VERSION ""

NS_ :

BS_:

BU_: ESP dSpaceBox CALTOOL HED

BO_ 539 SAC_ERRORS: 8 HED
 SG_ SAC_E_MSW_AGE_WARN : 63|1@1+ (1,0) [0|1] ""  CALTOOL
 SG_ SAC_E_CELL_Over_Temperature : 62|1@1+ (1,0) [0|1] ""  CALTOOL
 SG_ SAC_E_CSC_Timeout : 61|1@1+ (1,0) [0|1] ""  CALTOOL
 SG_ SAC_E_CSC_Internal : 60|1@1+ (1,0) [0|1] ""  CALTOOL
 SG_ SAC_E_BAT_Over_Voltage : 59|1@1+ (1,0) [0|1] ""  CALTOOL
 SG_ SAC_E_PMB_Over_Current_discharg : 58|1@1+ (1,0) [0|1] ""  CALTOOL
 SG_ SAC_E_PMB_Over_Current_charge : 57|1@1+ (1,0) [0|1] ""  CALTOOL
 SG_ SAC_E_PMB_Over_Temperature_Shun : 56|1@1+ (1,0) [0|1] ""  CALTOOL
 SG_ SAC_E_MSW_AGE : 55|1@1+ (1,0) [0|1] ""  CALTOOL
 SG_ SAC_E_PMB_Internal : 54|1@1+ (1,0) [0|1] ""  CALTOOL
 SG_ SAC_E_SSV_WD : 53|1@1+ (1,0) [0|1] ""  CALTOOL
 SG_ SAC_E_SSV_Supply_Voltage : 52|1@1+ (1,0) [0|1] ""  CALTOOL
 SG_ SAC_E_FLASH_Monitor : 51|1@1+ (1,0) [0|1] ""  CALTOOL
 SG_ SAC_E_PMB_Emergency_short_sup : 50|1@1+ (1,0) [0|1] ""  CALTOOL
 SG_ SAC_E_SSV_Warning : 49|1@1+ (1,0) [0|1] ""  CALTOOL
 SG_ SAC_E_SSV_Emergency : 48|1@1+ (1,0) [0|1] ""  CALTOOL
 SG_ SAC_E_Ref_Voltage : 47|1@1+ (1,0) [0|1] ""  CALTOOL
 SG_ SAC_E_Supply_Voltage : 46|1@1+ (1,0) [0|1] ""  CALTOOL
 SG_ SAC_E_BCC_communication : 45|1@1+ (1,0) [0|1] ""  CALTOOL
 SG_ SAC_E_CSC_Emergency_short_sup : 44|1@1+ (1,0) [0|1] ""  CALTOOL
 SG_ SAC_E_SSV_CONFIG_HARD : 43|1@1+ (1,0) [0|1] ""  CALTOOL
 SG_ SAC_E_PMB_Warning : 41|1@1+ (1,0) [0|1] ""  CALTOOL
 SG_ SAC_E_STACK_Monitor : 40|1@1+ (1,0) [0|1] ""  CALTOOL
 SG_ SAC_E_RAM_Monitor : 39|1@1+ (1,0) [0|1] ""  CALTOOL
 SG_ SAC_E_ROM_Monitor : 38|1@1+ (1,0) [0|1] ""  CALTOOL
 SG_ SAC_E_Reset_Monitor : 37|1@1+ (1,0) [0|1] ""  CALTOOL
 SG_ SAC_E_CPU_Test : 36|1@1+ (1,0) [0|1] ""  CALTOOL
 SG_ SAC_E_WD : 35|1@1+ (1,0) [0|1] ""  CALTOOL
 SG_ SAC_E_Trac_Voltage : 34|1@1+ (1,0) [0|1] ""  CALTOOL
 SG_ SAC_E_HV_meas : 33|1@1+ (1,0) [0|1] ""  CALTOOL
 SG_ SAC_E_Lifedata : 32|1@1+ (1,0) [0|1] ""  CALTOOL
 SG_ SAC_E_NVRAM : 31|1@1+ (1,0) [0|1] ""  CALTOOL
 SG_ SAC_E_PMB_Limits : 30|1@1+ (1,0) [0|1] ""  CALTOOL
 SG_ SAC_E_PCB_Temperature : 29|1@1+ (1,0) [0|1] ""  CALTOOL
 SG_ SAC_E_Iso_measurement : 28|1@1+ (1,0) [0|1] ""  CALTOOL
 SG_ SAC_E_SSV_Interop : 27|1@1+ (1,0) [0|1] ""  CALTOOL
 SG_ SAC_E_PMB_Timeout : 26|1@1+ (1,0) [0|1] ""  CALTOOL
 SG_ SAC_E_Interlock_missing : 25|1@1+ (1,0) [0|1] ""  CALTOOL
 SG_ SAC_E_PMB_Emergency : 24|1@1+ (1,0) [0|1] ""  CALTOOL
 SG_ SAC_E_CSC_Emergency : 23|1@1+ (1,0) [0|1] ""  CALTOOL
 SG_ SAC_E_FLOW_CTR : 22|1@1+ (1,0) [0|1] ""  CALTOOL
 SG_ SAC_E_ACC_Emergency : 21|1@1+ (1,0) [0|1] ""  CALTOOL
 SG_ SAC_E_Iso_resistance : 20|1@1+ (1,0) [0|1] ""  CALTOOL
 SG_ SAC_E_SSV_Timeout : 19|1@1+ (1,0) [0|1] ""  CALTOOL
 SG_ SAC_E_CSC_Warning : 18|1@1+ (1,0) [0|1] ""  CALTOOL
 SG_ SAC_E_CELL_Under_Voltage : 17|1@1+ (1,0) [0|1] ""  CALTOOL
 SG_ SAC_E_CELL_Over_Voltage : 16|1@1+ (1,0) [0|1] ""  CALTOOL

BO_ 309 BCC_IN_T_BATT_05_06: 8 HED
 SG_ BCC_T_Batt_06 : 32|16@1- (0.01,0) [-327.68|327.67] "°C"  CALTOOL
 SG_ BCC_T_Batt_05 : 0|16@1- (0.01,0) [-327.68|327.67] "°C"  CALTOOL

BO_ 308 BCC_IN_T_BATT_03_04: 8 HED
 SG_ BCC_T_Batt_04 : 32|16@1- (0.01,0) [-327.68|327.67] "°C"  CALTOOL
 SG_ BCC_T_Batt_03 : 0|16@1- (0.01,0) [-327.68|327.67] "°C"  CALTOOL

BO_ 307 BCC_IN_T_BATT_01_02: 8 HED
 SG_ BCC_T_Batt_02 : 32|16@1- (0.01,0) [-327.68|327.67] "°C"  CALTOOL
 SG_ BCC_T_Batt_01 : 0|16@1- (0.01,0) [-327.68|327.67] "°C"  CALTOOL

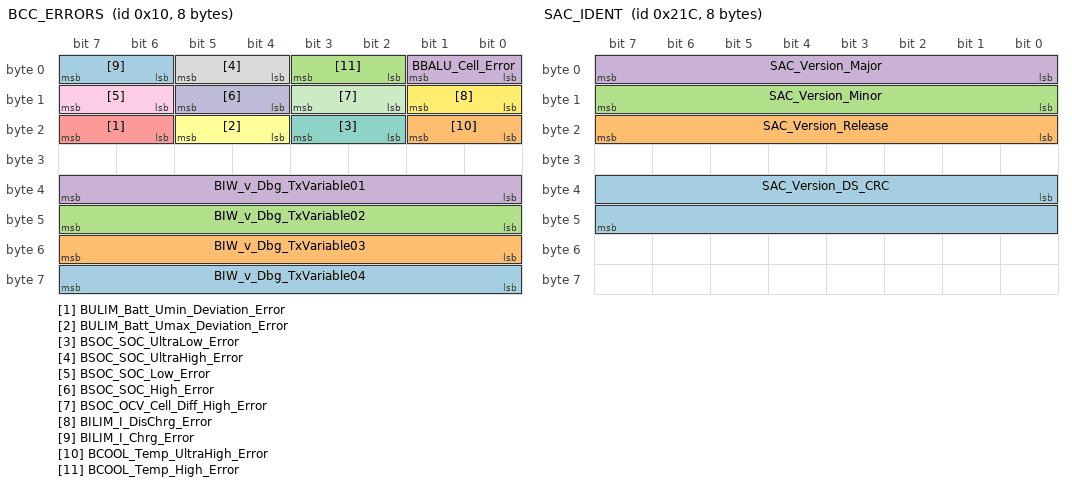
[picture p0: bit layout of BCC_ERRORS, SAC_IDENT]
BO_ 16 BCC_ERRORS: 8 HED
 SG_ BIW_v_Dbg_TxVariable04 : 56|8@1+ (1,0) [0|255] ""  CALTOOL
 SG_ BIW_v_Dbg_TxVariable03 : 48|8@1+ (1,0) [0|255] ""  CALTOOL
 SG_ BIW_v_Dbg_TxVariable02 : 40|8@1+ (1,0) [0|255] ""  CALTOOL
 SG_ BIW_v_Dbg_TxVariable01 : 32|8@1+ (1,0) [0|255] ""  CALTOOL
 SG_ BULIM_Batt_Umin_Deviation_Error : 22|2@1+ (1,0) [0|3] ""  CALTOOL
 SG_ BULIM_Batt_Umax_Deviation_Error : 20|2@1+ (1,0) [0|3] ""  CALTOOL
 SG_ BSOC_SOC_UltraLow_Error : 18|2@1+ (1,0) [0|3] ""  CALTOOL
 SG_ BSOC_SOC_UltraHigh_Error : 4|2@1+ (1,0) [0|3] ""  CALTOOL
 SG_ BSOC_SOC_Low_Error : 14|2@1+ (1,0) [0|3] ""  CALTOOL
 SG_ BSOC_SOC_High_Error : 12|2@1+ (1,0) [0|3] ""  CALTOOL
 SG_ BSOC_OCV_Cell_Diff_High_Error : 10|2@1+ (1,0) [0|3] ""  CALTOOL
 SG_ BILIM_I_DisChrg_Error : 8|2@1+ (1,0) [0|3] ""  CALTOOL
 SG_ BILIM_I_Chrg_Error : 6|2@1+ (1,0) [0|3] ""  CALTOOL
 SG_ BCOOL_Temp_UltraHigh_Error : 16|2@1+ (1,0) [0|3] ""  CALTOOL
 SG_ BCOOL_Temp_High_Error : 2|2@1+ (1,0) [0|0] ""  CALTOOL
 SG_ BBALU_Cell_Error : 0|2@1+ (1,0) [0|0] ""  CALTOOL

BO_ 547 SAC_STATES: 8 HED
 SG_ SAC_S_RTC_LOW_VOLT : 55|1@1+ (1,0) [0|0] ""  CALTOOL
 SG_ SAC_S_SOFTWARE_RESET_PERFORMED : 54|1@1+ (1,0) [0|0] ""  CALTOOL
 SG_ SAC_S_ISO_GND_WARNING : 53|1@1+ (1,0) [0|0] ""  CALTOOL
 SG_ SAC_S_DISCHARGE_COMPLETED : 52|1@1+ (1,0) [0|0] ""  CALTOOL
 SG_ SAC_S_DISCHARGE : 51|1@1+ (1,0) [0|0] ""  CALTOOL
 SG_ SAC_S_PMB_CAN_ACTIVE : 50|1@1+ (1,0) [0|0] ""  CALTOOL
 SG_ SAC_S_CSC_CAN_ACTIVE : 49|1@1+ (1,0) [0|0] ""  CALTOOL
 SG_ SAC_S_CAN_WAKEUP : 48|1@1+ (1,0) [0|0] ""  CALTOOL
 SG_ SAC_S_CLOSE_NOT_POSSIBLE_WEAK : 47|1@1+ (1,0) [0|0] ""  CALTOOL
 SG_ SAC_S_SC_MSW_3_CLOSE : 46|1@1+ (1,0) [0|0] ""  CALTOOL
 SG_ SAC_S_ISO_TEST_ACTIVE : 45|1@1+ (1,0) [0|0] ""  CALTOOL
 SG_ SAC_S_SC_PMB_EN : 44|1@1+ (1,0) [0|0] ""  CALTOOL
 SG_ SAC_S_SC_CSC_EN : 43|1@1+ (1,0) [0|0] ""  CALTOOL
 SG_ SAC_S_HV_EN : 42|1@1+ (1,0) [0|0] ""  CALTOOL
 SG_ SAC_S_MEAS_CAN_WARN : 40|1@1+ (1,0) [0|0] ""  CALTOOL
 SG_ SAC_S_CSC_RESET : 39|1@1+ (1,0) [0|0] ""  CALTOOL
 SG_ SAC_S_CSC_SYNC : 38|1@1+ (1,0) [0|0] ""  CALTOOL
 SG_ SAC_S_PMB_RESET : 37|1@1+ (1,0) [0|0] ""  CALTOOL
 SG_ SAC_S_PMB_SYNC : 36|1@1+ (1,0) [0|0] ""  CALTOOL
 SG_ SAC_S_SC_KL30c_EN : 35|1@1+ (1,0) [0|0] ""  CALTOOL
 SG_ SAC_S_RTC_WAKEUP_DETECTED : 34|1@1+ (1,0) [0|0] ""  CALTOOL
 SG_ SAC_S_RTC_WAKEUP_DELAY_SET : 33|1@1+ (1,0) [0|0] ""  CALTOOL
 SG_ SAC_S_RTC_READY : 32|1@1+ (1,0) [0|0] ""  CALTOOL
 SG_ SAC_S_ISO_VALUE_VALID : 31|1@1+ (1,0) [0|0] ""  CALTOOL
 SG_ SAC_S_ISO_EN : 30|1@1+ (1,0) [0|0] ""  CALTOOL
 SG_ SAC_S_PRECH_COMPLETED : 29|1@1+ (1,0) [0|0] ""  CALTOOL
 SG_ SAC_S_PREC_ACTIVE : 28|1@1+ (1,0) [0|0] ""  CALTOOL
 SG_ SAC_S_COOLING : 27|1@1+ (1,0) [0|0] ""  CALTOOL
 SG_ SAC_S_STUCKTEST_READY : 26|1@1+ (1,0) [0|0] ""  CALTOOL
 SG_ SAC_S_SKT_CONDITIONS : 25|1@1+ (1,0) [0|0] ""  CALTOOL
 SG_ SAC_S_MSW_SUPPLY : 24|1@1+ (1,0) [0|0] ""  CALTOOL
 SG_ SAC_S_ISO_RES_WARNING : 23|1@1+ (1,0) [0|0] ""  CALTOOL
 SG_ SAC_S_SC_MSW_PLUS_CLOSE : 22|1@1+ (1,0) [0|0] ""  CALTOOL
 SG_ SAC_S_SC_MSW_MINUS_CLOSE : 21|1@1+ (1,0) [0|0] ""  CALTOOL
 SG_ SAC_S_MONITORING : 20|1@1+ (1,0) [0|0] ""  CALTOOL
 SG_ SAC_S_SYS_ENABLE : 19|1@1+ (1,0) [0|0] ""  CALTOOL
 SG_ SAC_S_START_UP_TEST : 18|1@1+ (1,0) [0|0] ""  CALTOOL
 SG_ SAC_S_EMERGENCY_OPEN : 17|1@1+ (1,0) [0|0] ""  CALTOOL
 SG_ SAC_S_GENERAL_ERROR : 16|1@1+ (1,0) [0|0] ""  CALTOOL

BO_ 540 SAC_IDENT: 8 HED
 SG_ SAC_Version_DS_CRC : 32|16@1+ (1,0) [0|65535] ""  CALTOOL
 SG_ SAC_Version_Release : 16|8@1+ (1,0) [0|255] ""  CALTOOL
 SG_ SAC_Version_Minor : 8|8@1+ (1,0) [0|0] ""  CALTOOL
 SG_ SAC_Version_Major : 0|8@1+ (1,0) [0|255] ""  CALTOOL

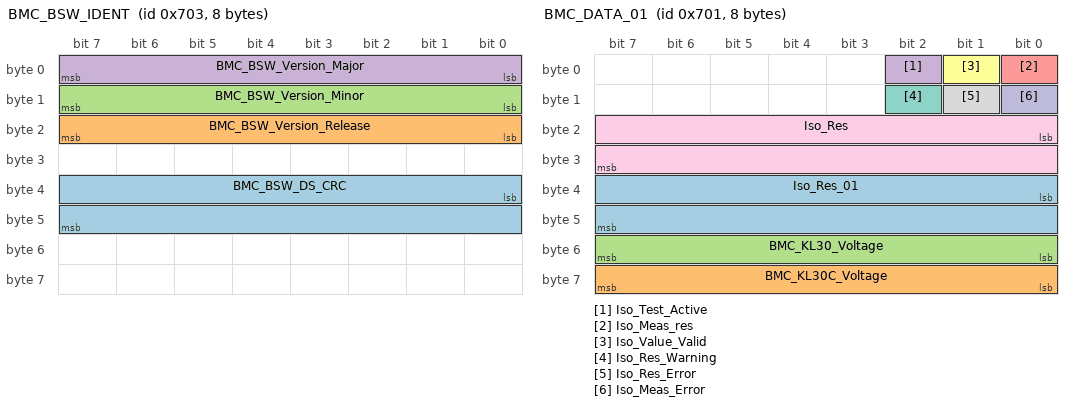
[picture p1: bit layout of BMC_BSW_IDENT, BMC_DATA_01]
BO_ 1795 BMC_BSW_IDENT: 8 HED
 SG_ BMC_BSW_DS_CRC : 32|16@1+ (1,0) [0|65535] ""  CALTOOL
 SG_ BMC_BSW_Version_Release : 16|8@1+ (1,0) [0|255] ""  CALTOOL
 SG_ BMC_BSW_Version_Minor : 8|8@1+ (1,0) [0|0] ""  CALTOOL
 SG_ BMC_BSW_Version_Major : 0|8@1+ (1,0) [0|255] ""  CALTOOL

BO_ 1793 BMC_DATA_01: 8 HED
 SG_ Iso_Res_01 : 32|16@1+ (1,0) [0|0] "Ohm/V" Vector__XXX
 SG_ BMC_KL30C_Voltage : 56|8@1+ (0.1,0) [0|25.5] "V"  CALTOOL
 SG_ BMC_KL30_Voltage : 48|8@1+ (0.1,0) [0|25.5] "V"  CALTOOL
 SG_ Iso_Test_Active : 2|1@1+ (1,0) [0|0] ""  CALTOOL
 SG_ Iso_Meas_res : 0|1@1+ (1,0) [0|0] ""  CALTOOL
 SG_ Iso_Value_Valid : 1|1@1+ (1,0) [0|0] ""  CALTOOL
 SG_ Iso_Res_Warning : 10|1@1+ (1,0) [0|0] ""  CALTOOL
 SG_ Iso_Res_Error : 9|1@1+ (1,0) [0|0] ""  CALTOOL
 SG_ Iso_Res : 16|16@1+ (1,0) [0|0] "kOhm"  CALTOOL
 SG_ Iso_Meas_Error : 8|1@1+ (1,0) [0|0] ""  CALTOOL

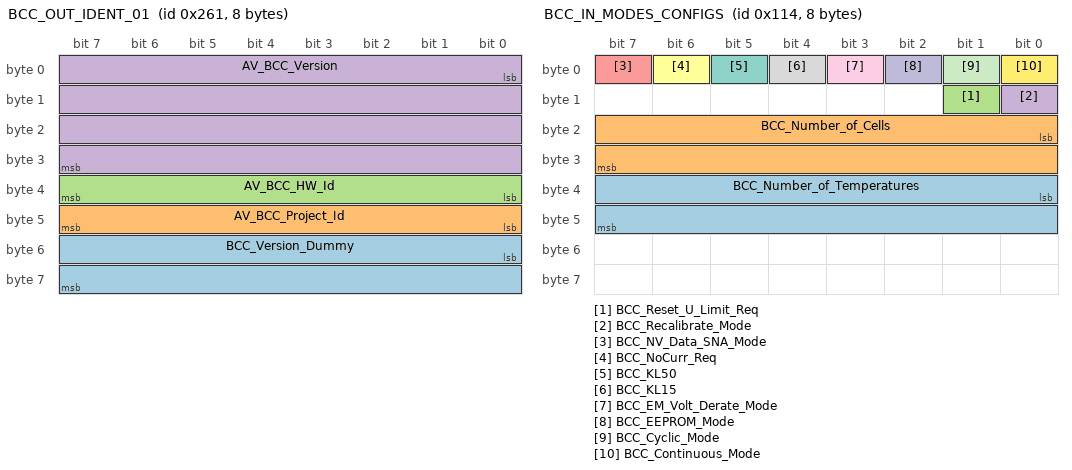
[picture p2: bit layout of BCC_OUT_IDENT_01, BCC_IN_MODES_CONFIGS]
BO_ 609 BCC_OUT_IDENT_01: 8 HED
 SG_ BCC_Version_Dummy : 48|16@1+ (1,0) [0|0] ""  CALTOOL
 SG_ AV_BCC_Project_Id : 40|8@1+ (1,0) [0|255] ""  CALTOOL
 SG_ AV_BCC_HW_Id : 32|8@1+ (1,0) [0|255] ""  CALTOOL
 SG_ AV_BCC_Version : 0|32@1+ (1,0) [0|4294967295] ""  CALTOOL

BO_ 661 BCC_SW_MODE_INF: 8 HED
 SG_ SW_Wakeup_by_RTC : 8|8@1- (1,0) [0|0] ""  CALTOOL
 SG_ SW_OP_Mode : 0|8@1+ (1,0) [0|0] ""  CALTOOL

BO_ 279 BCC_IN_TIME_SWITCH_OPENED: 8 HED
 SG_ BCC_Time_Sw_Open : 0|32@1+ (1,0) [0|4294967295] "s"  CALTOOL

BO_ 276 BCC_IN_MODES_CONFIGS: 8 HED
 SG_ BCC_Number_of_Temperatures : 32|16@1+ (1,0) [0|65535] ""  CALTOOL
 SG_ BCC_Number_of_Cells : 16|16@1+ (1,0) [0|65535] ""  CALTOOL
 SG_ BCC_Reset_U_Limit_Req : 9|1@1+ (1,0) [0|0] ""  CALTOOL
 SG_ BCC_Recalibrate_Mode : 8|1@1+ (1,0) [0|0] ""  CALTOOL
 SG_ BCC_NV_Data_SNA_Mode : 7|1@1+ (1,0) [0|0] ""  CALTOOL
 SG_ BCC_NoCurr_Req : 6|1@1+ (1,0) [0|0] ""  CALTOOL
 SG_ BCC_KL50 : 5|1@1+ (1,0) [0|0] ""  CALTOOL
 SG_ BCC_KL15 : 4|1@1+ (1,0) [0|0] ""  CALTOOL
 SG_ BCC_EM_Volt_Derate_Mode : 3|1@1+ (1,0) [0|0] ""  CALTOOL
 SG_ BCC_EEPROM_Mode : 2|1@1+ (1,0) [0|0] ""  CALTOOL
 SG_ BCC_Cyclic_Mode : 1|1@1+ (1,0) [0|0] ""  CALTOOL
 SG_ BCC_Continuous_Mode : 0|1@1+ (1,0) [0|0] ""  CALTOOL

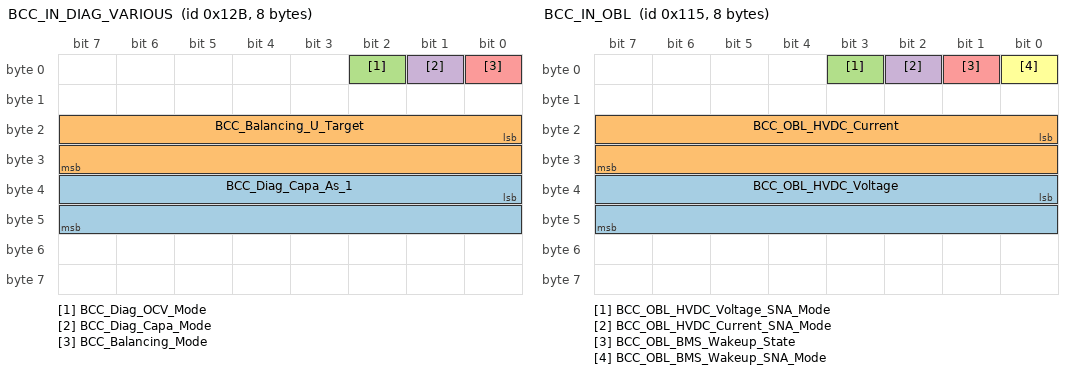
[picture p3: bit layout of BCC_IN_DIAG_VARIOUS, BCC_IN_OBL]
BO_ 299 BCC_IN_DIAG_VARIOUS: 8 HED
 SG_ BCC_Diag_Capa_As_1 : 32|16@1+ (1,0) [0|65535] "As"  CALTOOL
 SG_ BCC_Balancing_U_Target : 16|16@1+ (1,0) [0|65535] ""  CALTOOL
 SG_ BCC_Diag_OCV_Mode : 2|1@1+ (1,0) [0|0] ""  CALTOOL
 SG_ BCC_Diag_Capa_Mode : 1|1@1+ (1,0) [0|0] ""  CALTOOL
 SG_ BCC_Balancing_Mode : 0|1@1+ (1,0) [0|0] ""  CALTOOL

BO_ 277 BCC_IN_OBL: 8 HED
 SG_ BCC_OBL_HVDC_Voltage : 32|16@1+ (1,0) [0|65535] "A"  CALTOOL
 SG_ BCC_OBL_HVDC_Current : 16|16@1+ (0.1,0) [0|6553.5] "A"  CALTOOL
 SG_ BCC_OBL_HVDC_Voltage_SNA_Mode : 3|1@1+ (1,0) [0|0] ""  CALTOOL
 SG_ BCC_OBL_HVDC_Current_SNA_Mode : 2|1@1+ (1,0) [0|0] ""  CALTOOL
 SG_ BCC_OBL_BMS_Wakeup_State : 1|1@1+ (1,0) [0|0] ""  CALTOOL
 SG_ BCC_OBL_BMS_Wakeup_SNA_Mode : 0|1@1+ (1,0) [0|0] ""  CALTOOL

BO_ 278 BCC_IN_RTC: 8 HED
 SG_ BCC_RTC : 16|32@1+ (1,0) [0|4294967295] "s"  CALTOOL
 SG_ BCC_RTC_SNA_Mode : 0|1@1+ (1,0) [0|0] ""  CALTOOL

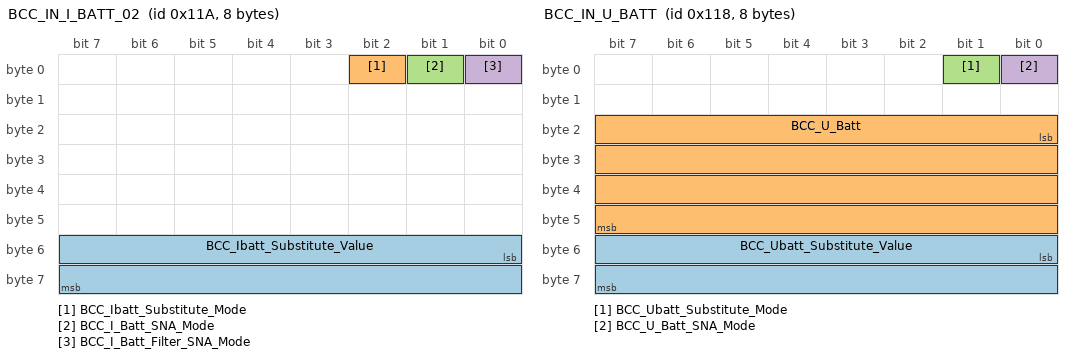
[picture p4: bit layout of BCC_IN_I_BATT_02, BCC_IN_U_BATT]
BO_ 282 BCC_IN_I_BATT_02: 8 HED
 SG_ BCC_Ibatt_Substitute_Value : 48|16@1+ (0.1,-819.2) [-819.2|819] "A"  CALTOOL
 SG_ BCC_Ibatt_Substitute_Mode : 2|1@1+ (1,0) [0|0] ""  CALTOOL
 SG_ BCC_I_Batt_SNA_Mode : 1|1@1+ (1,0) [0|0] ""  CALTOOL
 SG_ BCC_I_Batt_Filter_SNA_Mode : 0|1@1+ (1,0) [0|0] ""  CALTOOL

BO_ 306 BCC_IN_T_COOL_INLET: 8 HED
 SG_ BCC_CoolantInletTemp : 0|32@1- (0.0009765625,0) [-2097152|2097151.999] "°C"  CALTOOL

BO_ 281 BCC_IN_I_BATT_01: 8 HED
 SG_ BCC_I_Batt_Filtered : 32|32@1- (0.0009765625,0) [-2097152|2097151.999] "A"  CALTOOL
 SG_ BCC_I_Batt : 0|32@1- (0.0009765625,0) [-2097152|2097151.999] "A"  CALTOOL

BO_ 280 BCC_IN_U_BATT: 8 HED
 SG_ BCC_Ubatt_Substitute_Value : 48|16@1+ (0.1,0) [0|819] "V"  CALTOOL
 SG_ BCC_U_Batt : 16|32@1- (0.0009765625,0) [-2097152|2097151.99902344] "V"  CALTOOL
 SG_ BCC_Ubatt_Substitute_Mode : 1|1@1+ (1,0) [0|0] ""  CALTOOL
 SG_ BCC_U_Batt_SNA_Mode : 0|1@1+ (1,0) [0|0] ""  CALTOOL

BO_ 305 BCC_IN_T_COOL_AMB: 8 HED
 SG_ BCC_T_Cool : 16|32@1- (0.0009765625,0) [-2097152|2097151.99902344] "°C"  CALTOOL
 SG_ BCC_T_Amb : 8|8@1+ (0.5,-40) [-40|85] "°C"  CALTOOL
 SG_ BCC_T_Cool_SNA_Mode : 0|1@1+ (1,0) [0|0] ""  CALTOOL

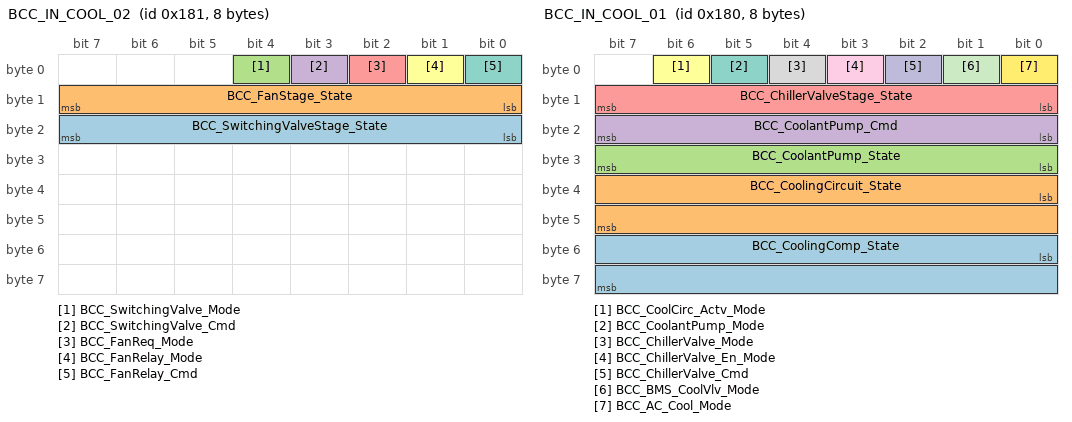
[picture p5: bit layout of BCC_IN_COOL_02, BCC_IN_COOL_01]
BO_ 385 BCC_IN_COOL_02: 8 HED
 SG_ BCC_SwitchingValveStage_State : 16|8@1+ (1,0) [0|255] ""  CALTOOL
 SG_ BCC_FanStage_State : 8|8@1+ (1,0) [0|255] ""  CALTOOL
 SG_ BCC_SwitchingValve_Mode : 4|1@1+ (1,0) [0|0] ""  CALTOOL
 SG_ BCC_SwitchingValve_Cmd : 3|1@1+ (1,0) [0|0] ""  CALTOOL
 SG_ BCC_FanReq_Mode : 2|1@1+ (1,0) [0|0] ""  CALTOOL
 SG_ BCC_FanRelay_Mode : 1|1@1+ (1,0) [0|0] ""  CALTOOL
 SG_ BCC_FanRelay_Cmd : 0|1@1+ (1,0) [0|0] ""  CALTOOL

BO_ 384 BCC_IN_COOL_01: 8 HED
 SG_ BCC_CoolingComp_State : 48|16@1+ (1,0) [0|65535] ""  CALTOOL
 SG_ BCC_CoolingCircuit_State : 32|16@1+ (1,0) [0|65535] ""  CALTOOL
 SG_ BCC_CoolantPump_State : 24|8@1+ (1,0) [0|255] "%"  CALTOOL
 SG_ BCC_CoolantPump_Cmd : 16|8@1+ (1,0) [0|255] "%"  CALTOOL
 SG_ BCC_ChillerValveStage_State : 8|8@1+ (1,0) [0|255] ""  CALTOOL
 SG_ BCC_CoolCirc_Actv_Mode : 6|1@1+ (1,0) [0|0] ""  CALTOOL
 SG_ BCC_CoolantPump_Mode : 5|1@1+ (1,0) [0|0] ""  CALTOOL
 SG_ BCC_ChillerValve_Mode : 4|1@1+ (1,0) [0|0] ""  CALTOOL
 SG_ BCC_ChillerValve_En_Mode : 3|1@1+ (1,0) [0|0] ""  CALTOOL
 SG_ BCC_ChillerValve_Cmd : 2|1@1+ (1,0) [0|0] ""  CALTOOL
 SG_ BCC_BMS_CoolVlv_Mode : 1|1@1+ (1,0) [0|0] ""  CALTOOL
 SG_ BCC_AC_Cool_Mode : 0|1@1+ (1,0) [0|0] ""  CALTOOL

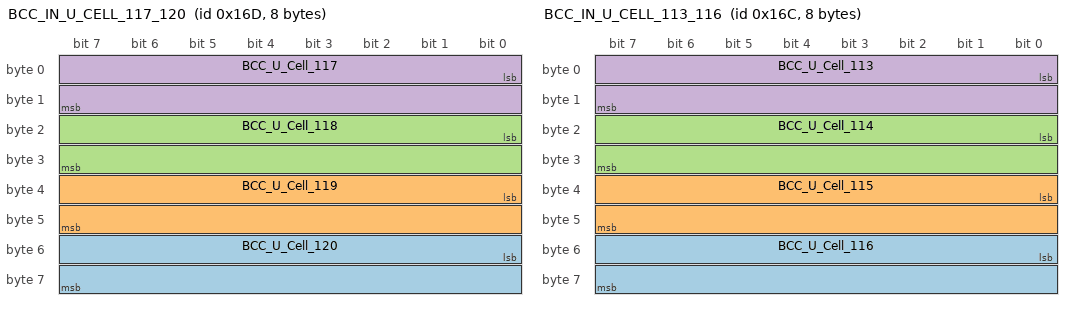
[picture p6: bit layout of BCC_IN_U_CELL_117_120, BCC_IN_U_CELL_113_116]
BO_ 365 BCC_IN_U_CELL_117_120: 8 HED
 SG_ BCC_U_Cell_120 : 48|16@1+ (1,0) [0|6000] "mV"  CALTOOL
 SG_ BCC_U_Cell_119 : 32|16@1+ (1,0) [0|6000] "mV"  CALTOOL
 SG_ BCC_U_Cell_118 : 16|16@1+ (1,0) [0|6000] "mV"  CALTOOL
 SG_ BCC_U_Cell_117 : 0|16@1+ (1,0) [0|6000] "mV"  CALTOOL

BO_ 364 BCC_IN_U_CELL_113_116: 8 HED
 SG_ BCC_U_Cell_116 : 48|16@1+ (1,0) [0|6000] "mV"  CALTOOL
 SG_ BCC_U_Cell_115 : 32|16@1+ (1,0) [0|6000] "mV"  CALTOOL
 SG_ BCC_U_Cell_114 : 16|16@1+ (1,0) [0|6000] "mV"  CALTOOL
 SG_ BCC_U_Cell_113 : 0|16@1+ (1,0) [0|6000] "mV"  CALTOOL

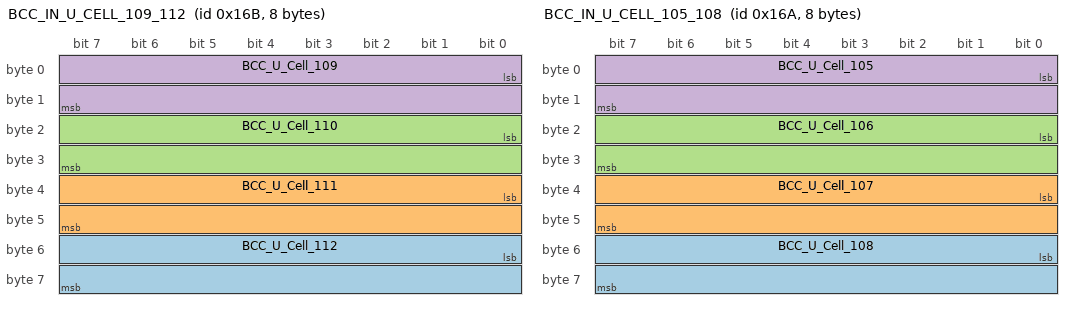
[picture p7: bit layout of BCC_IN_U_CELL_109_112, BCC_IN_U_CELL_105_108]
BO_ 363 BCC_IN_U_CELL_109_112: 8 HED
 SG_ BCC_U_Cell_112 : 48|16@1+ (1,0) [0|6000] "mV"  CALTOOL
 SG_ BCC_U_Cell_111 : 32|16@1+ (1,0) [0|6000] "mV"  CALTOOL
 SG_ BCC_U_Cell_110 : 16|16@1+ (1,0) [0|6000] "mV"  CALTOOL
 SG_ BCC_U_Cell_109 : 0|16@1+ (1,0) [0|6000] "mV"  CALTOOL

BO_ 362 BCC_IN_U_CELL_105_108: 8 HED
 SG_ BCC_U_Cell_108 : 48|16@1+ (1,0) [0|6000] "mV"  CALTOOL
 SG_ BCC_U_Cell_107 : 32|16@1+ (1,0) [0|6000] "mV"  CALTOOL
 SG_ BCC_U_Cell_106 : 16|16@1+ (1,0) [0|6000] "mV"  CALTOOL
 SG_ BCC_U_Cell_105 : 0|16@1+ (1,0) [0|6000] "mV"  CALTOOL

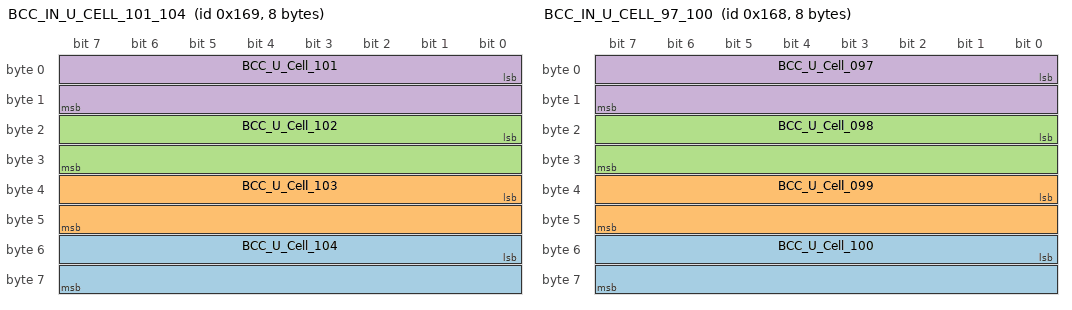
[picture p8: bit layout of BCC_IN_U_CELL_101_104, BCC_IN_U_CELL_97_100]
BO_ 361 BCC_IN_U_CELL_101_104: 8 HED
 SG_ BCC_U_Cell_104 : 48|16@1+ (1,0) [0|6000] "mV"  CALTOOL
 SG_ BCC_U_Cell_103 : 32|16@1+ (1,0) [0|6000] "mV"  CALTOOL
 SG_ BCC_U_Cell_102 : 16|16@1+ (1,0) [0|6000] "mV"  CALTOOL
 SG_ BCC_U_Cell_101 : 0|16@1+ (1,0) [0|6000] "mV"  CALTOOL

BO_ 360 BCC_IN_U_CELL_97_100: 8 HED
 SG_ BCC_U_Cell_100 : 48|16@1+ (1,0) [0|6000] "mV"  CALTOOL
 SG_ BCC_U_Cell_099 : 32|16@1+ (1,0) [0|6000] "mV"  CALTOOL
 SG_ BCC_U_Cell_098 : 16|16@1+ (1,0) [0|6000] "mV"  CALTOOL
 SG_ BCC_U_Cell_097 : 0|16@1+ (1,0) [0|6000] "mV"  CALTOOL

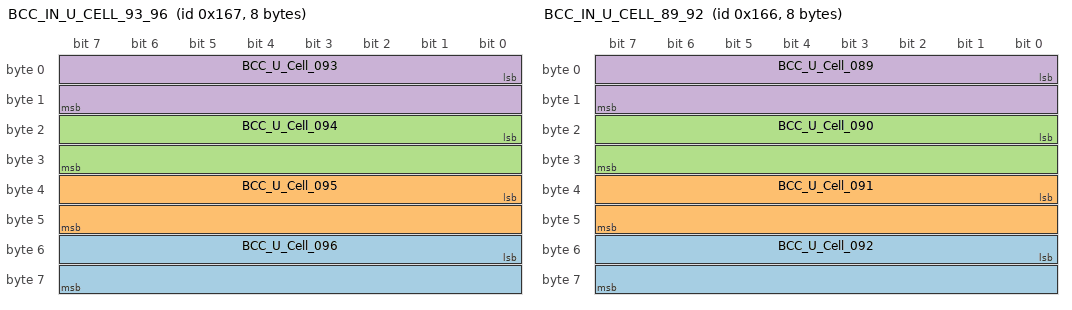
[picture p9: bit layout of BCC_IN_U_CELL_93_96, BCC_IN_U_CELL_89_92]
BO_ 359 BCC_IN_U_CELL_93_96: 8 HED
 SG_ BCC_U_Cell_096 : 48|16@1+ (1,0) [0|6000] "mV"  CALTOOL
 SG_ BCC_U_Cell_095 : 32|16@1+ (1,0) [0|6000] "mV"  CALTOOL
 SG_ BCC_U_Cell_094 : 16|16@1+ (1,0) [0|6000] "mV"  CALTOOL
 SG_ BCC_U_Cell_093 : 0|16@1+ (1,0) [0|6000] "mV"  CALTOOL

BO_ 358 BCC_IN_U_CELL_89_92: 8 HED
 SG_ BCC_U_Cell_092 : 48|16@1+ (1,0) [0|6000] "mV"  CALTOOL
 SG_ BCC_U_Cell_091 : 32|16@1+ (1,0) [0|6000] "mV"  CALTOOL
 SG_ BCC_U_Cell_090 : 16|16@1+ (1,0) [0|6000] "mV"  CALTOOL
 SG_ BCC_U_Cell_089 : 0|16@1+ (1,0) [0|6000] "mV"  CALTOOL

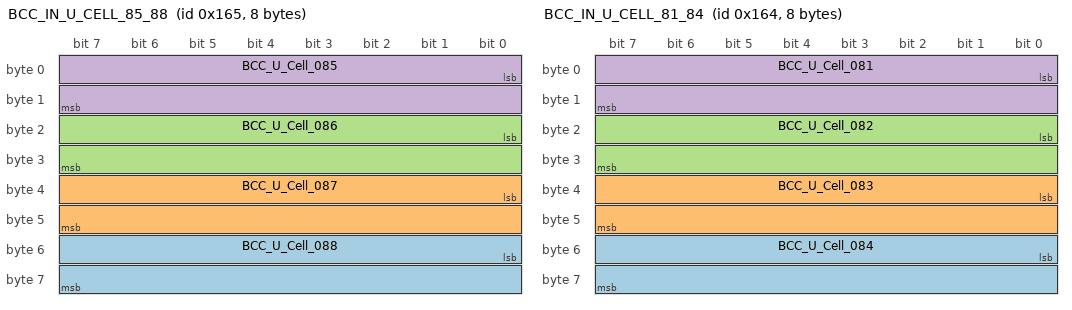
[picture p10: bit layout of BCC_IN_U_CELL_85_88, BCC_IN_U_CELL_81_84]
BO_ 357 BCC_IN_U_CELL_85_88: 8 HED
 SG_ BCC_U_Cell_088 : 48|16@1+ (1,0) [0|6000] "mV"  CALTOOL
 SG_ BCC_U_Cell_087 : 32|16@1+ (1,0) [0|6000] "mV"  CALTOOL
 SG_ BCC_U_Cell_086 : 16|16@1+ (1,0) [0|6000] "mV"  CALTOOL
 SG_ BCC_U_Cell_085 : 0|16@1+ (1,0) [0|6000] "mV"  CALTOOL

BO_ 356 BCC_IN_U_CELL_81_84: 8 HED
 SG_ BCC_U_Cell_084 : 48|16@1+ (1,0) [0|6000] "mV"  CALTOOL
 SG_ BCC_U_Cell_083 : 32|16@1+ (1,0) [0|6000] "mV"  CALTOOL
 SG_ BCC_U_Cell_082 : 16|16@1+ (1,0) [0|6000] "mV"  CALTOOL
 SG_ BCC_U_Cell_081 : 0|16@1+ (1,0) [0|6000] "mV"  CALTOOL

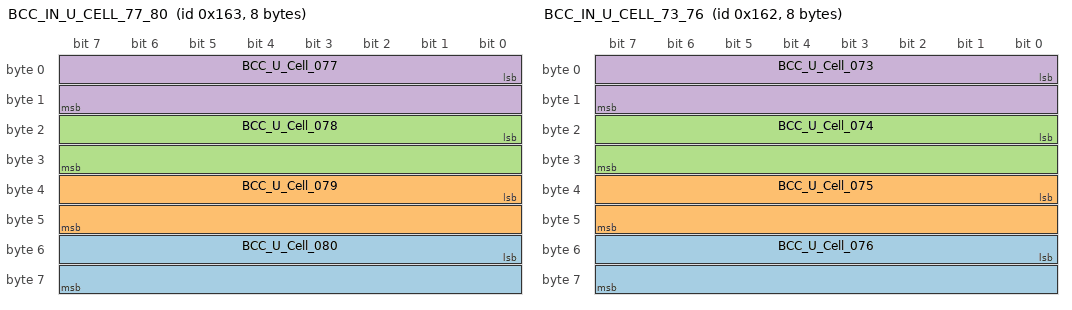
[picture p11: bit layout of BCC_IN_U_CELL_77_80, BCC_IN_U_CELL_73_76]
BO_ 355 BCC_IN_U_CELL_77_80: 8 HED
 SG_ BCC_U_Cell_080 : 48|16@1+ (1,0) [0|6000] "mV"  CALTOOL
 SG_ BCC_U_Cell_079 : 32|16@1+ (1,0) [0|6000] "mV"  CALTOOL
 SG_ BCC_U_Cell_078 : 16|16@1+ (1,0) [0|6000] "mV"  CALTOOL
 SG_ BCC_U_Cell_077 : 0|16@1+ (1,0) [0|6000] "mV"  CALTOOL

BO_ 354 BCC_IN_U_CELL_73_76: 8 HED
 SG_ BCC_U_Cell_076 : 48|16@1+ (1,0) [0|6000] "mV"  CALTOOL
 SG_ BCC_U_Cell_075 : 32|16@1+ (1,0) [0|6000] "mV"  CALTOOL
 SG_ BCC_U_Cell_074 : 16|16@1+ (1,0) [0|6000] "mV"  CALTOOL
 SG_ BCC_U_Cell_073 : 0|16@1+ (1,0) [0|6000] "mV"  CALTOOL

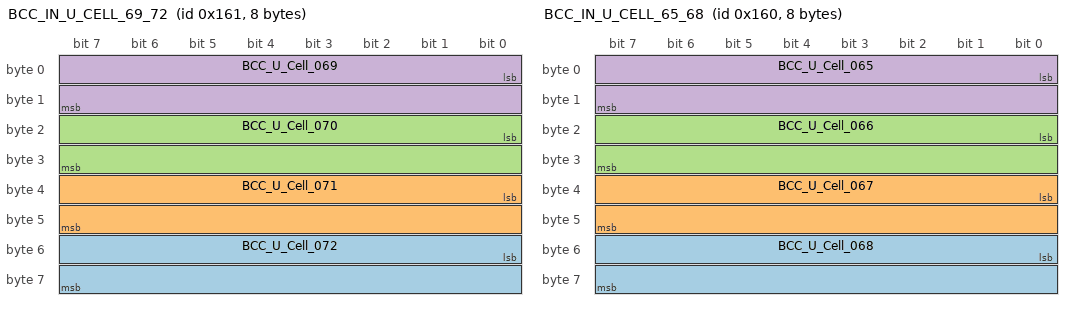
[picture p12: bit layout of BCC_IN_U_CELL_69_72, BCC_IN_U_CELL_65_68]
BO_ 353 BCC_IN_U_CELL_69_72: 8 HED
 SG_ BCC_U_Cell_072 : 48|16@1+ (1,0) [0|6000] "mV"  CALTOOL
 SG_ BCC_U_Cell_071 : 32|16@1+ (1,0) [0|6000] "mV"  CALTOOL
 SG_ BCC_U_Cell_070 : 16|16@1+ (1,0) [0|6000] "mV"  CALTOOL
 SG_ BCC_U_Cell_069 : 0|16@1+ (1,0) [0|6000] "mV"  CALTOOL

BO_ 352 BCC_IN_U_CELL_65_68: 8 HED
 SG_ BCC_U_Cell_068 : 48|16@1+ (1,0) [0|6000] "mV"  CALTOOL
 SG_ BCC_U_Cell_067 : 32|16@1+ (1,0) [0|6000] "mV"  CALTOOL
 SG_ BCC_U_Cell_066 : 16|16@1+ (1,0) [0|6000] "mV"  CALTOOL
 SG_ BCC_U_Cell_065 : 0|16@1+ (1,0) [0|6000] "mV"  CALTOOL

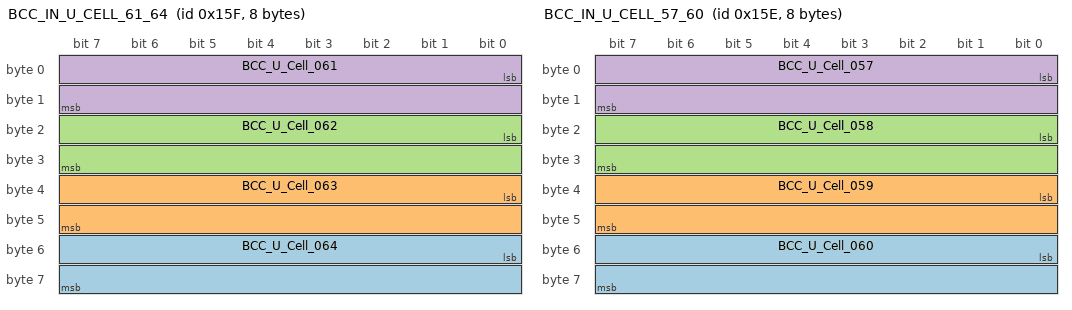
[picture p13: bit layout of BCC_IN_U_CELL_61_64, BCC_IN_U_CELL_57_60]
BO_ 351 BCC_IN_U_CELL_61_64: 8 HED
 SG_ BCC_U_Cell_064 : 48|16@1+ (1,0) [0|6000] "mV"  CALTOOL
 SG_ BCC_U_Cell_063 : 32|16@1+ (1,0) [0|6000] "mV"  CALTOOL
 SG_ BCC_U_Cell_062 : 16|16@1+ (1,0) [0|6000] "mV"  CALTOOL
 SG_ BCC_U_Cell_061 : 0|16@1+ (1,0) [0|6000] "mV"  CALTOOL

BO_ 350 BCC_IN_U_CELL_57_60: 8 HED
 SG_ BCC_U_Cell_060 : 48|16@1+ (1,0) [0|6000] "mV"  CALTOOL
 SG_ BCC_U_Cell_059 : 32|16@1+ (1,0) [0|6000] "mV"  CALTOOL
 SG_ BCC_U_Cell_058 : 16|16@1+ (1,0) [0|6000] "mV"  CALTOOL
 SG_ BCC_U_Cell_057 : 0|16@1+ (1,0) [0|6000] "mV"  CALTOOL

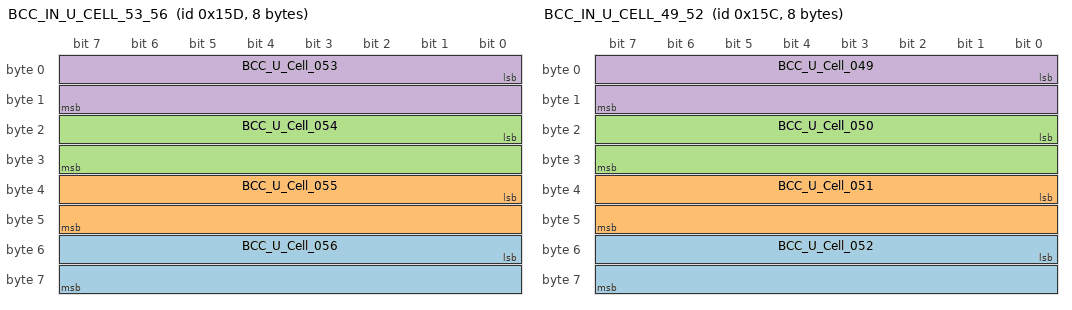
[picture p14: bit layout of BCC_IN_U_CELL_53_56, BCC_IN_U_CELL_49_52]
BO_ 349 BCC_IN_U_CELL_53_56: 8 HED
 SG_ BCC_U_Cell_056 : 48|16@1+ (1,0) [0|6000] "mV"  CALTOOL
 SG_ BCC_U_Cell_055 : 32|16@1+ (1,0) [0|6000] "mV"  CALTOOL
 SG_ BCC_U_Cell_054 : 16|16@1+ (1,0) [0|6000] "mV"  CALTOOL
 SG_ BCC_U_Cell_053 : 0|16@1+ (1,0) [0|6000] "mV"  CALTOOL

BO_ 348 BCC_IN_U_CELL_49_52: 8 HED
 SG_ BCC_U_Cell_052 : 48|16@1+ (1,0) [0|6000] "mV"  CALTOOL
 SG_ BCC_U_Cell_051 : 32|16@1+ (1,0) [0|6000] "mV"  CALTOOL
 SG_ BCC_U_Cell_050 : 16|16@1+ (1,0) [0|6000] "mV"  CALTOOL
 SG_ BCC_U_Cell_049 : 0|16@1+ (1,0) [0|6000] "mV"  CALTOOL

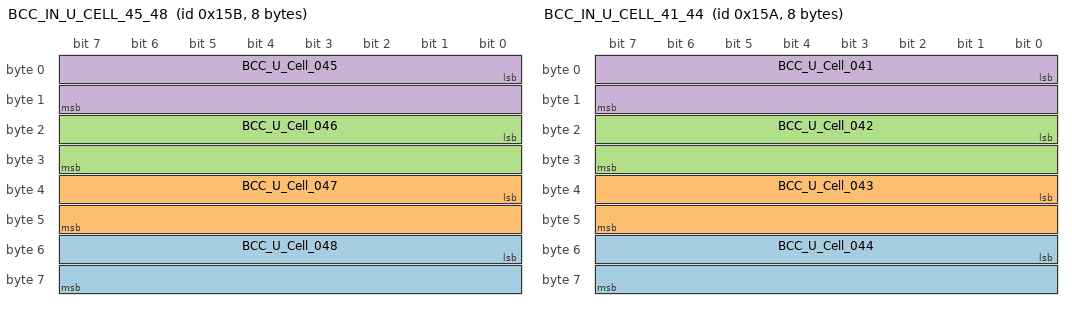
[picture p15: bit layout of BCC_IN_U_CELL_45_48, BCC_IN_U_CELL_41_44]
BO_ 347 BCC_IN_U_CELL_45_48: 8 HED
 SG_ BCC_U_Cell_048 : 48|16@1+ (1,0) [0|6000] "mV"  CALTOOL
 SG_ BCC_U_Cell_047 : 32|16@1+ (1,0) [0|6000] "mV"  CALTOOL
 SG_ BCC_U_Cell_046 : 16|16@1+ (1,0) [0|6000] "mV"  CALTOOL
 SG_ BCC_U_Cell_045 : 0|16@1+ (1,0) [0|6000] "mV"  CALTOOL

BO_ 346 BCC_IN_U_CELL_41_44: 8 HED
 SG_ BCC_U_Cell_044 : 48|16@1+ (1,0) [0|6000] "mV"  CALTOOL
 SG_ BCC_U_Cell_043 : 32|16@1+ (1,0) [0|6000] "mV"  CALTOOL
 SG_ BCC_U_Cell_042 : 16|16@1+ (1,0) [0|6000] "mV"  CALTOOL
 SG_ BCC_U_Cell_041 : 0|16@1+ (1,0) [0|6000] "mV"  CALTOOL

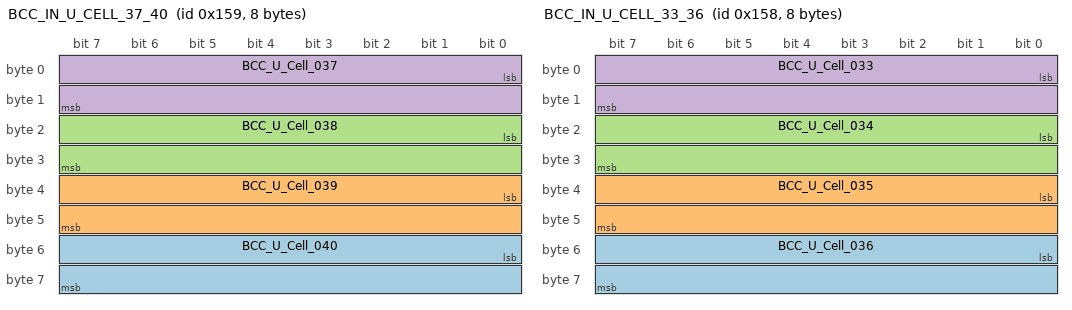
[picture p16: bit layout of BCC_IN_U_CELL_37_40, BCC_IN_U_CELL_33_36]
BO_ 345 BCC_IN_U_CELL_37_40: 8 HED
 SG_ BCC_U_Cell_040 : 48|16@1+ (1,0) [0|6000] "mV"  CALTOOL
 SG_ BCC_U_Cell_039 : 32|16@1+ (1,0) [0|6000] "mV"  CALTOOL
 SG_ BCC_U_Cell_038 : 16|16@1+ (1,0) [0|6000] "mV"  CALTOOL
 SG_ BCC_U_Cell_037 : 0|16@1+ (1,0) [0|6000] "mV"  CALTOOL

BO_ 344 BCC_IN_U_CELL_33_36: 8 HED
 SG_ BCC_U_Cell_036 : 48|16@1+ (1,0) [0|6000] "mV"  CALTOOL
 SG_ BCC_U_Cell_035 : 32|16@1+ (1,0) [0|6000] "mV"  CALTOOL
 SG_ BCC_U_Cell_034 : 16|16@1+ (1,0) [0|6000] "mV"  CALTOOL
 SG_ BCC_U_Cell_033 : 0|16@1+ (1,0) [0|6000] "mV"  CALTOOL

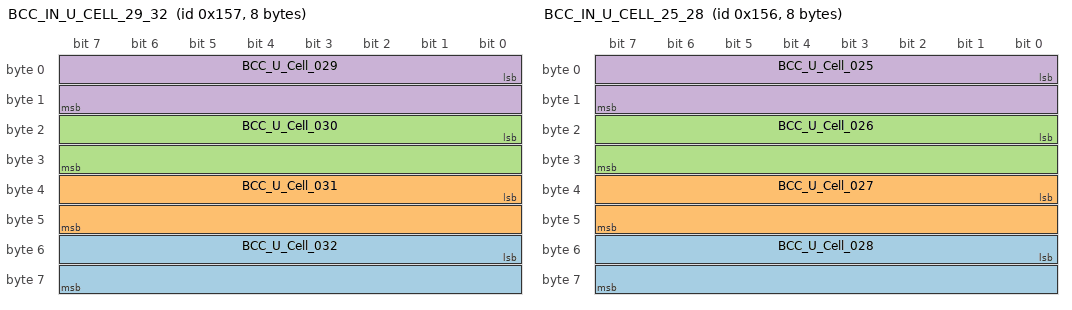
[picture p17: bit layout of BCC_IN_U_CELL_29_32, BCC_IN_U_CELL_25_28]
BO_ 343 BCC_IN_U_CELL_29_32: 8 HED
 SG_ BCC_U_Cell_032 : 48|16@1+ (1,0) [0|6000] "mV"  CALTOOL
 SG_ BCC_U_Cell_031 : 32|16@1+ (1,0) [0|6000] "mV"  CALTOOL
 SG_ BCC_U_Cell_030 : 16|16@1+ (1,0) [0|6000] "mV"  CALTOOL
 SG_ BCC_U_Cell_029 : 0|16@1+ (1,0) [0|6000] "mV"  CALTOOL

BO_ 342 BCC_IN_U_CELL_25_28: 8 HED
 SG_ BCC_U_Cell_028 : 48|16@1+ (1,0) [0|6000] "mV"  CALTOOL
 SG_ BCC_U_Cell_027 : 32|16@1+ (1,0) [0|6000] "mV"  CALTOOL
 SG_ BCC_U_Cell_026 : 16|16@1+ (1,0) [0|6000] "mV"  CALTOOL
 SG_ BCC_U_Cell_025 : 0|16@1+ (1,0) [0|6000] "mV"  CALTOOL

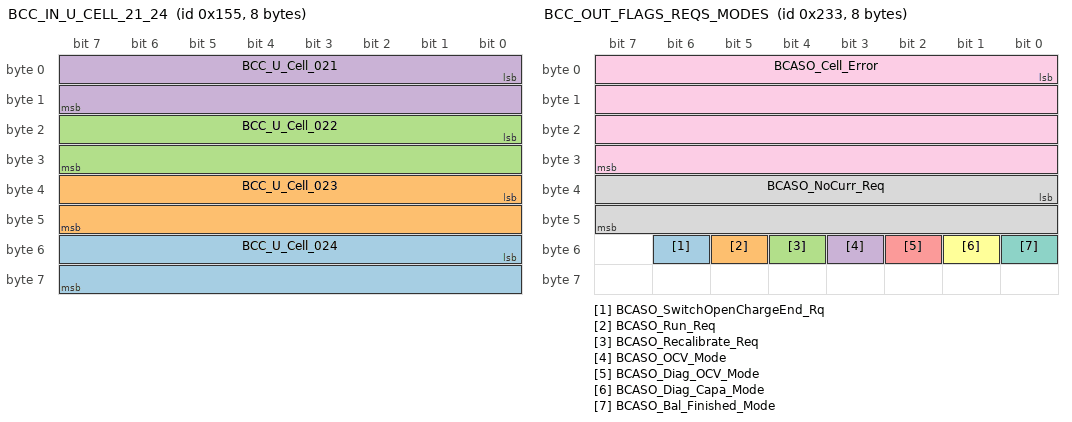
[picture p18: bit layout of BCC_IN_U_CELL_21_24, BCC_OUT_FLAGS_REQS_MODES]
BO_ 341 BCC_IN_U_CELL_21_24: 8 HED
 SG_ BCC_U_Cell_024 : 48|16@1+ (1,0) [0|6000] "mV"  CALTOOL
 SG_ BCC_U_Cell_023 : 32|16@1+ (1,0) [0|6000] "mV"  CALTOOL
 SG_ BCC_U_Cell_022 : 16|16@1+ (1,0) [0|6000] "mV"  CALTOOL
 SG_ BCC_U_Cell_021 : 0|16@1+ (1,0) [0|6000] "mV"  CALTOOL

BO_ 340 BCC_IN_U_CELL_17_20: 8 HED
 SG_ BCC_U_Cell_020 : 48|16@1+ (1,0) [0|6000] "mV"  CALTOOL
 SG_ BCC_U_Cell_019 : 32|16@1+ (1,0) [0|6000] "mV"  CALTOOL
 SG_ BCC_U_Cell_018 : 16|16@1+ (1,0) [0|6000] "mV"  CALTOOL
 SG_ BCC_U_Cell_017 : 0|16@1+ (1,0) [0|6000] "mV"  CALTOOL

BO_ 339 BCC_IN_U_CELL_13_16: 8 HED
 SG_ BCC_U_Cell_016 : 48|16@1+ (1,0) [0|6000] "mV"  CALTOOL
 SG_ BCC_U_Cell_015 : 32|16@1+ (1,0) [0|6000] "mV"  CALTOOL
 SG_ BCC_U_Cell_014 : 16|16@1+ (1,0) [0|6000] "mV"  CALTOOL
 SG_ BCC_U_Cell_013 : 0|16@1+ (1,0) [0|6000] "mV"  CALTOOL

BO_ 338 BCC_IN_U_CELL_09_12: 8 HED
 SG_ BCC_U_Cell_012 : 48|16@1+ (1,0) [0|6000] "mV"  CALTOOL
 SG_ BCC_U_Cell_011 : 32|16@1+ (1,0) [0|6000] "mV"  CALTOOL
 SG_ BCC_U_Cell_010 : 16|16@1+ (1,0) [0|6000] "mV"  CALTOOL
 SG_ BCC_U_Cell_009 : 0|16@1+ (1,0) [0|6000] "mV"  CALTOOL

BO_ 337 BCC_IN_U_CELL_05_08: 8 HED
 SG_ BCC_U_Cell_008 : 48|16@1+ (1,0) [0|6000] "mV"  CALTOOL
 SG_ BCC_U_Cell_007 : 32|16@1+ (1,0) [0|6000] "mV"  CALTOOL
 SG_ BCC_U_Cell_006 : 16|16@1+ (1,0) [0|6000] "mV"  CALTOOL
 SG_ BCC_U_Cell_005 : 0|16@1+ (1,0) [0|6000] "mV"  CALTOOL

BO_ 336 BCC_IN_U_CELL_01_04: 8 HED
 SG_ BCC_U_Cell_004 : 48|16@1+ (1,0) [0|6000] "mV"  CALTOOL
 SG_ BCC_U_Cell_003 : 32|16@1+ (1,0) [0|6000] "mV"  CALTOOL
 SG_ BCC_U_Cell_002 : 16|16@1+ (1,0) [0|6000] "mV"  CALTOOL
 SG_ BCC_U_Cell_001 : 0|16@1+ (1,0) [0|6000] "mV"  CALTOOL

BO_ 298 BCC_IN_DIAG_OCV_21: 8 HED
 SG_ BCC_Diag_OCV_Arr21_1mV_21 : 0|32@1- (0.0009765625,0) [-2097152|2097151.999] "V"  CALTOOL

BO_ 297 BCC_IN_DIAG_OCV_19_20: 8 HED
 SG_ BCC_Diag_OCV_Arr21_1mV_20 : 32|32@1- (0.0009765625,0) [-2097152|2097151.999] "V"  CALTOOL
 SG_ BCC_Diag_OCV_Arr21_1mV_19 : 0|32@1- (0.0009765625,0) [-2097152|2097151.999] "V"  CALTOOL

BO_ 296 BCC_IN_DIAG_OCV_17_18: 8 HED
 SG_ BCC_Diag_OCV_Arr21_1mV_18 : 32|32@1- (0.0009765625,0) [-2097152|2097151.999] "V"  CALTOOL
 SG_ BCC_Diag_OCV_Arr21_1mV_17 : 0|32@1- (0.0009765625,0) [-2097152|2097151.999] "V"  CALTOOL

BO_ 295 BCC_IN_DIAG_OCV_15_16: 8 HED
 SG_ BCC_Diag_OCV_Arr21_1mV_16 : 32|32@1- (0.0009765625,0) [-2097152|2097151.999] "V"  CALTOOL
 SG_ BCC_Diag_OCV_Arr21_1mV_15 : 0|32@1- (0.0009765625,0) [-2097152|2097151.999] "V"  CALTOOL

BO_ 294 BCC_IN_DIAG_OCV_13_14: 8 HED
 SG_ BCC_Diag_OCV_Arr21_1mV_14 : 32|32@1- (0.0009765625,0) [-2097152|2097151.999] "V"  CALTOOL
 SG_ BCC_Diag_OCV_Arr21_1mV_13 : 0|32@1- (0.0009765625,0) [-2097152|2097151.999] "V"  CALTOOL

BO_ 293 BCC_IN_DIAG_OCV_11_12: 8 HED
 SG_ BCC_Diag_OCV_Arr21_1mV_12 : 32|32@1- (0.0009765625,0) [-2097152|2097151.999] "V"  CALTOOL
 SG_ BCC_Diag_OCV_Arr21_1mV_11 : 0|32@1- (0.0009765625,0) [-2097152|2097151.999] "V"  CALTOOL

BO_ 292 BCC_IN_DIAG_OCV_09_10: 8 HED
 SG_ BCC_Diag_OCV_Arr21_1mV_10 : 32|32@1- (0.0009765625,0) [-2097152|2097151.999] "V"  CALTOOL
 SG_ BCC_Diag_OCV_Arr21_1mV_09 : 0|32@1- (0.0009765625,0) [-2097152|2097151.999] "V"  CALTOOL

BO_ 291 BCC_IN_DIAG_OCV_07_08: 8 HED
 SG_ BCC_Diag_OCV_Arr21_1mV_08 : 32|32@1- (0.0009765625,0) [-2097152|2097151.999] "V"  CALTOOL
 SG_ BCC_Diag_OCV_Arr21_1mV_07 : 0|32@1- (0.0009765625,0) [-2097152|2097151.999] "V"  CALTOOL

BO_ 290 BCC_IN_DIAG_OCV_05_06: 8 HED
 SG_ BCC_Diag_OCV_Arr21_1mV_06 : 32|32@1- (0.0009765625,0) [-2097152|2097151.999] "V"  CALTOOL
 SG_ BCC_Diag_OCV_Arr21_1mV_05 : 0|32@1- (0.0009765625,0) [-2097152|2097151.999] "V"  CALTOOL

BO_ 289 BCC_IN_DIAG_OCV_03_04: 8 HED
 SG_ BCC_Diag_OCV_Arr21_1mV_04 : 32|32@1- (0.0009765625,0) [-2097152|2097151.999] "V"  CALTOOL
 SG_ BCC_Diag_OCV_Arr21_1mV_03 : 0|32@1- (0.0009765625,0) [-2097152|2097151.999] "V"  CALTOOL

BO_ 288 BCC_IN_DIAG_OCV_01_02: 8 HED
 SG_ BCC_Diag_OCV_Arr21_1mV_02 : 32|32@1- (0.0009765625,0) [-2097152|2097151.999] "V"  CALTOOL
 SG_ BCC_Diag_OCV_Arr21_1mV_01 : 0|32@1- (0.0009765625,0) [-2097152|2097151.999] "V"  CALTOOL

BO_ 331 BCC_IN_U_CELL_SNA_065_128: 8 HED
 SG_ BCC_U_Cell_SNA_Mode_100 : 35|1@1+ (1,0) [0|0] ""  CALTOOL
 SG_ BCC_U_Cell_SNA_Mode_099 : 34|1@1+ (1,0) [0|0] ""  CALTOOL
 SG_ BCC_U_Cell_SNA_Mode_098 : 33|1@1+ (1,0) [0|0] ""  CALTOOL
 SG_ BCC_U_Cell_SNA_Mode_097 : 32|1@1+ (1,0) [0|0] ""  CALTOOL
 SG_ BCC_U_Cell_SNA_Mode_096 : 31|1@1+ (1,0) [0|0] ""  CALTOOL
 SG_ BCC_U_Cell_SNA_Mode_095 : 30|1@1+ (1,0) [0|0] ""  CALTOOL
 SG_ BCC_U_Cell_SNA_Mode_094 : 29|1@1+ (1,0) [0|0] ""  CALTOOL
 SG_ BCC_U_Cell_SNA_Mode_093 : 28|1@1+ (1,0) [0|0] ""  CALTOOL
 SG_ BCC_U_Cell_SNA_Mode_092 : 27|1@1+ (1,0) [0|0] ""  CALTOOL
 SG_ BCC_U_Cell_SNA_Mode_091 : 26|1@1+ (1,0) [0|0] ""  CALTOOL
 SG_ BCC_U_Cell_SNA_Mode_090 : 25|1@1+ (1,0) [0|0] ""  CALTOOL
 SG_ BCC_U_Cell_SNA_Mode_089 : 24|1@1+ (1,0) [0|0] ""  CALTOOL
 SG_ BCC_U_Cell_SNA_Mode_088 : 23|1@1+ (1,0) [0|0] ""  CALTOOL
 SG_ BCC_U_Cell_SNA_Mode_087 : 22|1@1+ (1,0) [0|0] ""  CALTOOL
 SG_ BCC_U_Cell_SNA_Mode_086 : 21|1@1+ (1,0) [0|0] ""  CALTOOL
 SG_ BCC_U_Cell_SNA_Mode_085 : 20|1@1+ (1,0) [0|0] ""  CALTOOL
 SG_ BCC_U_Cell_SNA_Mode_084 : 19|1@1+ (1,0) [0|0] ""  CALTOOL
 SG_ BCC_U_Cell_SNA_Mode_083 : 18|1@1+ (1,0) [0|0] ""  CALTOOL
 SG_ BCC_U_Cell_SNA_Mode_082 : 17|1@1+ (1,0) [0|0] ""  CALTOOL
 SG_ BCC_U_Cell_SNA_Mode_081 : 16|1@1+ (1,0) [0|0] ""  CALTOOL
 SG_ BCC_U_Cell_SNA_Mode_080 : 15|1@1+ (1,0) [0|0] ""  CALTOOL
 SG_ BCC_U_Cell_SNA_Mode_079 : 14|1@1+ (1,0) [0|0] ""  CALTOOL
 SG_ BCC_U_Cell_SNA_Mode_078 : 13|1@1+ (1,0) [0|0] ""  CALTOOL
 SG_ BCC_U_Cell_SNA_Mode_077 : 12|1@1+ (1,0) [0|0] ""  CALTOOL
 SG_ BCC_U_Cell_SNA_Mode_076 : 11|1@1+ (1,0) [0|0] ""  CALTOOL
 SG_ BCC_U_Cell_SNA_Mode_075 : 10|1@1+ (1,0) [0|0] ""  CALTOOL
 SG_ BCC_U_Cell_SNA_Mode_074 : 9|1@1+ (1,0) [0|0] ""  CALTOOL
 SG_ BCC_U_Cell_SNA_Mode_073 : 8|1@1+ (1,0) [0|0] ""  CALTOOL
 SG_ BCC_U_Cell_SNA_Mode_072 : 7|1@1+ (1,0) [0|0] ""  CALTOOL
 SG_ BCC_U_Cell_SNA_Mode_071 : 6|1@1+ (1,0) [0|0] ""  CALTOOL
 SG_ BCC_U_Cell_SNA_Mode_070 : 5|1@1+ (1,0) [0|0] ""  CALTOOL
 SG_ BCC_U_Cell_SNA_Mode_069 : 4|1@1+ (1,0) [0|0] ""  CALTOOL
 SG_ BCC_U_Cell_SNA_Mode_068 : 3|1@1+ (1,0) [0|0] ""  CALTOOL
 SG_ BCC_U_Cell_SNA_Mode_067 : 2|1@1+ (1,0) [0|0] ""  CALTOOL
 SG_ BCC_U_Cell_SNA_Mode_066 : 1|1@1+ (1,0) [0|0] ""  CALTOOL
 SG_ BCC_U_Cell_SNA_Mode_065 : 0|1@1+ (1,0) [0|0] ""  CALTOOL

BO_ 304 BCC_IN_T_BATT: 8 HED
 SG_ BCC_T_Batt_SNA_Mode_30 : 61|1@1+ (1,0) [0|0] ""  CALTOOL
 SG_ BCC_T_Batt_SNA_Mode_29 : 60|1@1+ (1,0) [0|0] ""  CALTOOL
 SG_ BCC_T_Batt_SNA_Mode_28 : 59|1@1+ (1,0) [0|0] ""  CALTOOL
 SG_ BCC_T_Batt_SNA_Mode_27 : 58|1@1+ (1,0) [0|0] ""  CALTOOL
 SG_ BCC_T_Batt_SNA_Mode_26 : 57|1@1+ (1,0) [0|0] ""  CALTOOL
 SG_ BCC_T_Batt_SNA_Mode_25 : 56|1@1+ (1,0) [0|0] ""  CALTOOL
 SG_ BCC_T_Batt_SNA_Mode_24 : 55|1@1+ (1,0) [0|0] ""  CALTOOL
 SG_ BCC_T_Batt_SNA_Mode_23 : 54|1@1+ (1,0) [0|0] ""  CALTOOL
 SG_ BCC_T_Batt_SNA_Mode_22 : 53|1@1+ (1,0) [0|0] ""  CALTOOL
 SG_ BCC_T_Batt_SNA_Mode_21 : 52|1@1+ (1,0) [0|0] ""  CALTOOL
 SG_ BCC_T_Batt_SNA_Mode_20 : 51|1@1+ (1,0) [0|0] ""  CALTOOL
 SG_ BCC_T_Batt_SNA_Mode_19 : 50|1@1+ (1,0) [0|0] ""  CALTOOL
 SG_ BCC_T_Batt_SNA_Mode_18 : 49|1@1+ (1,0) [0|0] ""  CALTOOL
 SG_ BCC_T_Batt_SNA_Mode_17 : 48|1@1+ (1,0) [0|0] ""  CALTOOL
 SG_ BCC_T_Batt_SNA_Mode_16 : 47|1@1+ (1,0) [0|0] ""  CALTOOL
 SG_ BCC_T_Batt_SNA_Mode_15 : 46|1@1+ (1,0) [0|0] ""  CALTOOL
 SG_ BCC_T_Batt_SNA_Mode_14 : 45|1@1+ (1,0) [0|0] ""  CALTOOL
 SG_ BCC_T_Batt_SNA_Mode_13 : 44|1@1+ (1,0) [0|0] ""  CALTOOL
 SG_ BCC_T_Batt_SNA_Mode_12 : 43|1@1+ (1,0) [0|0] ""  CALTOOL
 SG_ BCC_T_Batt_SNA_Mode_11 : 42|1@1+ (1,0) [0|0] ""  CALTOOL
 SG_ BCC_T_Batt_SNA_Mode_10 : 41|1@1+ (1,0) [0|0] ""  CALTOOL
 SG_ BCC_T_Batt_SNA_Mode_09 : 40|1@1+ (1,0) [0|0] ""  CALTOOL
 SG_ BCC_T_Batt_SNA_Mode_08 : 39|1@1+ (1,0) [0|0] ""  CALTOOL
 SG_ BCC_T_Batt_SNA_Mode_07 : 38|1@1+ (1,0) [0|0] ""  CALTOOL
 SG_ BCC_T_Batt_SNA_Mode_06 : 37|1@1+ (1,0) [0|0] ""  CALTOOL
 SG_ BCC_T_Batt_SNA_Mode_05 : 36|1@1+ (1,0) [0|0] ""  CALTOOL
 SG_ BCC_T_Batt_SNA_Mode_04 : 35|1@1+ (1,0) [0|0] ""  CALTOOL
 SG_ BCC_T_Batt_SNA_Mode_03 : 34|1@1+ (1,0) [0|0] ""  CALTOOL
 SG_ BCC_T_Batt_SNA_Mode_02 : 33|1@1+ (1,0) [0|0] ""  CALTOOL
 SG_ BCC_T_Batt_SNA_Mode_01 : 32|1@1+ (1,0) [0|0] ""  CALTOOL
 SG_ BCC_T_Batt : 0|32@1- (0.0009765625,0) [-2097152|2097151.99902344] "°C"  CALTOOL

BO_ 560 BCC_OUT_ACTUAL_U_I: 8 HED
 SG_ BCASO_U_Batt_Sum_of_U_Cell : 32|32@1- (0.0009765625,0) [-2097152|2097151.999] "V"  CALTOOL
 SG_ BCASO_I_Batt_Filtered : 0|32@1- (0.0009765625,0) [-2097152|2097151.999] "A"  CALTOOL

BO_ 571 BCC_OUT_TIME: 8 HED
 SG_ BCASO_Time_Sw_Open : 0|32@1- (1,0) [-2147483648|2147483647] "s"  CALTOOL

BO_ 563 BCC_OUT_FLAGS_REQS_MODES: 8 HED
 SG_ BCASO_SwitchOpenChargeEnd_Rq : 54|1@1+ (1,0) [0|0] ""  CALTOOL
 SG_ BCASO_Run_Req : 53|1@1+ (1,0) [0|0] ""  CALTOOL
 SG_ BCASO_Recalibrate_Req : 52|1@1+ (1,0) [0|0] ""  CALTOOL
 SG_ BCASO_OCV_Mode : 51|1@1+ (1,0) [0|0] ""  CALTOOL
 SG_ BCASO_Diag_OCV_Mode : 50|1@1+ (1,0) [0|0] ""  CALTOOL
 SG_ BCASO_Diag_Capa_Mode : 49|1@1+ (1,0) [0|0] ""  CALTOOL
 SG_ BCASO_Bal_Finished_Mode : 48|1@1+ (1,0) [0|0] ""  CALTOOL
 SG_ BCASO_NoCurr_Req : 32|16@1- (1,0) [-32768|32767] ""  CALTOOL
 SG_ BCASO_Cell_Error : 0|32@1+ (1,0) [0|4294967295] ""  CALTOOL

BO_ 572 BCC_OUT_U_CELL_MAX_MIN: 8 HED
 SG_ BCASO_U_Cell_Min : 32|32@1- (0.0009765625,0) [-2097152|2097151.999] "V"  CALTOOL
 SG_ BCASO_U_Cell_Max : 0|32@1- (0.0009765625,0) [-2097152|2097151.999] "V"  CALTOOL

BO_ 570 BCC_OUT_TEMP: 8 HED
 SG_ BCASO_T_Batt_Min : 32|32@1- (0.0009765625,0) [-2097152|2097151.999] "°C"  CALTOOL
 SG_ BCASO_T_Batt_Max : 0|32@1- (0.0009765625,0) [-2097152|2097151.999] "°C"  CALTOOL

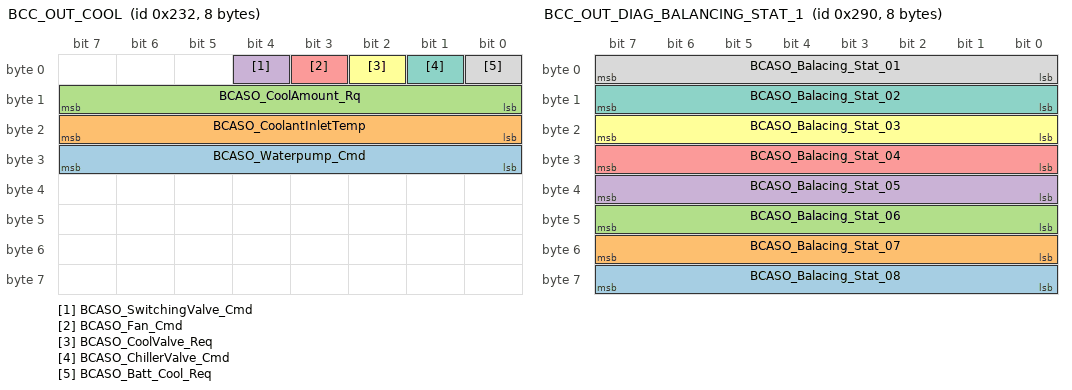
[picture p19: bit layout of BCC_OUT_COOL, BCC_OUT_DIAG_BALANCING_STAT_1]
BO_ 562 BCC_OUT_COOL: 8 HED
 SG_ BCASO_Waterpump_Cmd : 24|8@1+ (1,0) [0|100] "%"  CALTOOL
 SG_ BCASO_CoolantInletTemp : 16|8@1+ (0.5,-40) [-40|80] "°C"  CALTOOL
 SG_ BCASO_CoolAmount_Rq : 8|8@1+ (20,0) [0|5080] ""  CALTOOL
 SG_ BCASO_SwitchingValve_Cmd : 4|1@1+ (1,0) [0|0] ""  CALTOOL
 SG_ BCASO_Fan_Cmd : 3|1@1+ (1,0) [0|0] ""  CALTOOL
 SG_ BCASO_CoolValve_Req : 2|1@1+ (1,0) [0|0] ""  CALTOOL
 SG_ BCASO_ChillerValve_Cmd : 1|1@1+ (1,0) [0|0] ""  CALTOOL
 SG_ BCASO_Batt_Cool_Req : 0|1@1+ (1,0) [0|0] ""  CALTOOL

BO_ 561 BCC_OUT_CAPA: 8 HED
 SG_ BCASO_CapaHV_As_ref_1 : 16|16@1+ (1,0) [0|65535] "As"  CALTOOL
 SG_ BCASO_CapaHV_As_act_1 : 0|16@1+ (1,0) [0|65535] "As"  CALTOOL

BO_ 569 BCC_OUT_SOC_MAX_MIN: 8 HED
 SG_ BCASO_SOC_Min : 32|32@1- (0.0625,0) [-134217728|134217727.9375] "%"  CALTOOL
 SG_ BCASO_SOC_Max : 0|32@1- (0.0625,0) [-134217728|134217727.9375] "%"  CALTOOL

BO_ 568 BCC_OUT_SOC: 8 HED
 SG_ BCASO_SOC_Disp : 32|8@1+ (0.5,0) [0|100] "%"  CALTOOL
 SG_ BCASO_SOC : 0|32@1+ (0.0625,0) [0|268435455.9375] "%"  CALTOOL

BO_ 330 BCC_IN_U_CELL_SNA_001_064: 8 HED
 SG_ BCC_U_Cell_SNA_Mode_064 : 63|1@1+ (1,0) [0|0] ""  CALTOOL
 SG_ BCC_U_Cell_SNA_Mode_063 : 62|1@1+ (1,0) [0|0] ""  CALTOOL
 SG_ BCC_U_Cell_SNA_Mode_062 : 61|1@1+ (1,0) [0|0] ""  CALTOOL
 SG_ BCC_U_Cell_SNA_Mode_061 : 60|1@1+ (1,0) [0|0] ""  CALTOOL
 SG_ BCC_U_Cell_SNA_Mode_060 : 59|1@1+ (1,0) [0|0] ""  CALTOOL
 SG_ BCC_U_Cell_SNA_Mode_059 : 58|1@1+ (1,0) [0|0] ""  CALTOOL
 SG_ BCC_U_Cell_SNA_Mode_058 : 57|1@1+ (1,0) [0|0] ""  CALTOOL
 SG_ BCC_U_Cell_SNA_Mode_057 : 56|1@1+ (1,0) [0|0] ""  CALTOOL
 SG_ BCC_U_Cell_SNA_Mode_056 : 55|1@1+ (1,0) [0|0] ""  CALTOOL
 SG_ BCC_U_Cell_SNA_Mode_055 : 54|1@1+ (1,0) [0|0] ""  CALTOOL
 SG_ BCC_U_Cell_SNA_Mode_054 : 53|1@1+ (1,0) [0|0] ""  CALTOOL
 SG_ BCC_U_Cell_SNA_Mode_053 : 52|1@1+ (1,0) [0|0] ""  CALTOOL
 SG_ BCC_U_Cell_SNA_Mode_052 : 51|1@1+ (1,0) [0|0] ""  CALTOOL
 SG_ BCC_U_Cell_SNA_Mode_051 : 50|1@1+ (1,0) [0|0] ""  CALTOOL
 SG_ BCC_U_Cell_SNA_Mode_050 : 49|1@1+ (1,0) [0|0] ""  CALTOOL
 SG_ BCC_U_Cell_SNA_Mode_049 : 48|1@1+ (1,0) [0|0] ""  CALTOOL
 SG_ BCC_U_Cell_SNA_Mode_048 : 47|1@1+ (1,0) [0|0] ""  CALTOOL
 SG_ BCC_U_Cell_SNA_Mode_047 : 46|1@1+ (1,0) [0|0] ""  CALTOOL
 SG_ BCC_U_Cell_SNA_Mode_046 : 45|1@1+ (1,0) [0|0] ""  CALTOOL
 SG_ BCC_U_Cell_SNA_Mode_045 : 44|1@1+ (1,0) [0|0] ""  CALTOOL
 SG_ BCC_U_Cell_SNA_Mode_044 : 43|1@1+ (1,0) [0|0] ""  CALTOOL
 SG_ BCC_U_Cell_SNA_Mode_043 : 42|1@1+ (1,0) [0|0] ""  CALTOOL
 SG_ BCC_U_Cell_SNA_Mode_042 : 41|1@1+ (1,0) [0|0] ""  CALTOOL
 SG_ BCC_U_Cell_SNA_Mode_041 : 40|1@1+ (1,0) [0|0] ""  CALTOOL
 SG_ BCC_U_Cell_SNA_Mode_040 : 39|1@1+ (1,0) [0|0] ""  CALTOOL
 SG_ BCC_U_Cell_SNA_Mode_039 : 38|1@1+ (1,0) [0|0] ""  CALTOOL
 SG_ BCC_U_Cell_SNA_Mode_038 : 37|1@1+ (1,0) [0|0] ""  CALTOOL
 SG_ BCC_U_Cell_SNA_Mode_037 : 36|1@1+ (1,0) [0|0] ""  CALTOOL
 SG_ BCC_U_Cell_SNA_Mode_036 : 35|1@1+ (1,0) [0|0] ""  CALTOOL
 SG_ BCC_U_Cell_SNA_Mode_035 : 34|1@1+ (1,0) [0|0] ""  CALTOOL
 SG_ BCC_U_Cell_SNA_Mode_034 : 33|1@1+ (1,0) [0|0] ""  CALTOOL
 SG_ BCC_U_Cell_SNA_Mode_033 : 32|1@1+ (1,0) [0|0] ""  CALTOOL
 SG_ BCC_U_Cell_SNA_Mode_032 : 31|1@1+ (1,0) [0|0] ""  CALTOOL
 SG_ BCC_U_Cell_SNA_Mode_031 : 30|1@1+ (1,0) [0|0] ""  CALTOOL
 SG_ BCC_U_Cell_SNA_Mode_030 : 29|1@1+ (1,0) [0|0] ""  CALTOOL
 SG_ BCC_U_Cell_SNA_Mode_029 : 28|1@1+ (1,0) [0|0] ""  CALTOOL
 SG_ BCC_U_Cell_SNA_Mode_028 : 27|1@1+ (1,0) [0|0] ""  CALTOOL
 SG_ BCC_U_Cell_SNA_Mode_027 : 26|1@1+ (1,0) [0|0] ""  CALTOOL
 SG_ BCC_U_Cell_SNA_Mode_026 : 25|1@1+ (1,0) [0|0] ""  CALTOOL
 SG_ BCC_U_Cell_SNA_Mode_025 : 24|1@1+ (1,0) [0|0] ""  CALTOOL
 SG_ BCC_U_Cell_SNA_Mode_024 : 23|1@1+ (1,0) [0|0] ""  CALTOOL
 SG_ BCC_U_Cell_SNA_Mode_023 : 22|1@1+ (1,0) [0|0] ""  CALTOOL
 SG_ BCC_U_Cell_SNA_Mode_022 : 21|1@1+ (1,0) [0|0] ""  CALTOOL
 SG_ BCC_U_Cell_SNA_Mode_021 : 20|1@1+ (1,0) [0|0] ""  CALTOOL
 SG_ BCC_U_Cell_SNA_Mode_020 : 19|1@1+ (1,0) [0|0] ""  CALTOOL
 SG_ BCC_U_Cell_SNA_Mode_019 : 18|1@1+ (1,0) [0|0] ""  CALTOOL
 SG_ BCC_U_Cell_SNA_Mode_018 : 17|1@1+ (1,0) [0|0] ""  CALTOOL
 SG_ BCC_U_Cell_SNA_Mode_017 : 16|1@1+ (1,0) [0|0] ""  CALTOOL
 SG_ BCC_U_Cell_SNA_Mode_016 : 15|1@1+ (1,0) [0|0] ""  CALTOOL
 SG_ BCC_U_Cell_SNA_Mode_015 : 14|1@1+ (1,0) [0|0] ""  CALTOOL
 SG_ BCC_U_Cell_SNA_Mode_014 : 13|1@1+ (1,0) [0|0] ""  CALTOOL
 SG_ BCC_U_Cell_SNA_Mode_013 : 12|1@1+ (1,0) [0|0] ""  CALTOOL
 SG_ BCC_U_Cell_SNA_Mode_012 : 11|1@1+ (1,0) [0|0] ""  CALTOOL
 SG_ BCC_U_Cell_SNA_Mode_011 : 10|1@1+ (1,0) [0|0] ""  CALTOOL
 SG_ BCC_U_Cell_SNA_Mode_010 : 9|1@1+ (1,0) [0|0] ""  CALTOOL
 SG_ BCC_U_Cell_SNA_Mode_009 : 8|1@1+ (1,0) [0|0] ""  CALTOOL
 SG_ BCC_U_Cell_SNA_Mode_008 : 7|1@1+ (1,0) [0|0] ""  CALTOOL
 SG_ BCC_U_Cell_SNA_Mode_007 : 6|1@1+ (1,0) [0|0] ""  CALTOOL
 SG_ BCC_U_Cell_SNA_Mode_006 : 5|1@1+ (1,0) [0|0] ""  CALTOOL
 SG_ BCC_U_Cell_SNA_Mode_005 : 4|1@1+ (1,0) [0|0] ""  CALTOOL
 SG_ BCC_U_Cell_SNA_Mode_004 : 3|1@1+ (1,0) [0|0] ""  CALTOOL
 SG_ BCC_U_Cell_SNA_Mode_003 : 2|1@1+ (1,0) [0|0] ""  CALTOOL
 SG_ BCC_U_Cell_SNA_Mode_002 : 1|1@1+ (1,0) [0|0] ""  CALTOOL
 SG_ BCC_U_Cell_SNA_Mode_001 : 0|1@1+ (1,0) [0|0] ""  CALTOOL

BO_ 564 BCC_OUT_LIMITS_I: 8 HED
 SG_ BCASO_I_Max_DisChrg : 32|32@1- (0.0009765625,0) [-2097152|2097151.999] "A"  CALTOOL
 SG_ BCASO_I_Max_Chrg : 0|32@1- (0.0009765625,0) [-2097152|2097151.999] "A"  CALTOOL

BO_ 565 BCC_OUT_LIMITS_U: 8 HED
 SG_ BCASO_U_Min : 32|32@1- (0.0009765625,0) [-2097152|2097151.999] "V"  CALTOOL
 SG_ BCASO_U_Max : 0|32@1- (0.0009765625,0) [-2097152|2097151.999] "V"  CALTOOL

BO_ 586 BCC_OUT_OCV_21: 8 HED
 SG_ BCASO_OCV_Arr21_1mV_21 : 0|32@1- (0.0009765625,0) [-2097152|2097151.999] "V"  CALTOOL

BO_ 585 BCC_OUT_OCV_19_20: 8 HED
 SG_ BCASO_OCV_Arr21_1mV_20 : 32|32@1- (0.0009765625,0) [-2097152|2097151.999] "V"  CALTOOL
 SG_ BCASO_OCV_Arr21_1mV_19 : 0|32@1- (0.0009765625,0) [-2097152|2097151.999] "V"  CALTOOL

BO_ 584 BCC_OUT_OCV_17_18: 8 HED
 SG_ BCASO_OCV_Arr21_1mV_18 : 32|32@1- (0.0009765625,0) [-2097152|2097151.999] "V"  CALTOOL
 SG_ BCASO_OCV_Arr21_1mV_17 : 0|32@1- (0.0009765625,0) [-2097152|2097151.999] "V"  CALTOOL

BO_ 583 BCC_OUT_OCV_15_16: 8 HED
 SG_ BCASO_OCV_Arr21_1mV_16 : 32|32@1- (0.0009765625,0) [-2097152|2097151.999] "V"  CALTOOL
 SG_ BCASO_OCV_Arr21_1mV_15 : 0|32@1- (0.0009765625,0) [-2097152|2097151.999] "V"  CALTOOL

BO_ 582 BCC_OUT_OCV_13_14: 8 HED
 SG_ BCASO_OCV_Arr21_1mV_14 : 32|32@1- (0.0009765625,0) [-2097152|2097151.999] "V"  CALTOOL
 SG_ BCASO_OCV_Arr21_1mV_13 : 0|32@1- (0.0009765625,0) [-2097152|2097151.999] "V"  CALTOOL

BO_ 581 BCC_OUT_OCV_11_12: 8 HED
 SG_ BCASO_OCV_Arr21_1mV_12 : 32|32@1- (0.0009765625,0) [-2097152|2097151.999] "V"  CALTOOL
 SG_ BCASO_OCV_Arr21_1mV_11 : 0|32@1- (0.0009765625,0) [-2097152|2097151.999] "V"  CALTOOL

BO_ 580 BCC_OUT_OCV_09_10: 8 HED
 SG_ BCASO_OCV_Arr21_1mV_10 : 32|32@1- (0.0009765625,0) [-2097152|2097151.999] "V"  CALTOOL
 SG_ BCASO_OCV_Arr21_1mV_09 : 0|32@1- (0.0009765625,0) [-2097152|2097151.999] "V"  CALTOOL

BO_ 579 BCC_OUT_OCV_07_08: 8 HED
 SG_ BCASO_OCV_Arr21_1mV_08 : 32|32@1- (0.0009765625,0) [-2097152|2097151.999] "V"  CALTOOL
 SG_ BCASO_OCV_Arr21_1mV_07 : 0|32@1- (0.0009765625,0) [-2097152|2097151.999] "V"  CALTOOL

BO_ 578 BCC_OUT_OCV_05_06: 8 HED
 SG_ BCASO_OCV_Arr21_1mV_06 : 32|32@1- (0.0009765625,0) [-2097152|2097151.999] "V"  CALTOOL
 SG_ BCASO_OCV_Arr21_1mV_05 : 0|32@1- (0.0009765625,0) [-2097152|2097151.999] "V"  CALTOOL

BO_ 577 BCC_OUT_OCV_03_04: 8 HED
 SG_ BCASO_OCV_Arr21_1mV_04 : 32|32@1- (0.0009765625,0) [-2097152|2097151.999] "V"  CALTOOL
 SG_ BCASO_OCV_Arr21_1mV_03 : 0|32@1- (0.0009765625,0) [-2097152|2097151.999] "V"  CALTOOL

BO_ 576 BCC_OUT_OCV_01_02: 8 HED
 SG_ BCASO_OCV_Arr21_1mV_02 : 32|32@1- (0.0009765625,0) [-2097152|2097151.999] "V"  CALTOOL
 SG_ BCASO_OCV_Arr21_1mV_01 : 0|32@1- (0.0009765625,0) [-2097152|2097151.999] "V"  CALTOOL

BO_ 566 BCC_OUT_PP_LONG: 8 HED
 SG_ BCASO_U_Dchrg_long : 48|16@1+ (0.1,0) [0|819] "V"  CALTOOL
 SG_ BCASO_I_Dchrg_long : 32|16@1+ (0.1,-819.2) [-819.2|819] "A"  CALTOOL
 SG_ BCASO_U_Chrg_long : 16|16@1+ (0.1,0) [0|819] "V"  CALTOOL
 SG_ BCASO_I_Chrg_long : 0|16@1+ (0.1,-819.2) [-819.2|819] "A"  CALTOOL

BO_ 567 BCC_OUT_PP_SHORT: 8 HED
 SG_ BCASO_U_Dchrg_short : 48|16@1+ (0.1,0) [0|819] "V"  CALTOOL
 SG_ BCASO_I_Dchrg_short : 32|16@1+ (0.1,-819.2) [-819.2|819] "A"  CALTOOL
 SG_ BCASO_U_Chrg_short : 16|16@1+ (0.1,0) [0|819] "V"  CALTOOL
 SG_ BCASO_I_Chrg_short : 0|16@1+ (0.1,-819.2) [-819.2|819] "A"  CALTOOL

BO_ 657 BCC_OUT_DIAG_BALANCING_STAT_2: 8 HED
 SG_ BCASO_Balacing_Stat_11 : 16|8@1+ (1,0) [0|0] ""  CALTOOL
 SG_ BCASO_Balacing_Stat_10 : 8|8@1+ (1,0) [0|0] ""  CALTOOL
 SG_ BCASO_Balacing_Stat_09 : 0|8@1+ (1,0) [0|0] ""  CALTOOL

BO_ 656 BCC_OUT_DIAG_BALANCING_STAT_1: 8 HED
 SG_ BCASO_Balacing_Stat_08 : 56|8@1+ (1,0) [0|0] ""  CALTOOL
 SG_ BCASO_Balacing_Stat_07 : 48|8@1+ (1,0) [0|0] ""  CALTOOL
 SG_ BCASO_Balacing_Stat_06 : 40|8@1+ (1,0) [0|0] ""  CALTOOL
 SG_ BCASO_Balacing_Stat_05 : 32|8@1+ (1,0) [0|0] ""  CALTOOL
 SG_ BCASO_Balacing_Stat_04 : 24|8@1+ (1,0) [0|0] ""  CALTOOL
 SG_ BCASO_Balacing_Stat_03 : 16|8@1+ (1,0) [0|0] ""  CALTOOL
 SG_ BCASO_Balacing_Stat_02 : 8|8@1+ (1,0) [0|0] ""  CALTOOL
 SG_ BCASO_Balacing_Stat_01 : 0|8@1+ (1,0) [0|0] ""  CALTOOL

BO_ 593 BCC_OUT_BALANCING_065_128: 8 HED
 SG_ BCASO_Cell_Bal_Req_100 : 35|1@1+ (1,0) [0|0] ""  CALTOOL
 SG_ BCASO_Cell_Bal_Req_099 : 34|1@1+ (1,0) [0|0] ""  CALTOOL
 SG_ BCASO_Cell_Bal_Req_098 : 33|1@1+ (1,0) [0|0] ""  CALTOOL
 SG_ BCASO_Cell_Bal_Req_097 : 32|1@1+ (1,0) [0|0] ""  CALTOOL
 SG_ BCASO_Cell_Bal_Req_096 : 31|1@1+ (1,0) [0|0] ""  CALTOOL
 SG_ BCASO_Cell_Bal_Req_095 : 30|1@1+ (1,0) [0|0] ""  CALTOOL
 SG_ BCASO_Cell_Bal_Req_094 : 29|1@1+ (1,0) [0|0] ""  CALTOOL
 SG_ BCASO_Cell_Bal_Req_093 : 28|1@1+ (1,0) [0|0] ""  CALTOOL
 SG_ BCASO_Cell_Bal_Req_092 : 27|1@1+ (1,0) [0|0] ""  CALTOOL
 SG_ BCASO_Cell_Bal_Req_091 : 26|1@1+ (1,0) [0|0] ""  CALTOOL
 SG_ BCASO_Cell_Bal_Req_090 : 25|1@1+ (1,0) [0|0] ""  CALTOOL
 SG_ BCASO_Cell_Bal_Req_089 : 24|1@1+ (1,0) [0|0] ""  CALTOOL
 SG_ BCASO_Cell_Bal_Req_088 : 23|1@1+ (1,0) [0|0] ""  CALTOOL
 SG_ BCASO_Cell_Bal_Req_087 : 22|1@1+ (1,0) [0|0] ""  CALTOOL
 SG_ BCASO_Cell_Bal_Req_086 : 21|1@1+ (1,0) [0|0] ""  CALTOOL
 SG_ BCASO_Cell_Bal_Req_085 : 20|1@1+ (1,0) [0|0] ""  CALTOOL
 SG_ BCASO_Cell_Bal_Req_084 : 19|1@1+ (1,0) [0|0] ""  CALTOOL
 SG_ BCASO_Cell_Bal_Req_083 : 18|1@1+ (1,0) [0|0] ""  CALTOOL
 SG_ BCASO_Cell_Bal_Req_082 : 17|1@1+ (1,0) [0|0] ""  CALTOOL
 SG_ BCASO_Cell_Bal_Req_081 : 16|1@1+ (1,0) [0|0] ""  CALTOOL
 SG_ BCASO_Cell_Bal_Req_080 : 15|1@1+ (1,0) [0|0] ""  CALTOOL
 SG_ BCASO_Cell_Bal_Req_079 : 14|1@1+ (1,0) [0|0] ""  CALTOOL
 SG_ BCASO_Cell_Bal_Req_078 : 13|1@1+ (1,0) [0|0] ""  CALTOOL
 SG_ BCASO_Cell_Bal_Req_077 : 12|1@1+ (1,0) [0|0] ""  CALTOOL
 SG_ BCASO_Cell_Bal_Req_076 : 11|1@1+ (1,0) [0|0] ""  CALTOOL
 SG_ BCASO_Cell_Bal_Req_075 : 10|1@1+ (1,0) [0|0] ""  CALTOOL
 SG_ BCASO_Cell_Bal_Req_074 : 9|1@1+ (1,0) [0|0] ""  CALTOOL
 SG_ BCASO_Cell_Bal_Req_073 : 8|1@1+ (1,0) [0|0] ""  CALTOOL
 SG_ BCASO_Cell_Bal_Req_072 : 7|1@1+ (1,0) [0|0] ""  CALTOOL
 SG_ BCASO_Cell_Bal_Req_071 : 6|1@1+ (1,0) [0|0] ""  CALTOOL
 SG_ BCASO_Cell_Bal_Req_070 : 5|1@1+ (1,0) [0|0] ""  CALTOOL
 SG_ BCASO_Cell_Bal_Req_069 : 4|1@1+ (1,0) [0|0] ""  CALTOOL
 SG_ BCASO_Cell_Bal_Req_068 : 3|1@1+ (1,0) [0|0] ""  CALTOOL
 SG_ BCASO_Cell_Bal_Req_067 : 2|1@1+ (1,0) [0|0] ""  CALTOOL
 SG_ BCASO_Cell_Bal_Req_066 : 1|1@1+ (1,0) [0|0] ""  CALTOOL
 SG_ BCASO_Cell_Bal_Req_065 : 0|1@1+ (1,0) [0|0] ""  CALTOOL

BO_ 592 BCC_OUT_BALANCING_001_064: 8 HED
 SG_ BCASO_Cell_Bal_Req_064 : 63|1@1+ (1,0) [0|0] ""  CALTOOL
 SG_ BCASO_Cell_Bal_Req_063 : 62|1@1+ (1,0) [0|0] ""  CALTOOL
 SG_ BCASO_Cell_Bal_Req_062 : 61|1@1+ (1,0) [0|0] ""  CALTOOL
 SG_ BCASO_Cell_Bal_Req_061 : 60|1@1+ (1,0) [0|0] ""  CALTOOL
 SG_ BCASO_Cell_Bal_Req_060 : 59|1@1+ (1,0) [0|0] ""  CALTOOL
 SG_ BCASO_Cell_Bal_Req_059 : 58|1@1+ (1,0) [0|0] ""  CALTOOL
 SG_ BCASO_Cell_Bal_Req_058 : 57|1@1+ (1,0) [0|0] ""  CALTOOL
 SG_ BCASO_Cell_Bal_Req_057 : 56|1@1+ (1,0) [0|0] ""  CALTOOL
 SG_ BCASO_Cell_Bal_Req_056 : 55|1@1+ (1,0) [0|0] ""  CALTOOL
 SG_ BCASO_Cell_Bal_Req_055 : 54|1@1+ (1,0) [0|0] ""  CALTOOL
 SG_ BCASO_Cell_Bal_Req_054 : 53|1@1+ (1,0) [0|0] ""  CALTOOL
 SG_ BCASO_Cell_Bal_Req_053 : 52|1@1+ (1,0) [0|0] ""  CALTOOL
 SG_ BCASO_Cell_Bal_Req_052 : 51|1@1+ (1,0) [0|0] ""  CALTOOL
 SG_ BCASO_Cell_Bal_Req_051 : 50|1@1+ (1,0) [0|0] ""  CALTOOL
 SG_ BCASO_Cell_Bal_Req_050 : 49|1@1+ (1,0) [0|0] ""  CALTOOL
 SG_ BCASO_Cell_Bal_Req_049 : 48|1@1+ (1,0) [0|0] ""  CALTOOL
 SG_ BCASO_Cell_Bal_Req_048 : 47|1@1+ (1,0) [0|0] ""  CALTOOL
 SG_ BCASO_Cell_Bal_Req_047 : 46|1@1+ (1,0) [0|0] ""  CALTOOL
 SG_ BCASO_Cell_Bal_Req_046 : 45|1@1+ (1,0) [0|0] ""  CALTOOL
 SG_ BCASO_Cell_Bal_Req_045 : 44|1@1+ (1,0) [0|0] ""  CALTOOL
 SG_ BCASO_Cell_Bal_Req_044 : 43|1@1+ (1,0) [0|0] ""  CALTOOL
 SG_ BCASO_Cell_Bal_Req_043 : 42|1@1+ (1,0) [0|0] ""  CALTOOL
 SG_ BCASO_Cell_Bal_Req_042 : 41|1@1+ (1,0) [0|0] ""  CALTOOL
 SG_ BCASO_Cell_Bal_Req_041 : 40|1@1+ (1,0) [0|0] ""  CALTOOL
 SG_ BCASO_Cell_Bal_Req_040 : 39|1@1+ (1,0) [0|0] ""  CALTOOL
 SG_ BCASO_Cell_Bal_Req_039 : 38|1@1+ (1,0) [0|0] ""  CALTOOL
 SG_ BCASO_Cell_Bal_Req_038 : 37|1@1+ (1,0) [0|0] ""  CALTOOL
 SG_ BCASO_Cell_Bal_Req_037 : 36|1@1+ (1,0) [0|0] ""  CALTOOL
 SG_ BCASO_Cell_Bal_Req_036 : 35|1@1+ (1,0) [0|0] ""  CALTOOL
 SG_ BCASO_Cell_Bal_Req_035 : 34|1@1+ (1,0) [0|0] ""  CALTOOL
 SG_ BCASO_Cell_Bal_Req_034 : 33|1@1+ (1,0) [0|0] ""  CALTOOL
 SG_ BCASO_Cell_Bal_Req_033 : 32|1@1+ (1,0) [0|0] ""  CALTOOL
 SG_ BCASO_Cell_Bal_Req_032 : 31|1@1+ (1,0) [0|0] ""  CALTOOL
 SG_ BCASO_Cell_Bal_Req_031 : 30|1@1+ (1,0) [0|0] ""  CALTOOL
 SG_ BCASO_Cell_Bal_Req_030 : 29|1@1+ (1,0) [0|0] ""  CALTOOL
 SG_ BCASO_Cell_Bal_Req_029 : 28|1@1+ (1,0) [0|0] ""  CALTOOL
 SG_ BCASO_Cell_Bal_Req_028 : 27|1@1+ (1,0) [0|0] ""  CALTOOL
 SG_ BCASO_Cell_Bal_Req_027 : 26|1@1+ (1,0) [0|0] ""  CALTOOL
 SG_ BCASO_Cell_Bal_Req_026 : 25|1@1+ (1,0) [0|0] ""  CALTOOL
 SG_ BCASO_Cell_Bal_Req_025 : 24|1@1+ (1,0) [0|0] ""  CALTOOL
 SG_ BCASO_Cell_Bal_Req_024 : 23|1@1+ (1,0) [0|0] ""  CALTOOL
 SG_ BCASO_Cell_Bal_Req_023 : 22|1@1+ (1,0) [0|0] ""  CALTOOL
 SG_ BCASO_Cell_Bal_Req_022 : 21|1@1+ (1,0) [0|0] ""  CALTOOL
 SG_ BCASO_Cell_Bal_Req_021 : 20|1@1+ (1,0) [0|0] ""  CALTOOL
 SG_ BCASO_Cell_Bal_Req_020 : 19|1@1+ (1,0) [0|0] ""  CALTOOL
 SG_ BCASO_Cell_Bal_Req_019 : 18|1@1+ (1,0) [0|0] ""  CALTOOL
 SG_ BCASO_Cell_Bal_Req_018 : 17|1@1+ (1,0) [0|0] ""  CALTOOL
 SG_ BCASO_Cell_Bal_Req_017 : 16|1@1+ (1,0) [0|0] ""  CALTOOL
 SG_ BCASO_Cell_Bal_Req_016 : 15|1@1+ (1,0) [0|0] ""  CALTOOL
 SG_ BCASO_Cell_Bal_Req_015 : 14|1@1+ (1,0) [0|0] ""  CALTOOL
 SG_ BCASO_Cell_Bal_Req_014 : 13|1@1+ (1,0) [0|0] ""  CALTOOL
 SG_ BCASO_Cell_Bal_Req_013 : 12|1@1+ (1,0) [0|0] ""  CALTOOL
 SG_ BCASO_Cell_Bal_Req_012 : 11|1@1+ (1,0) [0|0] ""  CALTOOL
 SG_ BCASO_Cell_Bal_Req_011 : 10|1@1+ (1,0) [0|0] ""  CALTOOL
 SG_ BCASO_Cell_Bal_Req_010 : 9|1@1+ (1,0) [0|0] ""  CALTOOL
 SG_ BCASO_Cell_Bal_Req_009 : 8|1@1+ (1,0) [0|0] ""  CALTOOL
 SG_ BCASO_Cell_Bal_Req_008 : 7|1@1+ (1,0) [0|0] ""  CALTOOL
 SG_ BCASO_Cell_Bal_Req_007 : 6|1@1+ (1,0) [0|0] ""  CALTOOL
 SG_ BCASO_Cell_Bal_Req_006 : 5|1@1+ (1,0) [0|0] ""  CALTOOL
 SG_ BCASO_Cell_Bal_Req_005 : 4|1@1+ (1,0) [0|0] ""  CALTOOL
 SG_ BCASO_Cell_Bal_Req_004 : 3|1@1+ (1,0) [0|0] ""  CALTOOL
 SG_ BCASO_Cell_Bal_Req_003 : 2|1@1+ (1,0) [0|0] ""  CALTOOL
 SG_ BCASO_Cell_Bal_Req_002 : 1|1@1+ (1,0) [0|0] ""  CALTOOL
 SG_ BCASO_Cell_Bal_Req_001 : 0|1@1+ (1,0) [0|0] ""  CALTOOL

CM_ SG_ 309 BCC_T_Batt_06 "Batterietemperatur";
CM_ SG_ 309 BCC_T_Batt_05 "Batterietemperatur";
CM_ SG_ 308 BCC_T_Batt_04 "Batterietemperatur";
CM_ SG_ 308 BCC_T_Batt_03 "Batterietemperatur";
CM_ SG_ 307 BCC_T_Batt_02 "Batterietemperatur";
CM_ SG_ 307 BCC_T_Batt_01 "Batterietemperatur";
CM_ BO_ 1793 "Informations about the Isolation measerument";
CM_ SG_ 1793 Iso_Res_01 "Isowert in Ohm/V analog zum CAN Signal in der P08-2 VehicleCAN dbc";
CM_ SG_ 1793 Iso_Meas_res "Iso Measurement response";
CM_ SG_ 1793 Iso_Res "Iso Resistance";
CM_ SG_ 661 SW_OP_Mode "Information about Basis-SW-Mode";
CM_ SG_ 279 BCC_Time_Sw_Open "Zeit dem letzten Öffnen der Schütze";
CM_ SG_ 276 BCC_Number_of_Temperatures "Zahl der Temperatursensoren";
CM_ SG_ 276 BCC_Number_of_Cells "Zellenzahl";
CM_ SG_ 276 BCC_Reset_U_Limit_Req "Zurücksetzen der Spannungsgrenzen wird angefordert";
CM_ SG_ 276 BCC_Recalibrate_Mode "Antwort vom Energiemanagement auf die Recalibrate_Request";
CM_ SG_ 276 BCC_NV_Data_SNA_Mode "EEPROM Data ungueltig";
CM_ SG_ 276 BCC_NoCurr_Req "Strom null wird benötigt.";
CM_ SG_ 276 BCC_KL50 "Status der KL50";
CM_ SG_ 276 BCC_KL15 "Status der KL15";
CM_ SG_ 276 BCC_EM_Volt_Derate_Mode "Spannungsabregelung der elektrischen Maschine ist aktiv. Ab PC5";
CM_ SG_ 276 BCC_EEPROM_Mode "Neue SW wurde geflashed";
CM_ SG_ 276 BCC_Cyclic_Mode "BCC ist  im Cyclic_Mode. BMS wacht zyklisch auf.";
CM_ SG_ 276 BCC_Continuous_Mode "BCC ist im Continuierlichen Modus";
CM_ SG_ 299 BCC_Diag_Capa_As_1 "battery capacity value set by diagnosis";
CM_ SG_ 299 BCC_Balancing_U_Target "Wert aus Diagnose bei aktiver Diagnose. Skalierung ist an CDD Bedatung angepasst.";
CM_ SG_ 299 BCC_Diag_OCV_Mode "gueltige Diagnose OCV Werte werden übergeben";
CM_ SG_ 299 BCC_Diag_Capa_Mode "gueltiger Diagnose Capa Wert wird übergeben";
CM_ SG_ 299 BCC_Balancing_Mode "Ansteuerung des Balancing über Diagnose.";
CM_ SG_ 277 BCC_OBL_HVDC_Voltage "OnBoard Charger HVDC Output Voltage";
CM_ SG_ 277 BCC_OBL_HVDC_Current "OnBoard Charger HVDC Output Current";
CM_ SG_ 277 BCC_OBL_HVDC_Voltage_SNA_Mode "OBL HVDC Output Voltage SNA Identifier";
CM_ SG_ 277 BCC_OBL_HVDC_Current_SNA_Mode "OBL HVDC Output Current Signal SNA";
CM_ SG_ 277 BCC_OBL_BMS_Wakeup_State "Status, ob Aktivierung durch OBL erfolgte";
CM_ SG_ 277 BCC_OBL_BMS_Wakeup_SNA_Mode "Gültigkeitsflag für Signal BSIG_OBL_BMS_Wakeup_State";
CM_ SG_ 278 BCC_RTC "RealTimeClock 0 to 2.147.483.647sec Auflösung 1sek";
CM_ SG_ 278 BCC_RTC_SNA_Mode "Signal nicht verfügbar";
CM_ SG_ 282 BCC_Ibatt_Substitute_Value "Vom Energiemanagement berechneter Ersatzwert für den Batteriestrom";
CM_ SG_ 282 BCC_Ibatt_Substitute_Mode "BCC_Ibatt_Substitute_Mode zeigt die Plausibilität von BCC_Ibatt_Substitute_Value an";
CM_ SG_ 282 BCC_I_Batt_SNA_Mode "Valid Flag for the battery current";
CM_ SG_ 282 BCC_I_Batt_Filter_SNA_Mode "Signal nicht verfügbar";
CM_ SG_ 306 BCC_CoolantInletTemp "Vorlauf-Kühlwasser-Temperatur";
CM_ SG_ 281 BCC_I_Batt_Filtered "aktueller HV-Batteriestrom gefiltert";
CM_ SG_ 281 BCC_I_Batt "The acual (last measured) battery current";
CM_ SG_ 280 BCC_Ubatt_Substitute_Value "Vom Energiemanagement berechneter Ersatzwert für die Batteriespannung";
CM_ SG_ 280 BCC_U_Batt "The battery voltage";
CM_ SG_ 280 BCC_Ubatt_Substitute_Mode "BCC_Ubatt_Substitute_Mode zeigt die Plausibilität von BCC_Ubatt_Substitute_Value an";
CM_ SG_ 280 BCC_U_Batt_SNA_Mode "Signal nicht verfügbar";
CM_ SG_ 305 BCC_T_Cool "Kühlmitteltemperatur Einlaß";
CM_ SG_ 305 BCC_T_Amb "Außentemperatur";
CM_ SG_ 305 BCC_T_Cool_SNA_Mode "Signal nicht verfügbar";
CM_ SG_ 385 BCC_SwitchingValveStage_State "Status der H Brueckenendstufe zur Ansteuerung des Umschaltventils";
CM_ SG_ 385 BCC_FanStage_State "Status der Endstufe zur Ansteuerung des Kuehler Luefter Relais";
CM_ SG_ 385 BCC_SwitchingValve_Mode "Ansteuerung des Switch Valve (Kühlung) über Diagnose.";
CM_ SG_ 385 BCC_SwitchingValve_Cmd "Wert aus Diagnose zur SwitchValve Ansteuerung.";
CM_ SG_ 385 BCC_FanReq_Mode "Anforderung Kuehlerluefter (CAN)";
CM_ SG_ 385 BCC_FanRelay_Mode "Ansteuerung des Aktors über Diagnose";
CM_ SG_ 385 BCC_FanRelay_Cmd "Wert aus Diagnose zur Fanrelais Anteuerung";
CM_ SG_ 384 BCC_CoolingComp_State "Function indicating status of cooling compressor. Wird im smart Projekt nicht benoetigt.";
CM_ SG_ 384 BCC_CoolingCircuit_State "Return status of cooling circuit.";
CM_ SG_ 384 BCC_CoolantPump_State "Status Wasserpumpe";
CM_ SG_ 384 BCC_CoolantPump_Cmd "Wert aus Diagnose zur Kühlpumpenansteuerung.";
CM_ SG_ 384 BCC_ChillerValveStage_State "Status der Endstufe zur Ansteuerung des Chiller Ventil (im Kältekreislauf)";
CM_ SG_ 384 BCC_CoolCirc_Actv_Mode "EKMV aktiv (HVAC_CoolCirc_Actv)";
CM_ SG_ 384 BCC_CoolantPump_Mode "Ansteuerung der Kühlpumpe über Diagnose.";
CM_ SG_ 384 BCC_ChillerValve_Mode "Ansteuerung des ChillerValve erfolgt ueber Diagnose.";
CM_ SG_ 384 BCC_ChillerValve_En_Mode "Freigabe von HVAC fuer Chiller Ventil";
CM_ SG_ 384 BCC_ChillerValve_Cmd "Wert aus Diagnose bei aktiver Diagnoseansteuerung";
CM_ SG_ 384 BCC_BMS_CoolVlv_Mode "Status Kühlkreis-Ventil Versorgungsbatterie Hochspannungs-Bordnetz (0 - closed / 1 - open)";
CM_ SG_ 384 BCC_AC_Cool_Mode "Zeigt an ob der Klimakompressor läuft kommt vom SMART Klimasteuergerät via CAN und zeigt an ob der Kompressor aktiviert wurde";
CM_ SG_ 337 BCC_U_Cell_008 "Einzelzellspannung";
CM_ SG_ 337 BCC_U_Cell_007 "Einzelzellspannung";
CM_ SG_ 337 BCC_U_Cell_006 "Einzelzellspannung";
CM_ SG_ 337 BCC_U_Cell_005 "Einzelzellspannung";
CM_ SG_ 336 BCC_U_Cell_004 "Einzelzellspannung";
CM_ SG_ 336 BCC_U_Cell_003 "Einzelzellspannung";
CM_ SG_ 336 BCC_U_Cell_002 "Einzelzellspannung";
CM_ SG_ 336 BCC_U_Cell_001 "Einzelzellspannung";
CM_ SG_ 298 BCC_Diag_OCV_Arr21_1mV_21 "momentane OCV-Kennlinie (aufsteigend, SOC-abhängig in 5% Schritten) der HV-Batterie (Stützstelle 100%)";
CM_ SG_ 297 BCC_Diag_OCV_Arr21_1mV_20 "momentane OCV-Kennlinie (aufsteigend, SOC-abhängig in 5% Schritten) der HV-Batterie (Stützstelle 95%)";
CM_ SG_ 297 BCC_Diag_OCV_Arr21_1mV_19 "momentane OCV-Kennlinie (aufsteigend, SOC-abhängig in 5% Schritten) der HV-Batterie (Stützstelle 90%)";
CM_ SG_ 296 BCC_Diag_OCV_Arr21_1mV_18 "momentane OCV-Kennlinie (aufsteigend, SOC-abhängig in 5% Schritten) der HV-Batterie (Stützstelle 85%)";
CM_ SG_ 296 BCC_Diag_OCV_Arr21_1mV_17 "momentane OCV-Kennlinie (aufsteigend, SOC-abhängig in 5% Schritten) der HV-Batterie (Stützstelle 80%)";
CM_ SG_ 295 BCC_Diag_OCV_Arr21_1mV_16 "momentane OCV-Kennlinie (aufsteigend, SOC-abhängig in 5% Schritten) der HV-Batterie (Stützstelle 75%)";
CM_ SG_ 295 BCC_Diag_OCV_Arr21_1mV_15 "momentane OCV-Kennlinie (aufsteigend, SOC-abhängig in 5% Schritten) der HV-Batterie (Stützstelle 70%)";
CM_ SG_ 294 BCC_Diag_OCV_Arr21_1mV_14 "momentane OCV-Kennlinie (aufsteigend, SOC-abhängig in 5% Schritten) der HV-Batterie (Stützstelle 65%)";
CM_ SG_ 294 BCC_Diag_OCV_Arr21_1mV_13 "momentane OCV-Kennlinie (aufsteigend, SOC-abhängig in 5% Schritten) der HV-Batterie (Stützstelle 60%)";
CM_ SG_ 293 BCC_Diag_OCV_Arr21_1mV_12 "momentane OCV-Kennlinie (aufsteigend, SOC-abhängig in 5% Schritten) der HV-Batterie (Stützstelle 55%)";
CM_ SG_ 293 BCC_Diag_OCV_Arr21_1mV_11 "momentane OCV-Kennlinie (aufsteigend, SOC-abhängig in 5% Schritten) der HV-Batterie (Stützstelle 50%)";
CM_ SG_ 292 BCC_Diag_OCV_Arr21_1mV_10 "momentane OCV-Kennlinie (aufsteigend, SOC-abhängig in 5% Schritten) der HV-Batterie (Stützstelle 45%)";
CM_ SG_ 292 BCC_Diag_OCV_Arr21_1mV_09 "momentane OCV-Kennlinie (aufsteigend, SOC-abhängig in 5% Schritten) der HV-Batterie (Stützstelle 40%)";
CM_ SG_ 291 BCC_Diag_OCV_Arr21_1mV_08 "momentane OCV-Kennlinie (aufsteigend, SOC-abhängig in 5% Schritten) der HV-Batterie (Stützstelle 35%)";
CM_ SG_ 291 BCC_Diag_OCV_Arr21_1mV_07 "momentane OCV-Kennlinie (aufsteigend, SOC-abhängig in 5% Schritten) der HV-Batterie (Stützstelle 30%)";
CM_ SG_ 290 BCC_Diag_OCV_Arr21_1mV_06 "momentane OCV-Kennlinie (aufsteigend, SOC-abhängig in 5% Schritten) der HV-Batterie (Stützstelle 25%)";
CM_ SG_ 290 BCC_Diag_OCV_Arr21_1mV_05 "momentane OCV-Kennlinie (aufsteigend, SOC-abhängig in 5% Schritten) der HV-Batterie (Stützstelle 20%)";
CM_ SG_ 289 BCC_Diag_OCV_Arr21_1mV_04 "momentane OCV-Kennlinie (aufsteigend, SOC-abhängig in 5% Schritten) der HV-Batterie (Stützstelle 15%)";
CM_ SG_ 289 BCC_Diag_OCV_Arr21_1mV_03 "momentane OCV-Kennlinie (aufsteigend, SOC-abhängig in 5% Schritten) der HV-Batterie (Stützstelle 10%)";
CM_ SG_ 288 BCC_Diag_OCV_Arr21_1mV_02 "momentane OCV-Kennlinie (aufsteigend, SOC-abhängig in 5% Schritten) der HV-Batterie (Stützstelle 5%)";
CM_ SG_ 288 BCC_Diag_OCV_Arr21_1mV_01 "momentane OCV-Kennlinie (aufsteigend, SOC-abhängig in 5% Schritten) der HV-Batterie (Stützstelle 0%)";
CM_ SG_ 331 BCC_U_Cell_SNA_Mode_100 "Signal nicht verfügbar";
CM_ SG_ 331 BCC_U_Cell_SNA_Mode_099 "Signal nicht verfügbar";
CM_ SG_ 331 BCC_U_Cell_SNA_Mode_098 "Signal nicht verfügbar";
CM_ SG_ 331 BCC_U_Cell_SNA_Mode_097 "Signal nicht verfügbar";
CM_ SG_ 331 BCC_U_Cell_SNA_Mode_096 "Signal nicht verfügbar";
CM_ SG_ 331 BCC_U_Cell_SNA_Mode_095 "Signal nicht verfügbar";
CM_ SG_ 331 BCC_U_Cell_SNA_Mode_094 "Signal nicht verfügbar";
CM_ SG_ 331 BCC_U_Cell_SNA_Mode_093 "Signal nicht verfügbar";
CM_ SG_ 331 BCC_U_Cell_SNA_Mode_092 "Signal nicht verfügbar";
CM_ SG_ 331 BCC_U_Cell_SNA_Mode_091 "Signal nicht verfügbar";
CM_ SG_ 331 BCC_U_Cell_SNA_Mode_090 "Signal nicht verfügbar";
CM_ SG_ 331 BCC_U_Cell_SNA_Mode_089 "Signal nicht verfügbar";
CM_ SG_ 331 BCC_U_Cell_SNA_Mode_088 "Signal nicht verfügbar";
CM_ SG_ 331 BCC_U_Cell_SNA_Mode_087 "Signal nicht verfügbar";
CM_ SG_ 331 BCC_U_Cell_SNA_Mode_086 "Signal nicht verfügbar";
CM_ SG_ 331 BCC_U_Cell_SNA_Mode_085 "Signal nicht verfügbar";
CM_ SG_ 331 BCC_U_Cell_SNA_Mode_084 "Signal nicht verfügbar";
CM_ SG_ 331 BCC_U_Cell_SNA_Mode_083 "Signal nicht verfügbar";
CM_ SG_ 331 BCC_U_Cell_SNA_Mode_082 "Signal nicht verfügbar";
CM_ SG_ 331 BCC_U_Cell_SNA_Mode_081 "Signal nicht verfügbar";
CM_ SG_ 331 BCC_U_Cell_SNA_Mode_080 "Signal nicht verfügbar";
CM_ SG_ 331 BCC_U_Cell_SNA_Mode_079 "Signal nicht verfügbar";
CM_ SG_ 331 BCC_U_Cell_SNA_Mode_078 "Signal nicht verfügbar";
CM_ SG_ 331 BCC_U_Cell_SNA_Mode_077 "Signal nicht verfügbar";
CM_ SG_ 331 BCC_U_Cell_SNA_Mode_076 "Signal nicht verfügbar";
CM_ SG_ 331 BCC_U_Cell_SNA_Mode_075 "Signal nicht verfügbar";
CM_ SG_ 331 BCC_U_Cell_SNA_Mode_074 "Signal nicht verfügbar";
CM_ SG_ 331 BCC_U_Cell_SNA_Mode_073 "Signal nicht verfügbar";
CM_ SG_ 331 BCC_U_Cell_SNA_Mode_072 "Signal nicht verfügbar";
CM_ SG_ 331 BCC_U_Cell_SNA_Mode_071 "Signal nicht verfügbar";
CM_ SG_ 331 BCC_U_Cell_SNA_Mode_070 "Signal nicht verfügbar";
CM_ SG_ 331 BCC_U_Cell_SNA_Mode_069 "Signal nicht verfügbar";
CM_ SG_ 331 BCC_U_Cell_SNA_Mode_068 "Signal nicht verfügbar";
CM_ SG_ 331 BCC_U_Cell_SNA_Mode_067 "Signal nicht verfügbar";
CM_ SG_ 331 BCC_U_Cell_SNA_Mode_066 "Signal nicht verfügbar";
CM_ SG_ 331 BCC_U_Cell_SNA_Mode_065 "Signal nicht verfügbar";
CM_ SG_ 304 BCC_T_Batt_SNA_Mode_30 "Signal nicht verfügbar";
CM_ SG_ 304 BCC_T_Batt_SNA_Mode_29 "Signal nicht verfügbar";
CM_ SG_ 304 BCC_T_Batt_SNA_Mode_28 "Signal nicht verfügbar";
CM_ SG_ 304 BCC_T_Batt_SNA_Mode_27 "Signal nicht verfügbar";
CM_ SG_ 304 BCC_T_Batt_SNA_Mode_26 "Signal nicht verfügbar";
CM_ SG_ 304 BCC_T_Batt_SNA_Mode_25 "Signal nicht verfügbar";
CM_ SG_ 304 BCC_T_Batt_SNA_Mode_24 "Signal nicht verfügbar";
CM_ SG_ 304 BCC_T_Batt_SNA_Mode_23 "Signal nicht verfügbar";
CM_ SG_ 304 BCC_T_Batt_SNA_Mode_22 "Signal nicht verfügbar";
CM_ SG_ 304 BCC_T_Batt_SNA_Mode_21 "Signal nicht verfügbar";
CM_ SG_ 304 BCC_T_Batt_SNA_Mode_20 "Signal nicht verfügbar";
CM_ SG_ 304 BCC_T_Batt_SNA_Mode_19 "Signal nicht verfügbar";
CM_ SG_ 304 BCC_T_Batt_SNA_Mode_18 "Signal nicht verfügbar";
CM_ SG_ 304 BCC_T_Batt_SNA_Mode_17 "Signal nicht verfügbar";
CM_ SG_ 304 BCC_T_Batt_SNA_Mode_16 "Signal nicht verfügbar";
CM_ SG_ 304 BCC_T_Batt_SNA_Mode_15 "Signal nicht verfügbar";
CM_ SG_ 304 BCC_T_Batt_SNA_Mode_14 "Signal nicht verfügbar";
CM_ SG_ 304 BCC_T_Batt_SNA_Mode_13 "Signal nicht verfügbar";
CM_ SG_ 304 BCC_T_Batt_SNA_Mode_12 "Signal nicht verfügbar";
CM_ SG_ 304 BCC_T_Batt_SNA_Mode_11 "Signal nicht verfügbar";
CM_ SG_ 304 BCC_T_Batt_SNA_Mode_10 "Signal nicht verfügbar";
CM_ SG_ 304 BCC_T_Batt_SNA_Mode_09 "Signal nicht verfügbar";
CM_ SG_ 304 BCC_T_Batt_SNA_Mode_08 "Signal nicht verfügbar";
CM_ SG_ 304 BCC_T_Batt_SNA_Mode_07 "Signal nicht verfügbar";
CM_ SG_ 304 BCC_T_Batt_SNA_Mode_06 "Signal nicht verfügbar";
CM_ SG_ 304 BCC_T_Batt_SNA_Mode_05 "Signal nicht verfügbar";
CM_ SG_ 304 BCC_T_Batt_SNA_Mode_04 "Signal nicht verfügbar";
CM_ SG_ 304 BCC_T_Batt_SNA_Mode_03 "Signal nicht verfügbar";
CM_ SG_ 304 BCC_T_Batt_SNA_Mode_02 "Signal nicht verfügbar";
CM_ SG_ 304 BCC_T_Batt_SNA_Mode_01 "Signal nicht verfügbar";
CM_ SG_ 304 BCC_T_Batt "Batterietemperatur";
CM_ SG_ 560 BCASO_U_Batt_Sum_of_U_Cell "Summe aller Einzelzellspannungen";
CM_ SG_ 560 BCASO_I_Batt_Filtered "Signal für MessCAN";
CM_ SG_ 571 BCASO_Time_Sw_Open "Zeit dem letzten Öffnen der Schütze";
CM_ SG_ 563 BCASO_SwitchOpenChargeEnd_Rq "Flag für Ladeende an Energiemanagment, um die Hauptschütze lastfrei öffnen zu können (0 = Laddung möglich / 1 = Ladungsende erreicht)";
CM_ SG_ 563 BCASO_Recalibrate_Req "Ladezustand-Rekalibrierungsanforderung an Energiemanagement, um für ein bestimmtes Zeitintervall Antrieb und Verbraucher lastfrei zu schalten (0 = keine Anforderung / 1 = Anforderung)
";
CM_ SG_ 563 BCASO_OCV_Mode "BCC CASO OpenCollectorVoltage of HV-Battery";
CM_ SG_ 563 BCASO_Diag_OCV_Mode "gueltige Diagnose OCV Werte sind übergeben";
CM_ SG_ 563 BCASO_Diag_Capa_Mode "gueltiger Diagnose Capa Wert ist übergeben";
CM_ SG_ 563 BCASO_Bal_Finished_Mode "Alle Zellen sind ausgeglichen, das Ladezustands-Balancing ist abgeschlossen.";
CM_ SG_ 563 BCASO_NoCurr_Req "Strom null wird benötigt.";
CM_ SG_ 562 BCASO_Waterpump_Cmd "Tastverhältnis des PWM-Signals zur Kühlungspumpenansteuerung";
CM_ SG_ 562 BCASO_CoolantInletTemp "Vorlauf-Kühlwasser-Temperatur";
CM_ SG_ 562 BCASO_CoolAmount_Rq "Kühlungsbedarf für die Klimaanlage (AC)";
CM_ SG_ 562 BCASO_SwitchingValve_Cmd "Kommando für das Umschaltventil (0 = Kühler / 1 = Chiller)";
CM_ SG_ 562 BCASO_Fan_Cmd "Kommando für die Lüfteransteuerung (0 = Lüfter aus / 1 = Lüfter an)";
CM_ SG_ 562 BCASO_CoolValve_Req "Anforderung des Kühlventils (0 = open, 1 = closed)";
CM_ SG_ 562 BCASO_ChillerValve_Cmd "Kommando für das Chillerventil (0 = Ventil zu / 1 = Ventil auf)";
CM_ SG_ 562 BCASO_Batt_Cool_Req "Kühlanforderung der HV-Batterie";
CM_ SG_ 561 BCASO_CapaHV_As_ref_1 "Im DRAM gespeicherter Wert für die Batteriekapazität [As] als Basis zur Berechnung für SOC. Hier werden alterungsbedingte Verluste in den nichtflüchtigen Speicher geschrieben.";
CM_ SG_ 561 BCASO_CapaHV_As_act_1 "Im DRAM gespeicherter Wert für die Batteriekapazität [As] als Basis zur Berechnung für SOC. Hier werden alterungsbedingte Verluste in den nichtflüchtigen Speicher geschrieben.";
CM_ SG_ 569 BCASO_SOC_Min "SOC von 0...100%";
CM_ SG_ 569 BCASO_SOC_Max "SOC von 0...100%";
CM_ SG_ 568 BCASO_SOC_Disp "Batterie-SOC für die Fahreranzeige";
CM_ SG_ 568 BCASO_SOC "SOC von 0...100%";
CM_ SG_ 330 BCC_U_Cell_SNA_Mode_064 "Signal nicht verfügbar";
CM_ SG_ 330 BCC_U_Cell_SNA_Mode_063 "Signal nicht verfügbar";
CM_ SG_ 330 BCC_U_Cell_SNA_Mode_062 "Signal nicht verfügbar";
CM_ SG_ 330 BCC_U_Cell_SNA_Mode_061 "Signal nicht verfügbar";
CM_ SG_ 330 BCC_U_Cell_SNA_Mode_059 "Signal nicht verfügbar";
CM_ SG_ 330 BCC_U_Cell_SNA_Mode_058 "Signal nicht verfügbar";
CM_ SG_ 330 BCC_U_Cell_SNA_Mode_057 "Signal nicht verfügbar";
CM_ SG_ 330 BCC_U_Cell_SNA_Mode_056 "Signal nicht verfügbar";
CM_ SG_ 330 BCC_U_Cell_SNA_Mode_055 "Signal nicht verfügbar";
CM_ SG_ 330 BCC_U_Cell_SNA_Mode_054 "Signal nicht verfügbar";
CM_ SG_ 330 BCC_U_Cell_SNA_Mode_053 "Signal nicht verfügbar";
CM_ SG_ 330 BCC_U_Cell_SNA_Mode_052 "Signal nicht verfügbar";
CM_ SG_ 330 BCC_U_Cell_SNA_Mode_051 "Signal nicht verfügbar";
CM_ SG_ 330 BCC_U_Cell_SNA_Mode_050 "Signal nicht verfügbar";
CM_ SG_ 330 BCC_U_Cell_SNA_Mode_049 "Signal nicht verfügbar";
CM_ SG_ 330 BCC_U_Cell_SNA_Mode_048 "Signal nicht verfügbar";
CM_ SG_ 330 BCC_U_Cell_SNA_Mode_047 "Signal nicht verfügbar";
CM_ SG_ 330 BCC_U_Cell_SNA_Mode_046 "Signal nicht verfügbar";
CM_ SG_ 330 BCC_U_Cell_SNA_Mode_045 "Signal nicht verfügbar";
CM_ SG_ 330 BCC_U_Cell_SNA_Mode_044 "Signal nicht verfügbar";
CM_ SG_ 330 BCC_U_Cell_SNA_Mode_043 "Signal nicht verfügbar";
CM_ SG_ 330 BCC_U_Cell_SNA_Mode_042 "Signal nicht verfügbar";
CM_ SG_ 330 BCC_U_Cell_SNA_Mode_041 "Signal nicht verfügbar";
CM_ SG_ 330 BCC_U_Cell_SNA_Mode_040 "Signal nicht verfügbar";
CM_ SG_ 330 BCC_U_Cell_SNA_Mode_039 "Signal nicht verfügbar";
CM_ SG_ 330 BCC_U_Cell_SNA_Mode_038 "Signal nicht verfügbar";
CM_ SG_ 330 BCC_U_Cell_SNA_Mode_037 "Signal nicht verfügbar";
CM_ SG_ 330 BCC_U_Cell_SNA_Mode_036 "Signal nicht verfügbar";
CM_ SG_ 330 BCC_U_Cell_SNA_Mode_035 "Signal nicht verfügbar";
CM_ SG_ 330 BCC_U_Cell_SNA_Mode_034 "Signal nicht verfügbar";
CM_ SG_ 330 BCC_U_Cell_SNA_Mode_033 "Signal nicht verfügbar";
CM_ SG_ 330 BCC_U_Cell_SNA_Mode_032 "Signal nicht verfügbar";
CM_ SG_ 330 BCC_U_Cell_SNA_Mode_031 "Signal nicht verfügbar";
CM_ SG_ 330 BCC_U_Cell_SNA_Mode_030 "Signal nicht verfügbar";
CM_ SG_ 330 BCC_U_Cell_SNA_Mode_029 "Signal nicht verfügbar";
CM_ SG_ 330 BCC_U_Cell_SNA_Mode_028 "Signal nicht verfügbar";
CM_ SG_ 330 BCC_U_Cell_SNA_Mode_027 "Signal nicht verfügbar";
CM_ SG_ 330 BCC_U_Cell_SNA_Mode_026 "Signal nicht verfügbar";
CM_ SG_ 330 BCC_U_Cell_SNA_Mode_025 "Signal nicht verfügbar";
CM_ SG_ 330 BCC_U_Cell_SNA_Mode_024 "Signal nicht verfügbar";
CM_ SG_ 330 BCC_U_Cell_SNA_Mode_023 "Signal nicht verfügbar";
CM_ SG_ 330 BCC_U_Cell_SNA_Mode_022 "Signal nicht verfügbar";
CM_ SG_ 330 BCC_U_Cell_SNA_Mode_021 "Signal nicht verfügbar";
CM_ SG_ 330 BCC_U_Cell_SNA_Mode_020 "Signal nicht verfügbar";
CM_ SG_ 330 BCC_U_Cell_SNA_Mode_019 "Signal nicht verfügbar";
CM_ SG_ 330 BCC_U_Cell_SNA_Mode_018 "Signal nicht verfügbar";
CM_ SG_ 330 BCC_U_Cell_SNA_Mode_017 "Signal nicht verfügbar";
CM_ SG_ 330 BCC_U_Cell_SNA_Mode_016 "Signal nicht verfügbar";
CM_ SG_ 330 BCC_U_Cell_SNA_Mode_015 "Signal nicht verfügbar";
CM_ SG_ 330 BCC_U_Cell_SNA_Mode_014 "Signal nicht verfügbar";
CM_ SG_ 330 BCC_U_Cell_SNA_Mode_013 "Signal nicht verfügbar";
CM_ SG_ 330 BCC_U_Cell_SNA_Mode_012 "Signal nicht verfügbar";
CM_ SG_ 330 BCC_U_Cell_SNA_Mode_011 "Signal nicht verfügbar";
CM_ SG_ 330 BCC_U_Cell_SNA_Mode_010 "Signal nicht verfügbar";
CM_ SG_ 330 BCC_U_Cell_SNA_Mode_009 "Signal nicht verfügbar";
CM_ SG_ 330 BCC_U_Cell_SNA_Mode_008 "Signal nicht verfügbar";
CM_ SG_ 330 BCC_U_Cell_SNA_Mode_007 "Signal nicht verfügbar";
CM_ SG_ 330 BCC_U_Cell_SNA_Mode_006 "Signal nicht verfügbar";
CM_ SG_ 330 BCC_U_Cell_SNA_Mode_005 "Signal nicht verfügbar";
CM_ SG_ 330 BCC_U_Cell_SNA_Mode_004 "Signal nicht verfügbar";
CM_ SG_ 330 BCC_U_Cell_SNA_Mode_003 "Signal nicht verfügbar";
CM_ SG_ 330 BCC_U_Cell_SNA_Mode_002 "Signal nicht verfügbar";
CM_ SG_ 330 BCC_U_Cell_SNA_Mode_001 "Signal nicht verfügbar";
CM_ SG_ 564 BCASO_I_Max_DisChrg "Maximaler Entladestrom";
CM_ SG_ 564 BCASO_I_Max_Chrg "Maximlaer Ladestrom";
CM_ SG_ 565 BCASO_U_Min "Minimum allowed battery voltage";
CM_ SG_ 565 BCASO_U_Max "Maximum allowed battery voltage";
CM_ SG_ 586 BCASO_OCV_Arr21_1mV_21 "momentane OCV-Kennlinie (aufsteigend, SOC-abhängig in 5% Schritten) der HV-Batterie (Stützstelle 100%)";
CM_ SG_ 585 BCASO_OCV_Arr21_1mV_20 "momentane OCV-Kennlinie (aufsteigend, SOC-abhängig in 5% Schritten) der HV-Batterie (Stützstelle 95%)";
CM_ SG_ 585 BCASO_OCV_Arr21_1mV_19 "momentane OCV-Kennlinie (aufsteigend, SOC-abhängig in 5% Schritten) der HV-Batterie (Stützstelle 90%)";
CM_ SG_ 584 BCASO_OCV_Arr21_1mV_18 "momentane OCV-Kennlinie (aufsteigend, SOC-abhängig in 5% Schritten) der HV-Batterie (Stützstelle 85%)";
CM_ SG_ 584 BCASO_OCV_Arr21_1mV_17 "momentane OCV-Kennlinie (aufsteigend, SOC-abhängig in 5% Schritten) der HV-Batterie (Stützstelle 80%)";
CM_ SG_ 583 BCASO_OCV_Arr21_1mV_16 "momentane OCV-Kennlinie (aufsteigend, SOC-abhängig in 5% Schritten) der HV-Batterie (Stützstelle 75%)";
CM_ SG_ 583 BCASO_OCV_Arr21_1mV_15 "momentane OCV-Kennlinie (aufsteigend, SOC-abhängig in 5% Schritten) der HV-Batterie (Stützstelle 70%)";
CM_ SG_ 582 BCASO_OCV_Arr21_1mV_14 "momentane OCV-Kennlinie (aufsteigend, SOC-abhängig in 5% Schritten) der HV-Batterie (Stützstelle 65%)";
CM_ SG_ 582 BCASO_OCV_Arr21_1mV_13 "momentane OCV-Kennlinie (aufsteigend, SOC-abhängig in 5% Schritten) der HV-Batterie (Stützstelle 60%)";
CM_ SG_ 581 BCASO_OCV_Arr21_1mV_12 "momentane OCV-Kennlinie (aufsteigend, SOC-abhängig in 5% Schritten) der HV-Batterie (Stützstelle 55%)";
CM_ SG_ 581 BCASO_OCV_Arr21_1mV_11 "momentane OCV-Kennlinie (aufsteigend, SOC-abhängig in 5% Schritten) der HV-Batterie (Stützstelle 50%)";
CM_ SG_ 580 BCASO_OCV_Arr21_1mV_10 "momentane OCV-Kennlinie (aufsteigend, SOC-abhängig in 5% Schritten) der HV-Batterie (Stützstelle 45%)";
CM_ SG_ 580 BCASO_OCV_Arr21_1mV_09 "momentane OCV-Kennlinie (aufsteigend, SOC-abhängig in 5% Schritten) der HV-Batterie (Stützstelle 40%)";
CM_ SG_ 579 BCASO_OCV_Arr21_1mV_08 "momentane OCV-Kennlinie (aufsteigend, SOC-abhängig in 5% Schritten) der HV-Batterie (Stützstelle 35%)";
CM_ SG_ 579 BCASO_OCV_Arr21_1mV_07 "momentane OCV-Kennlinie (aufsteigend, SOC-abhängig in 5% Schritten) der HV-Batterie (Stützstelle 30%)";
CM_ SG_ 578 BCASO_OCV_Arr21_1mV_06 "momentane OCV-Kennlinie (aufsteigend, SOC-abhängig in 5% Schritten) der HV-Batterie (Stützstelle 25%)";
CM_ SG_ 578 BCASO_OCV_Arr21_1mV_05 "momentane OCV-Kennlinie (aufsteigend, SOC-abhängig in 5% Schritten) der HV-Batterie (Stützstelle 20%)";
CM_ SG_ 577 BCASO_OCV_Arr21_1mV_04 "momentane OCV-Kennlinie (aufsteigend, SOC-abhängig in 5% Schritten) der HV-Batterie (Stützstelle 15%)";
CM_ SG_ 577 BCASO_OCV_Arr21_1mV_03 "momentane OCV-Kennlinie (aufsteigend, SOC-abhängig in 5% Schritten) der HV-Batterie (Stützstelle 10%)";
CM_ SG_ 576 BCASO_OCV_Arr21_1mV_02 "momentane OCV-Kennlinie (aufsteigend, SOC-abhängig in 5% Schritten) der HV-Batterie (Stützstelle 5%)";
CM_ SG_ 576 BCASO_OCV_Arr21_1mV_01 "momentane OCV-Kennlinie (aufsteigend, SOC-abhängig in 5% Schritten) der HV-Batterie (Stützstelle 0%)";
CM_ SG_ 566 BCASO_U_Dchrg_long "Spannungswert der langfristigen Prädiktion für die Entladung";
CM_ SG_ 566 BCASO_I_Dchrg_long "Stromwert der langfristigen Prädiktion für die Entladung";
CM_ SG_ 566 BCASO_U_Chrg_long "Spannungswert der langfristigen Prädiktion für die Ladung";
CM_ SG_ 566 BCASO_I_Chrg_long "Stromwert der langfristigen Prädiktion für die Ladung";
CM_ SG_ 567 BCASO_U_Dchrg_short "Spannungswert der kurzzeitigen Prädiktion für die Enladung";
CM_ SG_ 567 BCASO_I_Dchrg_short "Stromwert der kurzzeitigen Prädiktion für die Entladung";
CM_ SG_ 567 BCASO_U_Chrg_short "Spannungswert der kurzzeitigen Prädiktion für die Ladung";
CM_ SG_ 567 BCASO_I_Chrg_short "Stromwert der kurzzeitigen Prädiktion für die Ladung";
CM_ SG_ 657 BCASO_Balacing_Stat_11 "Datenantwort des Balancing bei Diagnoseanforderung (Byte 11)";
CM_ SG_ 657 BCASO_Balacing_Stat_10 "Datenantwort des Balancing bei Diagnoseanforderung (Byte 10)";
CM_ SG_ 657 BCASO_Balacing_Stat_09 "Datenantwort des Balancing bei Diagnoseanforderung (Byte 9)";
CM_ SG_ 656 BCASO_Balacing_Stat_08 "Datenantwort des Balancing bei Diagnoseanforderung (Byte 8)";
CM_ SG_ 656 BCASO_Balacing_Stat_07 "Datenantwort des Balancing bei Diagnoseanforderung (Byte 7)";
CM_ SG_ 656 BCASO_Balacing_Stat_06 "Datenantwort des Balancing bei Diagnoseanforderung (Byte 6)";
CM_ SG_ 656 BCASO_Balacing_Stat_05 "Datenantwort des Balancing bei Diagnoseanforderung (Byte 5)";
CM_ SG_ 656 BCASO_Balacing_Stat_04 "Datenantwort des Balancing bei Diagnoseanforderung (Byte 4)";
CM_ SG_ 656 BCASO_Balacing_Stat_03 "Datenantwort des Balancing bei Diagnoseanforderung (Byte 3)";
CM_ SG_ 656 BCASO_Balacing_Stat_02 "Datenantwort des Balancing bei Diagnoseanforderung (Byte 2)";
CM_ SG_ 656 BCASO_Balacing_Stat_01 "Datenantwort des Balancing bei Diagnoseanforderung (Byte 1)";
CM_ SG_ 593 BCASO_Cell_Bal_Req_100 "Flag zur Aktivierung des Entladewiderstands auf Zellebene";
CM_ SG_ 593 BCASO_Cell_Bal_Req_099 "Flag zur Aktivierung des Entladewiderstands auf Zellebene";
CM_ SG_ 593 BCASO_Cell_Bal_Req_098 "Flag zur Aktivierung des Entladewiderstands auf Zellebene";
CM_ SG_ 593 BCASO_Cell_Bal_Req_097 "Flag zur Aktivierung des Entladewiderstands auf Zellebene";
CM_ SG_ 593 BCASO_Cell_Bal_Req_096 "Flag zur Aktivierung des Entladewiderstands auf Zellebene";
CM_ SG_ 593 BCASO_Cell_Bal_Req_095 "Flag zur Aktivierung des Entladewiderstands auf Zellebene";
CM_ SG_ 593 BCASO_Cell_Bal_Req_094 "Flag zur Aktivierung des Entladewiderstands auf Zellebene";
CM_ SG_ 593 BCASO_Cell_Bal_Req_093 "Flag zur Aktivierung des Entladewiderstands auf Zellebene";
CM_ SG_ 593 BCASO_Cell_Bal_Req_092 "Flag zur Aktivierung des Entladewiderstands auf Zellebene";
CM_ SG_ 593 BCASO_Cell_Bal_Req_091 "Flag zur Aktivierung des Entladewiderstands auf Zellebene";
CM_ SG_ 593 BCASO_Cell_Bal_Req_090 "Flag zur Aktivierung des Entladewiderstands auf Zellebene";
CM_ SG_ 593 BCASO_Cell_Bal_Req_089 "Flag zur Aktivierung des Entladewiderstands auf Zellebene";
CM_ SG_ 593 BCASO_Cell_Bal_Req_088 "Flag zur Aktivierung des Entladewiderstands auf Zellebene";
CM_ SG_ 593 BCASO_Cell_Bal_Req_087 "Flag zur Aktivierung des Entladewiderstands auf Zellebene";
CM_ SG_ 593 BCASO_Cell_Bal_Req_086 "Flag zur Aktivierung des Entladewiderstands auf Zellebene";
CM_ SG_ 593 BCASO_Cell_Bal_Req_085 "Flag zur Aktivierung des Entladewiderstands auf Zellebene";
CM_ SG_ 593 BCASO_Cell_Bal_Req_084 "Flag zur Aktivierung des Entladewiderstands auf Zellebene";
CM_ SG_ 593 BCASO_Cell_Bal_Req_083 "Flag zur Aktivierung des Entladewiderstands auf Zellebene";
CM_ SG_ 593 BCASO_Cell_Bal_Req_082 "Flag zur Aktivierung des Entladewiderstands auf Zellebene";
CM_ SG_ 593 BCASO_Cell_Bal_Req_081 "Flag zur Aktivierung des Entladewiderstands auf Zellebene";
CM_ SG_ 593 BCASO_Cell_Bal_Req_080 "Flag zur Aktivierung des Entladewiderstands auf Zellebene";
CM_ SG_ 593 BCASO_Cell_Bal_Req_079 "Flag zur Aktivierung des Entladewiderstands auf Zellebene";
CM_ SG_ 593 BCASO_Cell_Bal_Req_078 "Flag zur Aktivierung des Entladewiderstands auf Zellebene";
CM_ SG_ 593 BCASO_Cell_Bal_Req_077 "Flag zur Aktivierung des Entladewiderstands auf Zellebene";
CM_ SG_ 593 BCASO_Cell_Bal_Req_076 "Flag zur Aktivierung des Entladewiderstands auf Zellebene";
CM_ SG_ 593 BCASO_Cell_Bal_Req_075 "Flag zur Aktivierung des Entladewiderstands auf Zellebene";
CM_ SG_ 593 BCASO_Cell_Bal_Req_074 "Flag zur Aktivierung des Entladewiderstands auf Zellebene";
CM_ SG_ 593 BCASO_Cell_Bal_Req_073 "Flag zur Aktivierung des Entladewiderstands auf Zellebene";
CM_ SG_ 593 BCASO_Cell_Bal_Req_072 "Flag zur Aktivierung des Entladewiderstands auf Zellebene";
CM_ SG_ 593 BCASO_Cell_Bal_Req_071 "Flag zur Aktivierung des Entladewiderstands auf Zellebene";
CM_ SG_ 593 BCASO_Cell_Bal_Req_070 "Flag zur Aktivierung des Entladewiderstands auf Zellebene";
CM_ SG_ 593 BCASO_Cell_Bal_Req_069 "Flag zur Aktivierung des Entladewiderstands auf Zellebene";
CM_ SG_ 593 BCASO_Cell_Bal_Req_068 "Flag zur Aktivierung des Entladewiderstands auf Zellebene";
CM_ SG_ 593 BCASO_Cell_Bal_Req_067 "Flag zur Aktivierung des Entladewiderstands auf Zellebene";
CM_ SG_ 593 BCASO_Cell_Bal_Req_066 "Flag zur Aktivierung des Entladewiderstands auf Zellebene";
CM_ SG_ 593 BCASO_Cell_Bal_Req_065 "Flag zur Aktivierung des Entladewiderstands auf Zellebene";
CM_ SG_ 592 BCASO_Cell_Bal_Req_064 "Flag zur Aktivierung des Entladewiderstands auf Zellebene";
CM_ SG_ 592 BCASO_Cell_Bal_Req_063 "Flag zur Aktivierung des Entladewiderstands auf Zellebene";
CM_ SG_ 592 BCASO_Cell_Bal_Req_062 "Flag zur Aktivierung des Entladewiderstands auf Zellebene";
CM_ SG_ 592 BCASO_Cell_Bal_Req_061 "Flag zur Aktivierung des Entladewiderstands auf Zellebene";
CM_ SG_ 592 BCASO_Cell_Bal_Req_060 "Flag zur Aktivierung des Entladewiderstands auf Zellebene";
CM_ SG_ 592 BCASO_Cell_Bal_Req_059 "Flag zur Aktivierung des Entladewiderstands auf Zellebene";
CM_ SG_ 592 BCASO_Cell_Bal_Req_058 "Flag zur Aktivierung des Entladewiderstands auf Zellebene";
CM_ SG_ 592 BCASO_Cell_Bal_Req_057 "Flag zur Aktivierung des Entladewiderstands auf Zellebene";
CM_ SG_ 592 BCASO_Cell_Bal_Req_056 "Flag zur Aktivierung des Entladewiderstands auf Zellebene";
CM_ SG_ 592 BCASO_Cell_Bal_Req_055 "Flag zur Aktivierung des Entladewiderstands auf Zellebene";
CM_ SG_ 592 BCASO_Cell_Bal_Req_054 "Flag zur Aktivierung des Entladewiderstands auf Zellebene";
CM_ SG_ 592 BCASO_Cell_Bal_Req_053 "Flag zur Aktivierung des Entladewiderstands auf Zellebene";
CM_ SG_ 592 BCASO_Cell_Bal_Req_052 "Flag zur Aktivierung des Entladewiderstands auf Zellebene";
CM_ SG_ 592 BCASO_Cell_Bal_Req_051 "Flag zur Aktivierung des Entladewiderstands auf Zellebene";
CM_ SG_ 592 BCASO_Cell_Bal_Req_050 "Flag zur Aktivierung des Entladewiderstands auf Zellebene";
CM_ SG_ 592 BCASO_Cell_Bal_Req_049 "Flag zur Aktivierung des Entladewiderstands auf Zellebene";
CM_ SG_ 592 BCASO_Cell_Bal_Req_048 "Flag zur Aktivierung des Entladewiderstands auf Zellebene";
CM_ SG_ 592 BCASO_Cell_Bal_Req_047 "Flag zur Aktivierung des Entladewiderstands auf Zellebene";
CM_ SG_ 592 BCASO_Cell_Bal_Req_046 "Flag zur Aktivierung des Entladewiderstands auf Zellebene";
CM_ SG_ 592 BCASO_Cell_Bal_Req_045 "Flag zur Aktivierung des Entladewiderstands auf Zellebene";
CM_ SG_ 592 BCASO_Cell_Bal_Req_044 "Flag zur Aktivierung des Entladewiderstands auf Zellebene";
CM_ SG_ 592 BCASO_Cell_Bal_Req_043 "Flag zur Aktivierung des Entladewiderstands auf Zellebene";
CM_ SG_ 592 BCASO_Cell_Bal_Req_042 "Flag zur Aktivierung des Entladewiderstands auf Zellebene";
CM_ SG_ 592 BCASO_Cell_Bal_Req_041 "Flag zur Aktivierung des Entladewiderstands auf Zellebene";
CM_ SG_ 592 BCASO_Cell_Bal_Req_040 "Flag zur Aktivierung des Entladewiderstands auf Zellebene";
CM_ SG_ 592 BCASO_Cell_Bal_Req_039 "Flag zur Aktivierung des Entladewiderstands auf Zellebene";
CM_ SG_ 592 BCASO_Cell_Bal_Req_038 "Flag zur Aktivierung des Entladewiderstands auf Zellebene";
CM_ SG_ 592 BCASO_Cell_Bal_Req_037 "Flag zur Aktivierung des Entladewiderstands auf Zellebene";
CM_ SG_ 592 BCASO_Cell_Bal_Req_036 "Flag zur Aktivierung des Entladewiderstands auf Zellebene";
CM_ SG_ 592 BCASO_Cell_Bal_Req_035 "Flag zur Aktivierung des Entladewiderstands auf Zellebene";
CM_ SG_ 592 BCASO_Cell_Bal_Req_034 "Flag zur Aktivierung des Entladewiderstands auf Zellebene";
CM_ SG_ 592 BCASO_Cell_Bal_Req_033 "Flag zur Aktivierung des Entladewiderstands auf Zellebene";
CM_ SG_ 592 BCASO_Cell_Bal_Req_032 "Flag zur Aktivierung des Entladewiderstands auf Zellebene";
CM_ SG_ 592 BCASO_Cell_Bal_Req_031 "Flag zur Aktivierung des Entladewiderstands auf Zellebene";
CM_ SG_ 592 BCASO_Cell_Bal_Req_030 "Flag zur Aktivierung des Entladewiderstands auf Zellebene";
CM_ SG_ 592 BCASO_Cell_Bal_Req_029 "Flag zur Aktivierung des Entladewiderstands auf Zellebene";
CM_ SG_ 592 BCASO_Cell_Bal_Req_028 "Flag zur Aktivierung des Entladewiderstands auf Zellebene";
CM_ SG_ 592 BCASO_Cell_Bal_Req_027 "Flag zur Aktivierung des Entladewiderstands auf Zellebene";
CM_ SG_ 592 BCASO_Cell_Bal_Req_026 "Flag zur Aktivierung des Entladewiderstands auf Zellebene";
CM_ SG_ 592 BCASO_Cell_Bal_Req_025 "Flag zur Aktivierung des Entladewiderstands auf Zellebene";
CM_ SG_ 592 BCASO_Cell_Bal_Req_024 "Flag zur Aktivierung des Entladewiderstands auf Zellebene";
CM_ SG_ 592 BCASO_Cell_Bal_Req_023 "Flag zur Aktivierung des Entladewiderstands auf Zellebene";
CM_ SG_ 592 BCASO_Cell_Bal_Req_022 "Flag zur Aktivierung des Entladewiderstands auf Zellebene";
CM_ SG_ 592 BCASO_Cell_Bal_Req_021 "Flag zur Aktivierung des Entladewiderstands auf Zellebene";
CM_ SG_ 592 BCASO_Cell_Bal_Req_020 "Flag zur Aktivierung des Entladewiderstands auf Zellebene";
CM_ SG_ 592 BCASO_Cell_Bal_Req_019 "Flag zur Aktivierung des Entladewiderstands auf Zellebene";
CM_ SG_ 592 BCASO_Cell_Bal_Req_018 "Flag zur Aktivierung des Entladewiderstands auf Zellebene";
CM_ SG_ 592 BCASO_Cell_Bal_Req_017 "Flag zur Aktivierung des Entladewiderstands auf Zellebene";
CM_ SG_ 592 BCASO_Cell_Bal_Req_016 "Flag zur Aktivierung des Entladewiderstands auf Zellebene";
CM_ SG_ 592 BCASO_Cell_Bal_Req_015 "Flag zur Aktivierung des Entladewiderstands auf Zellebene";
CM_ SG_ 592 BCASO_Cell_Bal_Req_014 "Flag zur Aktivierung des Entladewiderstands auf Zellebene";
CM_ SG_ 592 BCASO_Cell_Bal_Req_013 "Flag zur Aktivierung des Entladewiderstands auf Zellebene";
CM_ SG_ 592 BCASO_Cell_Bal_Req_012 "Flag zur Aktivierung des Entladewiderstands auf Zellebene";
CM_ SG_ 592 BCASO_Cell_Bal_Req_011 "Flag zur Aktivierung des Entladewiderstands auf Zellebene";
CM_ SG_ 592 BCASO_Cell_Bal_Req_010 "Flag zur Aktivierung des Entladewiderstands auf Zellebene";
CM_ SG_ 592 BCASO_Cell_Bal_Req_009 "Flag zur Aktivierung des Entladewiderstands auf Zellebene";
CM_ SG_ 592 BCASO_Cell_Bal_Req_008 "Flag zur Aktivierung des Entladewiderstands auf Zellebene";
CM_ SG_ 592 BCASO_Cell_Bal_Req_007 "Flag zur Aktivierung des Entladewiderstands auf Zellebene";
CM_ SG_ 592 BCASO_Cell_Bal_Req_006 "Flag zur Aktivierung des Entladewiderstands auf Zellebene";
CM_ SG_ 592 BCASO_Cell_Bal_Req_005 "Flag zur Aktivierung des Entladewiderstands auf Zellebene";
CM_ SG_ 592 BCASO_Cell_Bal_Req_004 "Flag zur Aktivierung des Entladewiderstands auf Zellebene";
CM_ SG_ 592 BCASO_Cell_Bal_Req_003 "Flag zur Aktivierung des Entladewiderstands auf Zellebene";
CM_ SG_ 592 BCASO_Cell_Bal_Req_002 "Flag zur Aktivierung des Entladewiderstands auf Zellebene";
CM_ SG_ 592 BCASO_Cell_Bal_Req_001 "Flag zur Aktivierung des Entladewiderstands auf Zellebene";
BA_DEF_ SG_  "FlexKomSigLaenge" INT 1 64;
BA_DEF_ SG_  "GenSigDataID" STRING ;
BA_DEF_ SG_  "GenSigFuncType" ENUM  "NoFunction","MsgCounter","CRC-8","XOR","XOR-2","DatedBit","SW-KL15","not-used","Constant","Protocol","CRC-8-SAE_J1850","PROFILE_DAI_BR222_ID","PROFILE_DAI_BR222_noID","PROFILE_DAI_SAEJ","PROFILE_02";
BA_DEF_ SG_  "GenSigCycleTime" INT 0 0;
BA_DEF_ BO_  "App-Botschaft" ENUM  "nein","ja";
BA_DEF_ BO_  "GenMsgMinAcceptLength" INT 0 8;
BA_DEF_ BO_  "GenMsgStartDelayTime" INT 0 65535;
BA_DEF_ BO_  "GenMsgILSupport" ENUM  "No","Yes";
BA_DEF_ BO_  "GenMsgCycleTime" INT 0 50000;
BA_DEF_ BO_  "GenMsgSendType" ENUM  "cyclicX","spontanX","cyclicIfActiveX","spontanWithDelay","cyclicAndSpontanX","cyclicAndSpontanWithDelay","spontanWithRepitition","cyclicIfActiveAndSpontanWD","cyclicIfActiveFast","cyclicWithRepeatOnDemand","none";
BA_DEF_ SG_  "GenSigSendType" ENUM  "cyclicX","spontanX","cyclicIfActiveX","spontanWithDelay","cyclicAndSpontanX","cyclicAndSpontanWithDelay","spontanWithRepitition","cyclicIfActiveAndSpontanWD","cyclicIfActiveFast","cyclicWithRepeatOnDemand","none";
BA_DEF_ SG_  "GenSigStartValue" FLOAT 0 100000000000;
BA_DEF_DEF_  "FlexKomSigLaenge" 1;
BA_DEF_DEF_  "GenSigDataID" "0xFF";
BA_DEF_DEF_  "GenSigFuncType" "NoFunction";
BA_DEF_DEF_  "GenSigCycleTime" 0;
BA_DEF_DEF_  "App-Botschaft" "nein";
BA_DEF_DEF_  "GenMsgMinAcceptLength" 8;
BA_DEF_DEF_  "GenMsgStartDelayTime" 0;
BA_DEF_DEF_  "GenMsgILSupport" "Yes";
BA_DEF_DEF_  "GenMsgCycleTime" 0;
BA_DEF_DEF_  "GenMsgSendType" "none";
BA_DEF_DEF_  "GenSigSendType" "none";
BA_DEF_DEF_  "GenSigStartValue" 0;
BA_ "GenMsgCycleTime" BO_ 539 10;
BA_ "GenMsgSendType" BO_ 539 1;
BA_ "GenMsgCycleTime" BO_ 309 100;
BA_ "GenMsgSendType" BO_ 309 1;
BA_ "GenMsgStartDelayTime" BO_ 309 25;
BA_ "GenMsgCycleTime" BO_ 308 100;
BA_ "GenMsgSendType" BO_ 308 1;
BA_ "GenMsgStartDelayTime" BO_ 308 25;
BA_ "GenMsgCycleTime" BO_ 307 100;
BA_ "GenMsgSendType" BO_ 307 1;
BA_ "GenMsgStartDelayTime" BO_ 307 25;
BA_ "GenMsgSendType" BO_ 16 1;
BA_ "GenMsgCycleTime" BO_ 16 50;
BA_ "GenMsgStartDelayTime" BO_ 16 5;
BA_ "GenMsgSendType" BO_ 547 1;
BA_ "GenMsgCycleTime" BO_ 547 10;
BA_ "GenMsgSendType" BO_ 540 1;
BA_ "GenMsgCycleTime" BO_ 540 100;
BA_ "GenMsgStartDelayTime" BO_ 540 75;
BA_ "GenMsgSendType" BO_ 1795 1;
BA_ "GenMsgCycleTime" BO_ 1795 1000;
BA_ "GenMsgStartDelayTime" BO_ 1795 95;
BA_ "GenMsgSendType" BO_ 1793 1;
BA_ "GenMsgCycleTime" BO_ 1793 100;
BA_ "GenMsgStartDelayTime" BO_ 1793 85;
BA_ "GenMsgSendType" BO_ 609 1;
BA_ "GenMsgCycleTime" BO_ 609 100;
BA_ "GenMsgStartDelayTime" BO_ 609 85;
BA_ "GenMsgSendType" BO_ 661 1;
BA_ "GenMsgCycleTime" BO_ 661 100;
BA_ "GenMsgStartDelayTime" BO_ 661 85;
BA_ "GenMsgSendType" BO_ 279 1;
BA_ "GenMsgCycleTime" BO_ 279 100;
BA_ "GenMsgStartDelayTime" BO_ 279 15;
BA_ "GenMsgSendType" BO_ 276 1;
BA_ "GenMsgCycleTime" BO_ 276 100;
BA_ "GenMsgStartDelayTime" BO_ 276 15;
BA_ "GenMsgSendType" BO_ 299 1;
BA_ "GenMsgCycleTime" BO_ 299 100;
BA_ "GenMsgStartDelayTime" BO_ 299 25;
BA_ "GenMsgSendType" BO_ 277 1;
BA_ "GenMsgCycleTime" BO_ 277 100;
BA_ "GenMsgStartDelayTime" BO_ 277 15;
BA_ "GenMsgSendType" BO_ 278 1;
BA_ "GenMsgCycleTime" BO_ 278 100;
BA_ "GenMsgStartDelayTime" BO_ 278 15;
BA_ "GenMsgSendType" BO_ 282 1;
BA_ "GenMsgCycleTime" BO_ 282 10;
BA_ "GenMsgStartDelayTime" BO_ 282 15;
BA_ "GenMsgSendType" BO_ 306 1;
BA_ "GenMsgCycleTime" BO_ 306 100;
BA_ "GenMsgStartDelayTime" BO_ 306 25;
BA_ "GenMsgSendType" BO_ 281 1;
BA_ "GenMsgCycleTime" BO_ 281 10;
BA_ "GenMsgStartDelayTime" BO_ 281 15;
BA_ "GenMsgSendType" BO_ 280 1;
BA_ "GenMsgCycleTime" BO_ 280 100;
BA_ "GenMsgStartDelayTime" BO_ 280 15;
BA_ "GenMsgSendType" BO_ 305 1;
BA_ "GenMsgCycleTime" BO_ 305 100;
BA_ "GenMsgStartDelayTime" BO_ 305 25;
BA_ "GenMsgSendType" BO_ 385 1;
BA_ "GenMsgCycleTime" BO_ 385 100;
BA_ "GenMsgStartDelayTime" BO_ 385 65;
BA_ "GenMsgSendType" BO_ 384 1;
BA_ "GenMsgCycleTime" BO_ 384 100;
BA_ "GenMsgStartDelayTime" BO_ 384 65;
BA_ "GenMsgSendType" BO_ 365 1;
BA_ "GenMsgCycleTime" BO_ 365 10;
BA_ "GenMsgStartDelayTime" BO_ 365 45;
BA_ "GenMsgSendType" BO_ 364 1;
BA_ "GenMsgCycleTime" BO_ 364 10;
BA_ "GenMsgStartDelayTime" BO_ 364 45;
BA_ "GenMsgSendType" BO_ 363 1;
BA_ "GenMsgCycleTime" BO_ 363 10;
BA_ "GenMsgStartDelayTime" BO_ 363 45;
BA_ "GenMsgSendType" BO_ 362 1;
BA_ "GenMsgCycleTime" BO_ 362 10;
BA_ "GenMsgStartDelayTime" BO_ 362 45;
BA_ "GenMsgSendType" BO_ 361 1;
BA_ "GenMsgCycleTime" BO_ 361 10;
BA_ "GenMsgStartDelayTime" BO_ 361 45;
BA_ "GenMsgSendType" BO_ 360 1;
BA_ "GenMsgCycleTime" BO_ 360 10;
BA_ "GenMsgStartDelayTime" BO_ 360 45;
BA_ "GenMsgSendType" BO_ 359 1;
BA_ "GenMsgCycleTime" BO_ 359 10;
BA_ "GenMsgStartDelayTime" BO_ 359 45;
BA_ "GenMsgSendType" BO_ 358 1;
BA_ "GenMsgCycleTime" BO_ 358 10;
BA_ "GenMsgStartDelayTime" BO_ 358 45;
BA_ "GenMsgSendType" BO_ 357 1;
BA_ "GenMsgCycleTime" BO_ 357 10;
BA_ "GenMsgStartDelayTime" BO_ 357 45;
BA_ "GenMsgSendType" BO_ 356 1;
BA_ "GenMsgCycleTime" BO_ 356 10;
BA_ "GenMsgStartDelayTime" BO_ 356 45;
BA_ "GenMsgSendType" BO_ 355 1;
BA_ "GenMsgCycleTime" BO_ 355 10;
BA_ "GenMsgStartDelayTime" BO_ 355 45;
BA_ "GenMsgSendType" BO_ 354 1;
BA_ "GenMsgCycleTime" BO_ 354 10;
BA_ "GenMsgStartDelayTime" BO_ 354 45;
BA_ "GenMsgSendType" BO_ 353 1;
BA_ "GenMsgCycleTime" BO_ 353 10;
BA_ "GenMsgStartDelayTime" BO_ 353 45;
BA_ "GenMsgSendType" BO_ 352 1;
BA_ "GenMsgCycleTime" BO_ 352 10;
BA_ "GenMsgStartDelayTime" BO_ 352 45;
BA_ "GenMsgSendType" BO_ 351 1;
BA_ "GenMsgCycleTime" BO_ 351 10;
BA_ "GenMsgStartDelayTime" BO_ 351 45;
BA_ "GenMsgSendType" BO_ 350 1;
BA_ "GenMsgCycleTime" BO_ 350 10;
BA_ "GenMsgStartDelayTime" BO_ 350 35;
BA_ "GenMsgSendType" BO_ 349 1;
BA_ "GenMsgCycleTime" BO_ 349 10;
BA_ "GenMsgStartDelayTime" BO_ 349 35;
BA_ "GenMsgSendType" BO_ 348 1;
BA_ "GenMsgCycleTime" BO_ 348 10;
BA_ "GenMsgStartDelayTime" BO_ 348 35;
BA_ "GenMsgSendType" BO_ 347 1;
BA_ "GenMsgCycleTime" BO_ 347 10;
BA_ "GenMsgStartDelayTime" BO_ 347 35;
BA_ "GenMsgSendType" BO_ 346 1;
BA_ "GenMsgCycleTime" BO_ 346 10;
BA_ "GenMsgStartDelayTime" BO_ 346 35;
BA_ "GenMsgSendType" BO_ 345 1;
BA_ "GenMsgCycleTime" BO_ 345 10;
BA_ "GenMsgStartDelayTime" BO_ 345 35;
BA_ "GenMsgSendType" BO_ 344 1;
BA_ "GenMsgCycleTime" BO_ 344 10;
BA_ "GenMsgStartDelayTime" BO_ 344 35;
BA_ "GenMsgSendType" BO_ 343 1;
BA_ "GenMsgCycleTime" BO_ 343 10;
BA_ "GenMsgStartDelayTime" BO_ 343 35;
BA_ "GenMsgSendType" BO_ 342 1;
BA_ "GenMsgCycleTime" BO_ 342 10;
BA_ "GenMsgStartDelayTime" BO_ 342 35;
BA_ "GenMsgSendType" BO_ 341 1;
BA_ "GenMsgCycleTime" BO_ 341 10;
BA_ "GenMsgStartDelayTime" BO_ 341 35;
BA_ "GenMsgSendType" BO_ 340 1;
BA_ "GenMsgCycleTime" BO_ 340 10;
BA_ "GenMsgStartDelayTime" BO_ 340 35;
BA_ "GenMsgSendType" BO_ 339 1;
BA_ "GenMsgCycleTime" BO_ 339 10;
BA_ "GenMsgStartDelayTime" BO_ 339 35;
BA_ "GenMsgSendType" BO_ 338 1;
BA_ "GenMsgCycleTime" BO_ 338 10;
BA_ "GenMsgStartDelayTime" BO_ 338 35;
BA_ "GenMsgSendType" BO_ 337 1;
BA_ "GenMsgCycleTime" BO_ 337 10;
BA_ "GenMsgStartDelayTime" BO_ 337 35;
BA_ "GenMsgSendType" BO_ 336 1;
BA_ "GenMsgCycleTime" BO_ 336 10;
BA_ "GenMsgStartDelayTime" BO_ 336 35;
BA_ "GenMsgSendType" BO_ 298 1;
BA_ "GenMsgCycleTime" BO_ 298 100;
BA_ "GenMsgStartDelayTime" BO_ 298 15;
BA_ "GenMsgSendType" BO_ 297 1;
BA_ "GenMsgCycleTime" BO_ 297 100;
BA_ "GenMsgStartDelayTime" BO_ 297 15;
BA_ "GenMsgSendType" BO_ 296 1;
BA_ "GenMsgCycleTime" BO_ 296 100;
BA_ "GenMsgStartDelayTime" BO_ 296 15;
BA_ "GenMsgSendType" BO_ 295 1;
BA_ "GenMsgCycleTime" BO_ 295 100;
BA_ "GenMsgStartDelayTime" BO_ 295 15;
BA_ "GenMsgSendType" BO_ 294 1;
BA_ "GenMsgCycleTime" BO_ 294 100;
BA_ "GenMsgStartDelayTime" BO_ 294 15;
BA_ "GenMsgSendType" BO_ 293 1;
BA_ "GenMsgCycleTime" BO_ 293 100;
BA_ "GenMsgStartDelayTime" BO_ 293 15;
BA_ "GenMsgSendType" BO_ 292 1;
BA_ "GenMsgCycleTime" BO_ 292 100;
BA_ "GenMsgStartDelayTime" BO_ 292 15;
BA_ "GenMsgSendType" BO_ 291 1;
BA_ "GenMsgCycleTime" BO_ 291 100;
BA_ "GenMsgStartDelayTime" BO_ 291 15;
BA_ "GenMsgSendType" BO_ 290 1;
BA_ "GenMsgCycleTime" BO_ 290 100;
BA_ "GenMsgStartDelayTime" BO_ 290 15;
BA_ "GenMsgSendType" BO_ 289 1;
BA_ "GenMsgCycleTime" BO_ 289 100;
BA_ "GenMsgStartDelayTime" BO_ 289 15;
BA_ "GenMsgSendType" BO_ 288 1;
BA_ "GenMsgCycleTime" BO_ 288 100;
BA_ "GenMsgStartDelayTime" BO_ 288 15;
BA_ "GenMsgSendType" BO_ 331 1;
BA_ "GenMsgCycleTime" BO_ 331 100;
BA_ "GenMsgStartDelayTime" BO_ 331 35;
BA_ "GenMsgSendType" BO_ 304 1;
BA_ "GenMsgCycleTime" BO_ 304 100;
BA_ "GenMsgStartDelayTime" BO_ 304 25;
BA_ "GenMsgSendType" BO_ 560 1;
BA_ "GenMsgCycleTime" BO_ 560 100;
BA_ "GenMsgStartDelayTime" BO_ 560 75;
BA_ "GenMsgSendType" BO_ 571 1;
BA_ "GenMsgCycleTime" BO_ 571 100;
BA_ "GenMsgStartDelayTime" BO_ 571 75;
BA_ "GenMsgSendType" BO_ 563 1;
BA_ "GenMsgCycleTime" BO_ 563 100;
BA_ "GenMsgStartDelayTime" BO_ 563 75;
BA_ "GenMsgSendType" BO_ 572 1;
BA_ "GenMsgCycleTime" BO_ 572 100;
BA_ "GenMsgStartDelayTime" BO_ 572 75;
BA_ "GenMsgSendType" BO_ 570 1;
BA_ "GenMsgCycleTime" BO_ 570 100;
BA_ "GenMsgStartDelayTime" BO_ 570 75;
BA_ "GenMsgSendType" BO_ 562 1;
BA_ "GenMsgCycleTime" BO_ 562 100;
BA_ "GenMsgStartDelayTime" BO_ 562 75;
BA_ "GenMsgSendType" BO_ 561 1;
BA_ "GenMsgCycleTime" BO_ 561 100;
BA_ "GenMsgStartDelayTime" BO_ 561 75;
BA_ "GenMsgSendType" BO_ 569 1;
BA_ "GenMsgCycleTime" BO_ 569 100;
BA_ "GenMsgStartDelayTime" BO_ 569 75;
BA_ "GenMsgSendType" BO_ 568 1;
BA_ "GenMsgCycleTime" BO_ 568 100;
BA_ "GenMsgStartDelayTime" BO_ 568 75;
BA_ "GenMsgSendType" BO_ 330 1;
BA_ "GenMsgCycleTime" BO_ 330 100;
BA_ "GenMsgStartDelayTime" BO_ 330 35;
BA_ "GenMsgSendType" BO_ 564 1;
BA_ "GenMsgCycleTime" BO_ 564 100;
BA_ "GenMsgStartDelayTime" BO_ 564 75;
BA_ "GenMsgSendType" BO_ 565 1;
BA_ "GenMsgCycleTime" BO_ 565 100;
BA_ "GenMsgStartDelayTime" BO_ 565 75;
BA_ "GenMsgSendType" BO_ 586 1;
BA_ "GenMsgCycleTime" BO_ 586 100;
BA_ "GenMsgStartDelayTime" BO_ 586 85;
BA_ "GenMsgSendType" BO_ 585 1;
BA_ "GenMsgCycleTime" BO_ 585 100;
BA_ "GenMsgStartDelayTime" BO_ 585 85;
BA_ "GenMsgSendType" BO_ 584 1;
BA_ "GenMsgCycleTime" BO_ 584 100;
BA_ "GenMsgStartDelayTime" BO_ 584 85;
BA_ "GenMsgSendType" BO_ 583 1;
BA_ "GenMsgCycleTime" BO_ 583 100;
BA_ "GenMsgStartDelayTime" BO_ 583 85;
BA_ "GenMsgSendType" BO_ 582 1;
BA_ "GenMsgCycleTime" BO_ 582 100;
BA_ "GenMsgStartDelayTime" BO_ 582 85;
BA_ "GenMsgSendType" BO_ 581 1;
BA_ "GenMsgCycleTime" BO_ 581 100;
BA_ "GenMsgStartDelayTime" BO_ 581 85;
BA_ "GenMsgSendType" BO_ 580 1;
BA_ "GenMsgCycleTime" BO_ 580 100;
BA_ "GenMsgStartDelayTime" BO_ 580 85;
BA_ "GenMsgSendType" BO_ 579 1;
BA_ "GenMsgCycleTime" BO_ 579 100;
BA_ "GenMsgStartDelayTime" BO_ 579 85;
BA_ "GenMsgSendType" BO_ 578 1;
BA_ "GenMsgCycleTime" BO_ 578 100;
BA_ "GenMsgStartDelayTime" BO_ 578 75;
BA_ "GenMsgSendType" BO_ 577 1;
BA_ "GenMsgCycleTime" BO_ 577 100;
BA_ "GenMsgStartDelayTime" BO_ 577 75;
BA_ "GenMsgSendType" BO_ 576 1;
BA_ "GenMsgCycleTime" BO_ 576 100;
BA_ "GenMsgStartDelayTime" BO_ 576 75;
BA_ "GenMsgSendType" BO_ 566 1;
BA_ "GenMsgCycleTime" BO_ 566 100;
BA_ "GenMsgStartDelayTime" BO_ 566 75;
BA_ "GenMsgSendType" BO_ 567 1;
BA_ "GenMsgCycleTime" BO_ 567 100;
BA_ "GenMsgStartDelayTime" BO_ 567 75;
BA_ "GenMsgSendType" BO_ 657 1;
BA_ "GenMsgCycleTime" BO_ 657 100;
BA_ "GenMsgStartDelayTime" BO_ 657 85;
BA_ "GenMsgSendType" BO_ 656 1;
BA_ "GenMsgCycleTime" BO_ 656 100;
BA_ "GenMsgStartDelayTime" BO_ 656 85;
BA_ "GenMsgSendType" BO_ 593 1;
BA_ "GenMsgCycleTime" BO_ 593 100;
BA_ "GenMsgStartDelayTime" BO_ 593 85;
BA_ "GenMsgSendType" BO_ 592 1;
BA_ "GenMsgCycleTime" BO_ 592 100;
BA_ "GenMsgStartDelayTime" BO_ 592 85;
BA_ "GenSigCycleTime" SG_ 539 SAC_E_MSW_AGE_WARN 10;
BA_ "GenSigSendType" SG_ 539 SAC_E_MSW_AGE_WARN 1;
BA_ "GenSigCycleTime" SG_ 539 SAC_E_CELL_Over_Temperature 10;
BA_ "GenSigSendType" SG_ 539 SAC_E_CELL_Over_Temperature 1;
BA_ "GenSigCycleTime" SG_ 539 SAC_E_CSC_Timeout 10;
BA_ "GenSigSendType" SG_ 539 SAC_E_CSC_Timeout 1;
BA_ "GenSigCycleTime" SG_ 539 SAC_E_CSC_Internal 10;
BA_ "GenSigSendType" SG_ 539 SAC_E_CSC_Internal 1;
BA_ "GenSigCycleTime" SG_ 539 SAC_E_BAT_Over_Voltage 10;
BA_ "GenSigSendType" SG_ 539 SAC_E_BAT_Over_Voltage 1;
BA_ "GenSigCycleTime" SG_ 539 SAC_E_PMB_Over_Current_discharg 10;
BA_ "GenSigSendType" SG_ 539 SAC_E_PMB_Over_Current_discharg 1;
BA_ "GenSigCycleTime" SG_ 539 SAC_E_PMB_Over_Current_charge 10;
BA_ "GenSigSendType" SG_ 539 SAC_E_PMB_Over_Current_charge 1;
BA_ "GenSigCycleTime" SG_ 539 SAC_E_PMB_Over_Temperature_Shun 10;
BA_ "GenSigSendType" SG_ 539 SAC_E_PMB_Over_Temperature_Shun 1;
BA_ "GenSigCycleTime" SG_ 539 SAC_E_MSW_AGE 10;
BA_ "GenSigSendType" SG_ 539 SAC_E_MSW_AGE 1;
BA_ "GenSigCycleTime" SG_ 539 SAC_E_PMB_Internal 10;
BA_ "GenSigSendType" SG_ 539 SAC_E_PMB_Internal 1;
BA_ "GenSigCycleTime" SG_ 539 SAC_E_SSV_WD 10;
BA_ "GenSigSendType" SG_ 539 SAC_E_SSV_WD 1;
BA_ "GenSigCycleTime" SG_ 539 SAC_E_SSV_Supply_Voltage 10;
BA_ "GenSigSendType" SG_ 539 SAC_E_SSV_Supply_Voltage 1;
BA_ "GenSigCycleTime" SG_ 539 SAC_E_FLASH_Monitor 10;
BA_ "GenSigSendType" SG_ 539 SAC_E_FLASH_Monitor 1;
BA_ "GenSigCycleTime" SG_ 539 SAC_E_PMB_Emergency_short_sup 10;
BA_ "GenSigSendType" SG_ 539 SAC_E_PMB_Emergency_short_sup 1;
BA_ "GenSigCycleTime" SG_ 539 SAC_E_SSV_Warning 10;
BA_ "GenSigSendType" SG_ 539 SAC_E_SSV_Warning 1;
BA_ "GenSigCycleTime" SG_ 539 SAC_E_SSV_Emergency 10;
BA_ "GenSigSendType" SG_ 539 SAC_E_SSV_Emergency 1;
BA_ "GenSigCycleTime" SG_ 539 SAC_E_Ref_Voltage 10;
BA_ "GenSigSendType" SG_ 539 SAC_E_Ref_Voltage 1;
BA_ "GenSigCycleTime" SG_ 539 SAC_E_Supply_Voltage 10;
BA_ "GenSigSendType" SG_ 539 SAC_E_Supply_Voltage 1;
BA_ "GenSigCycleTime" SG_ 539 SAC_E_BCC_communication 10;
BA_ "GenSigSendType" SG_ 539 SAC_E_BCC_communication 1;
BA_ "GenSigCycleTime" SG_ 539 SAC_E_CSC_Emergency_short_sup 10;
BA_ "GenSigSendType" SG_ 539 SAC_E_CSC_Emergency_short_sup 1;
BA_ "GenSigCycleTime" SG_ 539 SAC_E_SSV_CONFIG_HARD 10;
BA_ "GenSigSendType" SG_ 539 SAC_E_SSV_CONFIG_HARD 1;
BA_ "GenSigCycleTime" SG_ 539 SAC_E_PMB_Warning 10;
BA_ "GenSigSendType" SG_ 539 SAC_E_PMB_Warning 1;
BA_ "GenSigCycleTime" SG_ 539 SAC_E_STACK_Monitor 10;
BA_ "GenSigSendType" SG_ 539 SAC_E_STACK_Monitor 1;
BA_ "GenSigCycleTime" SG_ 539 SAC_E_RAM_Monitor 10;
BA_ "GenSigSendType" SG_ 539 SAC_E_RAM_Monitor 1;
BA_ "GenSigCycleTime" SG_ 539 SAC_E_ROM_Monitor 10;
BA_ "GenSigSendType" SG_ 539 SAC_E_ROM_Monitor 1;
BA_ "GenSigCycleTime" SG_ 539 SAC_E_Reset_Monitor 10;
BA_ "GenSigSendType" SG_ 539 SAC_E_Reset_Monitor 1;
BA_ "GenSigCycleTime" SG_ 539 SAC_E_CPU_Test 10;
BA_ "GenSigSendType" SG_ 539 SAC_E_CPU_Test 1;
BA_ "GenSigCycleTime" SG_ 539 SAC_E_WD 10;
BA_ "GenSigSendType" SG_ 539 SAC_E_WD 1;
BA_ "GenSigCycleTime" SG_ 539 SAC_E_Trac_Voltage 10;
BA_ "GenSigSendType" SG_ 539 SAC_E_Trac_Voltage 1;
BA_ "GenSigCycleTime" SG_ 539 SAC_E_HV_meas 10;
BA_ "GenSigSendType" SG_ 539 SAC_E_HV_meas 1;
BA_ "GenSigCycleTime" SG_ 539 SAC_E_Lifedata 10;
BA_ "GenSigSendType" SG_ 539 SAC_E_Lifedata 1;
BA_ "GenSigCycleTime" SG_ 539 SAC_E_NVRAM 10;
BA_ "GenSigSendType" SG_ 539 SAC_E_NVRAM 1;
BA_ "GenSigCycleTime" SG_ 539 SAC_E_PMB_Limits 10;
BA_ "GenSigSendType" SG_ 539 SAC_E_PMB_Limits 1;
BA_ "GenSigCycleTime" SG_ 539 SAC_E_PCB_Temperature 10;
BA_ "GenSigSendType" SG_ 539 SAC_E_PCB_Temperature 1;
BA_ "GenSigCycleTime" SG_ 539 SAC_E_Iso_measurement 10;
BA_ "GenSigSendType" SG_ 539 SAC_E_Iso_measurement 1;
BA_ "GenSigCycleTime" SG_ 539 SAC_E_SSV_Interop 10;
BA_ "GenSigSendType" SG_ 539 SAC_E_SSV_Interop 1;
BA_ "GenSigCycleTime" SG_ 539 SAC_E_PMB_Timeout 10;
BA_ "GenSigSendType" SG_ 539 SAC_E_PMB_Timeout 1;
BA_ "GenSigCycleTime" SG_ 539 SAC_E_Interlock_missing 10;
BA_ "GenSigSendType" SG_ 539 SAC_E_Interlock_missing 1;
BA_ "GenSigCycleTime" SG_ 539 SAC_E_PMB_Emergency 10;
BA_ "GenSigSendType" SG_ 539 SAC_E_PMB_Emergency 1;
BA_ "GenSigCycleTime" SG_ 539 SAC_E_CSC_Emergency 10;
BA_ "GenSigSendType" SG_ 539 SAC_E_CSC_Emergency 1;
BA_ "GenSigCycleTime" SG_ 539 SAC_E_FLOW_CTR 10;
BA_ "GenSigSendType" SG_ 539 SAC_E_FLOW_CTR 1;
BA_ "GenSigCycleTime" SG_ 539 SAC_E_ACC_Emergency 10;
BA_ "GenSigSendType" SG_ 539 SAC_E_ACC_Emergency 1;
BA_ "GenSigCycleTime" SG_ 539 SAC_E_Iso_resistance 10;
BA_ "GenSigSendType" SG_ 539 SAC_E_Iso_resistance 1;
BA_ "GenSigCycleTime" SG_ 539 SAC_E_SSV_Timeout 10;
BA_ "GenSigSendType" SG_ 539 SAC_E_SSV_Timeout 1;
BA_ "GenSigCycleTime" SG_ 539 SAC_E_CSC_Warning 10;
BA_ "GenSigSendType" SG_ 539 SAC_E_CSC_Warning 1;
BA_ "GenSigCycleTime" SG_ 539 SAC_E_CELL_Under_Voltage 10;
BA_ "GenSigSendType" SG_ 539 SAC_E_CELL_Under_Voltage 1;
BA_ "GenSigCycleTime" SG_ 539 SAC_E_CELL_Over_Voltage 10;
BA_ "GenSigSendType" SG_ 539 SAC_E_CELL_Over_Voltage 1;
BA_ "GenSigCycleTime" SG_ 309 BCC_T_Batt_06 100;
BA_ "GenSigSendType" SG_ 309 BCC_T_Batt_06 1;
BA_ "GenSigStartValue" SG_ 309 BCC_T_Batt_06 2500;
BA_ "GenSigCycleTime" SG_ 309 BCC_T_Batt_05 100;
BA_ "GenSigSendType" SG_ 309 BCC_T_Batt_05 1;
BA_ "GenSigStartValue" SG_ 309 BCC_T_Batt_05 2500;
BA_ "GenSigCycleTime" SG_ 308 BCC_T_Batt_04 100;
BA_ "GenSigSendType" SG_ 308 BCC_T_Batt_04 1;
BA_ "GenSigStartValue" SG_ 308 BCC_T_Batt_04 2500;
BA_ "GenSigCycleTime" SG_ 308 BCC_T_Batt_03 100;
BA_ "GenSigSendType" SG_ 308 BCC_T_Batt_03 1;
BA_ "GenSigStartValue" SG_ 308 BCC_T_Batt_03 2500;
BA_ "GenSigCycleTime" SG_ 307 BCC_T_Batt_02 100;
BA_ "GenSigSendType" SG_ 307 BCC_T_Batt_02 1;
BA_ "GenSigStartValue" SG_ 307 BCC_T_Batt_02 2500;
BA_ "GenSigCycleTime" SG_ 307 BCC_T_Batt_01 100;
BA_ "GenSigStartValue" SG_ 307 BCC_T_Batt_01 2500;
BA_ "GenSigSendType" SG_ 307 BCC_T_Batt_01 1;
BA_ "GenSigCycleTime" SG_ 16 BIW_v_Dbg_TxVariable04 100;
BA_ "GenSigSendType" SG_ 16 BIW_v_Dbg_TxVariable04 1;
BA_ "GenSigCycleTime" SG_ 16 BIW_v_Dbg_TxVariable03 100;
BA_ "GenSigSendType" SG_ 16 BIW_v_Dbg_TxVariable03 1;
BA_ "GenSigCycleTime" SG_ 16 BIW_v_Dbg_TxVariable02 100;
BA_ "GenSigSendType" SG_ 16 BIW_v_Dbg_TxVariable02 1;
BA_ "GenSigCycleTime" SG_ 16 BIW_v_Dbg_TxVariable01 100;
BA_ "GenSigSendType" SG_ 16 BIW_v_Dbg_TxVariable01 1;
BA_ "GenSigCycleTime" SG_ 16 BULIM_Batt_Umin_Deviation_Error 100;
BA_ "GenSigSendType" SG_ 16 BULIM_Batt_Umin_Deviation_Error 1;
BA_ "GenSigCycleTime" SG_ 16 BULIM_Batt_Umax_Deviation_Error 100;
BA_ "GenSigSendType" SG_ 16 BULIM_Batt_Umax_Deviation_Error 1;
BA_ "GenSigCycleTime" SG_ 16 BSOC_SOC_UltraLow_Error 100;
BA_ "GenSigSendType" SG_ 16 BSOC_SOC_UltraLow_Error 1;
BA_ "GenSigCycleTime" SG_ 16 BSOC_SOC_UltraHigh_Error 100;
BA_ "GenSigSendType" SG_ 16 BSOC_SOC_UltraHigh_Error 1;
BA_ "GenSigCycleTime" SG_ 16 BSOC_SOC_Low_Error 100;
BA_ "GenSigSendType" SG_ 16 BSOC_SOC_Low_Error 1;
BA_ "GenSigCycleTime" SG_ 16 BSOC_SOC_High_Error 100;
BA_ "GenSigSendType" SG_ 16 BSOC_SOC_High_Error 1;
BA_ "GenSigCycleTime" SG_ 16 BSOC_OCV_Cell_Diff_High_Error 100;
BA_ "GenSigSendType" SG_ 16 BSOC_OCV_Cell_Diff_High_Error 1;
BA_ "GenSigCycleTime" SG_ 16 BILIM_I_DisChrg_Error 100;
BA_ "GenSigSendType" SG_ 16 BILIM_I_DisChrg_Error 1;
BA_ "GenSigCycleTime" SG_ 16 BILIM_I_Chrg_Error 100;
BA_ "GenSigSendType" SG_ 16 BILIM_I_Chrg_Error 1;
BA_ "GenSigCycleTime" SG_ 16 BCOOL_Temp_UltraHigh_Error 100;
BA_ "GenSigSendType" SG_ 16 BCOOL_Temp_UltraHigh_Error 1;
BA_ "GenSigCycleTime" SG_ 16 BCOOL_Temp_High_Error 100;
BA_ "GenSigSendType" SG_ 16 BCOOL_Temp_High_Error 1;
BA_ "GenSigCycleTime" SG_ 16 BBALU_Cell_Error 100;
BA_ "GenSigSendType" SG_ 16 BBALU_Cell_Error 1;
BA_ "GenSigCycleTime" SG_ 547 SAC_S_RTC_LOW_VOLT 10;
BA_ "GenSigSendType" SG_ 547 SAC_S_RTC_LOW_VOLT 1;
BA_ "GenSigCycleTime" SG_ 547 SAC_S_SOFTWARE_RESET_PERFORMED 10;
BA_ "GenSigSendType" SG_ 547 SAC_S_SOFTWARE_RESET_PERFORMED 1;
BA_ "GenSigCycleTime" SG_ 547 SAC_S_ISO_GND_WARNING 10;
BA_ "GenSigSendType" SG_ 547 SAC_S_ISO_GND_WARNING 1;
BA_ "GenSigCycleTime" SG_ 547 SAC_S_DISCHARGE_COMPLETED 10;
BA_ "GenSigSendType" SG_ 547 SAC_S_DISCHARGE_COMPLETED 1;
BA_ "GenSigCycleTime" SG_ 547 SAC_S_DISCHARGE 10;
BA_ "GenSigSendType" SG_ 547 SAC_S_DISCHARGE 1;
BA_ "GenSigCycleTime" SG_ 547 SAC_S_PMB_CAN_ACTIVE 10;
BA_ "GenSigSendType" SG_ 547 SAC_S_PMB_CAN_ACTIVE 1;
BA_ "GenSigCycleTime" SG_ 547 SAC_S_CSC_CAN_ACTIVE 10;
BA_ "GenSigSendType" SG_ 547 SAC_S_CSC_CAN_ACTIVE 1;
BA_ "GenSigCycleTime" SG_ 547 SAC_S_CAN_WAKEUP 10;
BA_ "GenSigSendType" SG_ 547 SAC_S_CAN_WAKEUP 1;
BA_ "GenSigCycleTime" SG_ 547 SAC_S_CLOSE_NOT_POSSIBLE_WEAK 10;
BA_ "GenSigSendType" SG_ 547 SAC_S_CLOSE_NOT_POSSIBLE_WEAK 1;
BA_ "GenSigCycleTime" SG_ 547 SAC_S_SC_MSW_3_CLOSE 10;
BA_ "GenSigSendType" SG_ 547 SAC_S_SC_MSW_3_CLOSE 1;
BA_ "GenSigCycleTime" SG_ 547 SAC_S_ISO_TEST_ACTIVE 10;
BA_ "GenSigSendType" SG_ 547 SAC_S_ISO_TEST_ACTIVE 1;
BA_ "GenSigCycleTime" SG_ 547 SAC_S_SC_PMB_EN 10;
BA_ "GenSigSendType" SG_ 547 SAC_S_SC_PMB_EN 1;
BA_ "GenSigCycleTime" SG_ 547 SAC_S_SC_CSC_EN 10;
BA_ "GenSigSendType" SG_ 547 SAC_S_SC_CSC_EN 1;
BA_ "GenSigCycleTime" SG_ 547 SAC_S_HV_EN 10;
BA_ "GenSigSendType" SG_ 547 SAC_S_HV_EN 1;
BA_ "GenSigCycleTime" SG_ 547 SAC_S_MEAS_CAN_WARN 10;
BA_ "GenSigSendType" SG_ 547 SAC_S_MEAS_CAN_WARN 1;
BA_ "GenSigCycleTime" SG_ 547 SAC_S_CSC_RESET 10;
BA_ "GenSigSendType" SG_ 547 SAC_S_CSC_RESET 1;
BA_ "GenSigCycleTime" SG_ 547 SAC_S_CSC_SYNC 10;
BA_ "GenSigSendType" SG_ 547 SAC_S_CSC_SYNC 1;
BA_ "GenSigCycleTime" SG_ 547 SAC_S_PMB_RESET 10;
BA_ "GenSigSendType" SG_ 547 SAC_S_PMB_RESET 1;
BA_ "GenSigCycleTime" SG_ 547 SAC_S_PMB_SYNC 10;
BA_ "GenSigSendType" SG_ 547 SAC_S_PMB_SYNC 1;
BA_ "GenSigCycleTime" SG_ 547 SAC_S_SC_KL30c_EN 10;
BA_ "GenSigSendType" SG_ 547 SAC_S_SC_KL30c_EN 1;
BA_ "GenSigCycleTime" SG_ 547 SAC_S_RTC_WAKEUP_DETECTED 10;
BA_ "GenSigSendType" SG_ 547 SAC_S_RTC_WAKEUP_DETECTED 1;
BA_ "GenSigCycleTime" SG_ 547 SAC_S_RTC_WAKEUP_DELAY_SET 10;
BA_ "GenSigSendType" SG_ 547 SAC_S_RTC_WAKEUP_DELAY_SET 1;
BA_ "GenSigCycleTime" SG_ 547 SAC_S_RTC_READY 10;
BA_ "GenSigSendType" SG_ 547 SAC_S_RTC_READY 1;
BA_ "GenSigCycleTime" SG_ 547 SAC_S_ISO_VALUE_VALID 10;
BA_ "GenSigSendType" SG_ 547 SAC_S_ISO_VALUE_VALID 1;
BA_ "GenSigCycleTime" SG_ 547 SAC_S_ISO_EN 10;
BA_ "GenSigSendType" SG_ 547 SAC_S_ISO_EN 1;
BA_ "GenSigCycleTime" SG_ 547 SAC_S_PRECH_COMPLETED 10;
BA_ "GenSigSendType" SG_ 547 SAC_S_PRECH_COMPLETED 1;
BA_ "GenSigCycleTime" SG_ 547 SAC_S_PREC_ACTIVE 10;
BA_ "GenSigSendType" SG_ 547 SAC_S_PREC_ACTIVE 1;
BA_ "GenSigCycleTime" SG_ 547 SAC_S_COOLING 10;
BA_ "GenSigSendType" SG_ 547 SAC_S_COOLING 1;
BA_ "GenSigCycleTime" SG_ 547 SAC_S_STUCKTEST_READY 10;
BA_ "GenSigSendType" SG_ 547 SAC_S_STUCKTEST_READY 1;
BA_ "GenSigCycleTime" SG_ 547 SAC_S_SKT_CONDITIONS 10;
BA_ "GenSigSendType" SG_ 547 SAC_S_SKT_CONDITIONS 1;
BA_ "GenSigCycleTime" SG_ 547 SAC_S_MSW_SUPPLY 10;
BA_ "GenSigSendType" SG_ 547 SAC_S_MSW_SUPPLY 1;
BA_ "GenSigCycleTime" SG_ 547 SAC_S_ISO_RES_WARNING 10;
BA_ "GenSigSendType" SG_ 547 SAC_S_ISO_RES_WARNING 1;
BA_ "GenSigCycleTime" SG_ 547 SAC_S_SC_MSW_PLUS_CLOSE 10;
BA_ "GenSigSendType" SG_ 547 SAC_S_SC_MSW_PLUS_CLOSE 1;
BA_ "GenSigCycleTime" SG_ 547 SAC_S_SC_MSW_MINUS_CLOSE 10;
BA_ "GenSigSendType" SG_ 547 SAC_S_SC_MSW_MINUS_CLOSE 1;
BA_ "GenSigCycleTime" SG_ 547 SAC_S_MONITORING 10;
BA_ "GenSigSendType" SG_ 547 SAC_S_MONITORING 1;
BA_ "GenSigCycleTime" SG_ 547 SAC_S_SYS_ENABLE 10;
BA_ "GenSigSendType" SG_ 547 SAC_S_SYS_ENABLE 1;
BA_ "GenSigCycleTime" SG_ 547 SAC_S_START_UP_TEST 10;
BA_ "GenSigSendType" SG_ 547 SAC_S_START_UP_TEST 1;
BA_ "GenSigCycleTime" SG_ 547 SAC_S_EMERGENCY_OPEN 10;
BA_ "GenSigSendType" SG_ 547 SAC_S_EMERGENCY_OPEN 1;
BA_ "GenSigCycleTime" SG_ 547 SAC_S_GENERAL_ERROR 10;
BA_ "GenSigSendType" SG_ 547 SAC_S_GENERAL_ERROR 1;
BA_ "GenSigCycleTime" SG_ 540 SAC_Version_DS_CRC 100;
BA_ "GenSigSendType" SG_ 540 SAC_Version_DS_CRC 1;
BA_ "GenSigCycleTime" SG_ 540 SAC_Version_Release 100;
BA_ "GenSigSendType" SG_ 540 SAC_Version_Release 1;
BA_ "GenSigCycleTime" SG_ 540 SAC_Version_Minor 100;
BA_ "GenSigSendType" SG_ 540 SAC_Version_Minor 1;
BA_ "GenSigCycleTime" SG_ 540 SAC_Version_Major 100;
BA_ "GenSigSendType" SG_ 540 SAC_Version_Major 1;
BA_ "GenSigCycleTime" SG_ 1795 BMC_BSW_DS_CRC 1000;
BA_ "GenSigSendType" SG_ 1795 BMC_BSW_DS_CRC 1;
BA_ "GenSigCycleTime" SG_ 1795 BMC_BSW_Version_Release 1000;
BA_ "GenSigSendType" SG_ 1795 BMC_BSW_Version_Release 1;
BA_ "GenSigCycleTime" SG_ 1795 BMC_BSW_Version_Minor 1000;
BA_ "GenSigSendType" SG_ 1795 BMC_BSW_Version_Minor 1;
BA_ "GenSigCycleTime" SG_ 1795 BMC_BSW_Version_Major 1000;
BA_ "GenSigSendType" SG_ 1795 BMC_BSW_Version_Major 1;
BA_ "GenSigCycleTime" SG_ 1793 Iso_Res_01 100;
BA_ "GenSigSendType" SG_ 1793 Iso_Res_01 1;
BA_ "GenSigCycleTime" SG_ 1793 BMC_KL30C_Voltage 100;
BA_ "GenSigStartValue" SG_ 1793 BMC_KL30C_Voltage 255;
BA_ "GenSigSendType" SG_ 1793 BMC_KL30C_Voltage 1;
BA_ "GenSigCycleTime" SG_ 1793 BMC_KL30_Voltage 100;
BA_ "GenSigStartValue" SG_ 1793 BMC_KL30_Voltage 255;
BA_ "GenSigSendType" SG_ 1793 BMC_KL30_Voltage 1;
BA_ "GenSigCycleTime" SG_ 1793 Iso_Test_Active 100;
BA_ "GenSigSendType" SG_ 1793 Iso_Test_Active 1;
BA_ "GenSigCycleTime" SG_ 1793 Iso_Meas_res 100;
BA_ "GenSigSendType" SG_ 1793 Iso_Meas_res 1;
BA_ "GenSigCycleTime" SG_ 1793 Iso_Value_Valid 100;
BA_ "GenSigSendType" SG_ 1793 Iso_Value_Valid 1;
BA_ "GenSigCycleTime" SG_ 1793 Iso_Res_Warning 100;
BA_ "GenSigSendType" SG_ 1793 Iso_Res_Warning 1;
BA_ "GenSigCycleTime" SG_ 1793 Iso_Res_Error 100;
BA_ "GenSigSendType" SG_ 1793 Iso_Res_Error 1;
BA_ "GenSigCycleTime" SG_ 1793 Iso_Res 100;
BA_ "GenSigSendType" SG_ 1793 Iso_Res 1;
BA_ "GenSigCycleTime" SG_ 1793 Iso_Meas_Error 100;
BA_ "GenSigSendType" SG_ 1793 Iso_Meas_Error 1;
BA_ "GenSigCycleTime" SG_ 609 BCC_Version_Dummy 100;
BA_ "GenSigSendType" SG_ 609 BCC_Version_Dummy 1;
BA_ "GenSigCycleTime" SG_ 609 AV_BCC_Project_Id 100;
BA_ "GenSigSendType" SG_ 609 AV_BCC_Project_Id 1;
BA_ "GenSigCycleTime" SG_ 609 AV_BCC_HW_Id 100;
BA_ "GenSigSendType" SG_ 609 AV_BCC_HW_Id 1;
BA_ "GenSigCycleTime" SG_ 609 AV_BCC_Version 100;
BA_ "GenSigSendType" SG_ 609 AV_BCC_Version 1;
BA_ "GenSigCycleTime" SG_ 661 SW_Wakeup_by_RTC 100;
BA_ "GenSigSendType" SG_ 661 SW_Wakeup_by_RTC 1;
BA_ "GenSigCycleTime" SG_ 661 SW_OP_Mode 100;
BA_ "GenSigSendType" SG_ 661 SW_OP_Mode 1;
BA_ "GenSigCycleTime" SG_ 279 BCC_Time_Sw_Open 100;
BA_ "GenSigSendType" SG_ 279 BCC_Time_Sw_Open 1;
BA_ "GenSigCycleTime" SG_ 276 BCC_Number_of_Temperatures 100;
BA_ "GenSigSendType" SG_ 276 BCC_Number_of_Temperatures 1;
BA_ "GenSigCycleTime" SG_ 276 BCC_Number_of_Cells 100;
BA_ "GenSigSendType" SG_ 276 BCC_Number_of_Cells 1;
BA_ "GenSigCycleTime" SG_ 276 BCC_Reset_U_Limit_Req 100;
BA_ "GenSigSendType" SG_ 276 BCC_Reset_U_Limit_Req 1;
BA_ "GenSigCycleTime" SG_ 276 BCC_Recalibrate_Mode 100;
BA_ "GenSigSendType" SG_ 276 BCC_Recalibrate_Mode 1;
BA_ "GenSigCycleTime" SG_ 276 BCC_NV_Data_SNA_Mode 100;
BA_ "GenSigSendType" SG_ 276 BCC_NV_Data_SNA_Mode 1;
BA_ "GenSigCycleTime" SG_ 276 BCC_NoCurr_Req 100;
BA_ "GenSigSendType" SG_ 276 BCC_NoCurr_Req 1;
BA_ "GenSigCycleTime" SG_ 276 BCC_KL50 100;
BA_ "GenSigSendType" SG_ 276 BCC_KL50 1;
BA_ "GenSigCycleTime" SG_ 276 BCC_KL15 100;
BA_ "GenSigSendType" SG_ 276 BCC_KL15 1;
BA_ "GenSigCycleTime" SG_ 276 BCC_EM_Volt_Derate_Mode 100;
BA_ "GenSigSendType" SG_ 276 BCC_EM_Volt_Derate_Mode 1;
BA_ "GenSigCycleTime" SG_ 276 BCC_EEPROM_Mode 100;
BA_ "GenSigSendType" SG_ 276 BCC_EEPROM_Mode 1;
BA_ "GenSigCycleTime" SG_ 276 BCC_Cyclic_Mode 100;
BA_ "GenSigSendType" SG_ 276 BCC_Cyclic_Mode 1;
BA_ "GenSigCycleTime" SG_ 276 BCC_Continuous_Mode 100;
BA_ "GenSigSendType" SG_ 276 BCC_Continuous_Mode 1;
BA_ "GenSigCycleTime" SG_ 299 BCC_Diag_Capa_As_1 100;
BA_ "GenSigStartValue" SG_ 299 BCC_Diag_Capa_As_1 23400;
BA_ "GenSigSendType" SG_ 299 BCC_Diag_Capa_As_1 1;
BA_ "GenSigCycleTime" SG_ 299 BCC_Balancing_U_Target 100;
BA_ "GenSigSendType" SG_ 299 BCC_Balancing_U_Target 1;
BA_ "GenSigCycleTime" SG_ 299 BCC_Diag_OCV_Mode 100;
BA_ "GenSigSendType" SG_ 299 BCC_Diag_OCV_Mode 1;
BA_ "GenSigCycleTime" SG_ 299 BCC_Diag_Capa_Mode 100;
BA_ "GenSigSendType" SG_ 299 BCC_Diag_Capa_Mode 1;
BA_ "GenSigCycleTime" SG_ 299 BCC_Balancing_Mode 100;
BA_ "GenSigSendType" SG_ 299 BCC_Balancing_Mode 1;
BA_ "GenSigCycleTime" SG_ 277 BCC_OBL_HVDC_Voltage 100;
BA_ "GenSigSendType" SG_ 277 BCC_OBL_HVDC_Voltage 1;
BA_ "GenSigCycleTime" SG_ 277 BCC_OBL_HVDC_Current 100;
BA_ "GenSigSendType" SG_ 277 BCC_OBL_HVDC_Current 1;
BA_ "GenSigCycleTime" SG_ 277 BCC_OBL_HVDC_Voltage_SNA_Mode 100;
BA_ "GenSigSendType" SG_ 277 BCC_OBL_HVDC_Voltage_SNA_Mode 1;
BA_ "GenSigCycleTime" SG_ 277 BCC_OBL_HVDC_Current_SNA_Mode 100;
BA_ "GenSigSendType" SG_ 277 BCC_OBL_HVDC_Current_SNA_Mode 1;
BA_ "GenSigCycleTime" SG_ 277 BCC_OBL_BMS_Wakeup_State 100;
BA_ "GenSigSendType" SG_ 277 BCC_OBL_BMS_Wakeup_State 1;
BA_ "GenSigCycleTime" SG_ 277 BCC_OBL_BMS_Wakeup_SNA_Mode 100;
BA_ "GenSigSendType" SG_ 277 BCC_OBL_BMS_Wakeup_SNA_Mode 1;
BA_ "GenSigCycleTime" SG_ 278 BCC_RTC 100;
BA_ "GenSigSendType" SG_ 278 BCC_RTC 1;
BA_ "GenSigCycleTime" SG_ 278 BCC_RTC_SNA_Mode 100;
BA_ "GenSigSendType" SG_ 278 BCC_RTC_SNA_Mode 1;
BA_ "GenSigCycleTime" SG_ 282 BCC_Ibatt_Substitute_Value 10;
BA_ "GenSigStartValue" SG_ 282 BCC_Ibatt_Substitute_Value 8192;
BA_ "GenSigSendType" SG_ 282 BCC_Ibatt_Substitute_Value 1;
BA_ "GenSigCycleTime" SG_ 282 BCC_Ibatt_Substitute_Mode 10;
BA_ "GenSigSendType" SG_ 282 BCC_Ibatt_Substitute_Mode 1;
BA_ "GenSigCycleTime" SG_ 282 BCC_I_Batt_SNA_Mode 10;
BA_ "GenSigSendType" SG_ 282 BCC_I_Batt_SNA_Mode 1;
BA_ "GenSigCycleTime" SG_ 282 BCC_I_Batt_Filter_SNA_Mode 10;
BA_ "GenSigSendType" SG_ 282 BCC_I_Batt_Filter_SNA_Mode 1;
BA_ "GenSigCycleTime" SG_ 306 BCC_CoolantInletTemp 100;
BA_ "GenSigSendType" SG_ 306 BCC_CoolantInletTemp 1;
BA_ "GenSigCycleTime" SG_ 281 BCC_I_Batt_Filtered 10;
BA_ "GenSigSendType" SG_ 281 BCC_I_Batt_Filtered 1;
BA_ "GenSigCycleTime" SG_ 281 BCC_I_Batt 10;
BA_ "GenSigSendType" SG_ 281 BCC_I_Batt 1;
BA_ "GenSigCycleTime" SG_ 280 BCC_Ubatt_Substitute_Value 100;
BA_ "GenSigSendType" SG_ 280 BCC_Ubatt_Substitute_Value 1;
BA_ "GenSigCycleTime" SG_ 280 BCC_U_Batt 100;
BA_ "GenSigSendType" SG_ 280 BCC_U_Batt 1;
BA_ "GenSigCycleTime" SG_ 280 BCC_Ubatt_Substitute_Mode 100;
BA_ "GenSigSendType" SG_ 280 BCC_Ubatt_Substitute_Mode 1;
BA_ "GenSigCycleTime" SG_ 280 BCC_U_Batt_SNA_Mode 100;
BA_ "GenSigSendType" SG_ 280 BCC_U_Batt_SNA_Mode 1;
BA_ "GenSigCycleTime" SG_ 305 BCC_T_Cool 100;
BA_ "GenSigSendType" SG_ 305 BCC_T_Cool 1;
BA_ "GenSigCycleTime" SG_ 305 BCC_T_Amb 100;
BA_ "GenSigStartValue" SG_ 305 BCC_T_Amb 80;
BA_ "GenSigSendType" SG_ 305 BCC_T_Amb 1;
BA_ "GenSigCycleTime" SG_ 305 BCC_T_Cool_SNA_Mode 100;
BA_ "GenSigSendType" SG_ 305 BCC_T_Cool_SNA_Mode 1;
BA_ "GenSigCycleTime" SG_ 385 BCC_SwitchingValveStage_State 100;
BA_ "GenSigSendType" SG_ 385 BCC_SwitchingValveStage_State 1;
BA_ "GenSigCycleTime" SG_ 385 BCC_FanStage_State 100;
BA_ "GenSigSendType" SG_ 385 BCC_FanStage_State 1;
BA_ "GenSigCycleTime" SG_ 385 BCC_SwitchingValve_Mode 100;
BA_ "GenSigSendType" SG_ 385 BCC_SwitchingValve_Mode 1;
BA_ "GenSigCycleTime" SG_ 385 BCC_SwitchingValve_Cmd 100;
BA_ "GenSigSendType" SG_ 385 BCC_SwitchingValve_Cmd 1;
BA_ "GenSigCycleTime" SG_ 385 BCC_FanReq_Mode 100;
BA_ "GenSigSendType" SG_ 385 BCC_FanReq_Mode 1;
BA_ "GenSigCycleTime" SG_ 385 BCC_FanRelay_Mode 100;
BA_ "GenSigSendType" SG_ 385 BCC_FanRelay_Mode 1;
BA_ "GenSigCycleTime" SG_ 385 BCC_FanRelay_Cmd 100;
BA_ "GenSigSendType" SG_ 385 BCC_FanRelay_Cmd 1;
BA_ "GenSigCycleTime" SG_ 384 BCC_CoolingComp_State 100;
BA_ "GenSigStartValue" SG_ 384 BCC_CoolingComp_State 2;
BA_ "GenSigSendType" SG_ 384 BCC_CoolingComp_State 1;
BA_ "GenSigCycleTime" SG_ 384 BCC_CoolingCircuit_State 100;
BA_ "GenSigStartValue" SG_ 384 BCC_CoolingCircuit_State 2;
BA_ "GenSigSendType" SG_ 384 BCC_CoolingCircuit_State 1;
BA_ "GenSigCycleTime" SG_ 384 BCC_CoolantPump_State 100;
BA_ "GenSigSendType" SG_ 384 BCC_CoolantPump_State 1;
BA_ "GenSigCycleTime" SG_ 384 BCC_CoolantPump_Cmd 100;
BA_ "GenSigSendType" SG_ 384 BCC_CoolantPump_Cmd 1;
BA_ "GenSigCycleTime" SG_ 384 BCC_ChillerValveStage_State 100;
BA_ "GenSigSendType" SG_ 384 BCC_ChillerValveStage_State 1;
BA_ "GenSigCycleTime" SG_ 384 BCC_CoolCirc_Actv_Mode 100;
BA_ "GenSigSendType" SG_ 384 BCC_CoolCirc_Actv_Mode 1;
BA_ "GenSigCycleTime" SG_ 384 BCC_CoolantPump_Mode 100;
BA_ "GenSigSendType" SG_ 384 BCC_CoolantPump_Mode 1;
BA_ "GenSigCycleTime" SG_ 384 BCC_ChillerValve_Mode 100;
BA_ "GenSigSendType" SG_ 384 BCC_ChillerValve_Mode 1;
BA_ "GenSigCycleTime" SG_ 384 BCC_ChillerValve_En_Mode 100;
BA_ "GenSigSendType" SG_ 384 BCC_ChillerValve_En_Mode 1;
BA_ "GenSigCycleTime" SG_ 384 BCC_ChillerValve_Cmd 100;
BA_ "GenSigSendType" SG_ 384 BCC_ChillerValve_Cmd 1;
BA_ "GenSigCycleTime" SG_ 384 BCC_BMS_CoolVlv_Mode 100;
BA_ "GenSigSendType" SG_ 384 BCC_BMS_CoolVlv_Mode 1;
BA_ "GenSigCycleTime" SG_ 384 BCC_AC_Cool_Mode 100;
BA_ "GenSigSendType" SG_ 384 BCC_AC_Cool_Mode 1;
BA_ "GenSigCycleTime" SG_ 365 BCC_U_Cell_120 10;
BA_ "GenSigSendType" SG_ 365 BCC_U_Cell_120 1;
BA_ "GenSigStartValue" SG_ 365 BCC_U_Cell_120 3700;
BA_ "GenSigCycleTime" SG_ 365 BCC_U_Cell_119 10;
BA_ "GenSigSendType" SG_ 365 BCC_U_Cell_119 1;
BA_ "GenSigStartValue" SG_ 365 BCC_U_Cell_119 3700;
BA_ "GenSigCycleTime" SG_ 365 BCC_U_Cell_118 10;
BA_ "GenSigSendType" SG_ 365 BCC_U_Cell_118 1;
BA_ "GenSigStartValue" SG_ 365 BCC_U_Cell_118 3700;
BA_ "GenSigCycleTime" SG_ 365 BCC_U_Cell_117 10;
BA_ "GenSigSendType" SG_ 365 BCC_U_Cell_117 1;
BA_ "GenSigStartValue" SG_ 365 BCC_U_Cell_117 3700;
BA_ "GenSigCycleTime" SG_ 364 BCC_U_Cell_116 10;
BA_ "GenSigSendType" SG_ 364 BCC_U_Cell_116 1;
BA_ "GenSigStartValue" SG_ 364 BCC_U_Cell_116 3700;
BA_ "GenSigCycleTime" SG_ 364 BCC_U_Cell_115 10;
BA_ "GenSigSendType" SG_ 364 BCC_U_Cell_115 1;
BA_ "GenSigStartValue" SG_ 364 BCC_U_Cell_115 3700;
BA_ "GenSigCycleTime" SG_ 364 BCC_U_Cell_114 10;
BA_ "GenSigSendType" SG_ 364 BCC_U_Cell_114 1;
BA_ "GenSigStartValue" SG_ 364 BCC_U_Cell_114 3700;
BA_ "GenSigCycleTime" SG_ 364 BCC_U_Cell_113 10;
BA_ "GenSigSendType" SG_ 364 BCC_U_Cell_113 1;
BA_ "GenSigStartValue" SG_ 364 BCC_U_Cell_113 3700;
BA_ "GenSigCycleTime" SG_ 363 BCC_U_Cell_112 10;
BA_ "GenSigSendType" SG_ 363 BCC_U_Cell_112 1;
BA_ "GenSigStartValue" SG_ 363 BCC_U_Cell_112 3700;
BA_ "GenSigCycleTime" SG_ 363 BCC_U_Cell_111 10;
BA_ "GenSigSendType" SG_ 363 BCC_U_Cell_111 1;
BA_ "GenSigStartValue" SG_ 363 BCC_U_Cell_111 3700;
BA_ "GenSigCycleTime" SG_ 363 BCC_U_Cell_110 10;
BA_ "GenSigSendType" SG_ 363 BCC_U_Cell_110 1;
BA_ "GenSigStartValue" SG_ 363 BCC_U_Cell_110 3700;
BA_ "GenSigCycleTime" SG_ 363 BCC_U_Cell_109 10;
BA_ "GenSigSendType" SG_ 363 BCC_U_Cell_109 1;
BA_ "GenSigStartValue" SG_ 363 BCC_U_Cell_109 3700;
BA_ "GenSigCycleTime" SG_ 362 BCC_U_Cell_108 10;
BA_ "GenSigSendType" SG_ 362 BCC_U_Cell_108 1;
BA_ "GenSigStartValue" SG_ 362 BCC_U_Cell_108 3700;
BA_ "GenSigCycleTime" SG_ 362 BCC_U_Cell_107 10;
BA_ "GenSigSendType" SG_ 362 BCC_U_Cell_107 1;
BA_ "GenSigStartValue" SG_ 362 BCC_U_Cell_107 3700;
BA_ "GenSigCycleTime" SG_ 362 BCC_U_Cell_106 10;
BA_ "GenSigSendType" SG_ 362 BCC_U_Cell_106 1;
BA_ "GenSigStartValue" SG_ 362 BCC_U_Cell_106 3700;
BA_ "GenSigCycleTime" SG_ 362 BCC_U_Cell_105 10;
BA_ "GenSigSendType" SG_ 362 BCC_U_Cell_105 1;
BA_ "GenSigStartValue" SG_ 362 BCC_U_Cell_105 3700;
BA_ "GenSigCycleTime" SG_ 361 BCC_U_Cell_104 10;
BA_ "GenSigSendType" SG_ 361 BCC_U_Cell_104 1;
BA_ "GenSigStartValue" SG_ 361 BCC_U_Cell_104 3700;
BA_ "GenSigCycleTime" SG_ 361 BCC_U_Cell_103 10;
BA_ "GenSigSendType" SG_ 361 BCC_U_Cell_103 1;
BA_ "GenSigStartValue" SG_ 361 BCC_U_Cell_103 3700;
BA_ "GenSigCycleTime" SG_ 361 BCC_U_Cell_102 10;
BA_ "GenSigSendType" SG_ 361 BCC_U_Cell_102 1;
BA_ "GenSigStartValue" SG_ 361 BCC_U_Cell_102 3700;
BA_ "GenSigCycleTime" SG_ 361 BCC_U_Cell_101 10;
BA_ "GenSigSendType" SG_ 361 BCC_U_Cell_101 1;
BA_ "GenSigStartValue" SG_ 361 BCC_U_Cell_101 3700;
BA_ "GenSigCycleTime" SG_ 360 BCC_U_Cell_100 10;
BA_ "GenSigSendType" SG_ 360 BCC_U_Cell_100 1;
BA_ "GenSigStartValue" SG_ 360 BCC_U_Cell_100 3700;
BA_ "GenSigCycleTime" SG_ 360 BCC_U_Cell_099 10;
BA_ "GenSigSendType" SG_ 360 BCC_U_Cell_099 1;
BA_ "GenSigStartValue" SG_ 360 BCC_U_Cell_099 3700;
BA_ "GenSigCycleTime" SG_ 360 BCC_U_Cell_098 10;
BA_ "GenSigSendType" SG_ 360 BCC_U_Cell_098 1;
BA_ "GenSigStartValue" SG_ 360 BCC_U_Cell_098 3700;
BA_ "GenSigCycleTime" SG_ 360 BCC_U_Cell_097 10;
BA_ "GenSigSendType" SG_ 360 BCC_U_Cell_097 1;
BA_ "GenSigStartValue" SG_ 360 BCC_U_Cell_097 3700;
BA_ "GenSigCycleTime" SG_ 359 BCC_U_Cell_096 10;
BA_ "GenSigSendType" SG_ 359 BCC_U_Cell_096 1;
BA_ "GenSigStartValue" SG_ 359 BCC_U_Cell_096 3700;
BA_ "GenSigCycleTime" SG_ 359 BCC_U_Cell_095 10;
BA_ "GenSigSendType" SG_ 359 BCC_U_Cell_095 1;
BA_ "GenSigStartValue" SG_ 359 BCC_U_Cell_095 3700;
BA_ "GenSigCycleTime" SG_ 359 BCC_U_Cell_094 10;
BA_ "GenSigSendType" SG_ 359 BCC_U_Cell_094 1;
BA_ "GenSigStartValue" SG_ 359 BCC_U_Cell_094 3700;
BA_ "GenSigCycleTime" SG_ 359 BCC_U_Cell_093 10;
BA_ "GenSigSendType" SG_ 359 BCC_U_Cell_093 1;
BA_ "GenSigStartValue" SG_ 359 BCC_U_Cell_093 3700;
BA_ "GenSigCycleTime" SG_ 358 BCC_U_Cell_092 10;
BA_ "GenSigSendType" SG_ 358 BCC_U_Cell_092 1;
BA_ "GenSigStartValue" SG_ 358 BCC_U_Cell_092 3700;
BA_ "GenSigCycleTime" SG_ 358 BCC_U_Cell_091 10;
BA_ "GenSigSendType" SG_ 358 BCC_U_Cell_091 1;
BA_ "GenSigStartValue" SG_ 358 BCC_U_Cell_091 3700;
BA_ "GenSigCycleTime" SG_ 358 BCC_U_Cell_090 10;
BA_ "GenSigSendType" SG_ 358 BCC_U_Cell_090 1;
BA_ "GenSigStartValue" SG_ 358 BCC_U_Cell_090 3700;
BA_ "GenSigCycleTime" SG_ 358 BCC_U_Cell_089 10;
BA_ "GenSigSendType" SG_ 358 BCC_U_Cell_089 1;
BA_ "GenSigStartValue" SG_ 358 BCC_U_Cell_089 3700;
BA_ "GenSigCycleTime" SG_ 357 BCC_U_Cell_088 10;
BA_ "GenSigSendType" SG_ 357 BCC_U_Cell_088 1;
BA_ "GenSigStartValue" SG_ 357 BCC_U_Cell_088 3700;
BA_ "GenSigCycleTime" SG_ 357 BCC_U_Cell_087 10;
BA_ "GenSigSendType" SG_ 357 BCC_U_Cell_087 1;
BA_ "GenSigStartValue" SG_ 357 BCC_U_Cell_087 3700;
BA_ "GenSigCycleTime" SG_ 357 BCC_U_Cell_086 10;
BA_ "GenSigSendType" SG_ 357 BCC_U_Cell_086 1;
BA_ "GenSigStartValue" SG_ 357 BCC_U_Cell_086 3700;
BA_ "GenSigCycleTime" SG_ 357 BCC_U_Cell_085 10;
BA_ "GenSigSendType" SG_ 357 BCC_U_Cell_085 1;
BA_ "GenSigStartValue" SG_ 357 BCC_U_Cell_085 3700;
BA_ "GenSigCycleTime" SG_ 356 BCC_U_Cell_084 10;
BA_ "GenSigSendType" SG_ 356 BCC_U_Cell_084 1;
BA_ "GenSigStartValue" SG_ 356 BCC_U_Cell_084 3700;
BA_ "GenSigCycleTime" SG_ 356 BCC_U_Cell_083 10;
BA_ "GenSigSendType" SG_ 356 BCC_U_Cell_083 1;
BA_ "GenSigStartValue" SG_ 356 BCC_U_Cell_083 3700;
BA_ "GenSigCycleTime" SG_ 356 BCC_U_Cell_082 10;
BA_ "GenSigSendType" SG_ 356 BCC_U_Cell_082 1;
BA_ "GenSigStartValue" SG_ 356 BCC_U_Cell_082 3700;
BA_ "GenSigCycleTime" SG_ 356 BCC_U_Cell_081 10;
BA_ "GenSigSendType" SG_ 356 BCC_U_Cell_081 1;
BA_ "GenSigStartValue" SG_ 356 BCC_U_Cell_081 3700;
BA_ "GenSigCycleTime" SG_ 355 BCC_U_Cell_080 10;
BA_ "GenSigSendType" SG_ 355 BCC_U_Cell_080 1;
BA_ "GenSigStartValue" SG_ 355 BCC_U_Cell_080 3700;
BA_ "GenSigCycleTime" SG_ 355 BCC_U_Cell_079 10;
BA_ "GenSigSendType" SG_ 355 BCC_U_Cell_079 1;
BA_ "GenSigStartValue" SG_ 355 BCC_U_Cell_079 3700;
BA_ "GenSigCycleTime" SG_ 355 BCC_U_Cell_078 10;
BA_ "GenSigSendType" SG_ 355 BCC_U_Cell_078 1;
BA_ "GenSigStartValue" SG_ 355 BCC_U_Cell_078 3700;
BA_ "GenSigCycleTime" SG_ 355 BCC_U_Cell_077 10;
BA_ "GenSigSendType" SG_ 355 BCC_U_Cell_077 1;
BA_ "GenSigStartValue" SG_ 355 BCC_U_Cell_077 3700;
BA_ "GenSigCycleTime" SG_ 354 BCC_U_Cell_076 10;
BA_ "GenSigSendType" SG_ 354 BCC_U_Cell_076 1;
BA_ "GenSigStartValue" SG_ 354 BCC_U_Cell_076 3700;
BA_ "GenSigCycleTime" SG_ 354 BCC_U_Cell_075 10;
BA_ "GenSigSendType" SG_ 354 BCC_U_Cell_075 1;
BA_ "GenSigStartValue" SG_ 354 BCC_U_Cell_075 3700;
BA_ "GenSigCycleTime" SG_ 354 BCC_U_Cell_074 10;
BA_ "GenSigSendType" SG_ 354 BCC_U_Cell_074 1;
BA_ "GenSigStartValue" SG_ 354 BCC_U_Cell_074 3700;
BA_ "GenSigCycleTime" SG_ 354 BCC_U_Cell_073 10;
BA_ "GenSigSendType" SG_ 354 BCC_U_Cell_073 1;
BA_ "GenSigStartValue" SG_ 354 BCC_U_Cell_073 3700;
BA_ "GenSigCycleTime" SG_ 353 BCC_U_Cell_072 10;
BA_ "GenSigSendType" SG_ 353 BCC_U_Cell_072 1;
BA_ "GenSigStartValue" SG_ 353 BCC_U_Cell_072 3700;
BA_ "GenSigCycleTime" SG_ 353 BCC_U_Cell_071 10;
BA_ "GenSigSendType" SG_ 353 BCC_U_Cell_071 1;
BA_ "GenSigStartValue" SG_ 353 BCC_U_Cell_071 3700;
BA_ "GenSigCycleTime" SG_ 353 BCC_U_Cell_070 10;
BA_ "GenSigSendType" SG_ 353 BCC_U_Cell_070 1;
BA_ "GenSigStartValue" SG_ 353 BCC_U_Cell_070 3700;
BA_ "GenSigCycleTime" SG_ 353 BCC_U_Cell_069 10;
BA_ "GenSigSendType" SG_ 353 BCC_U_Cell_069 1;
BA_ "GenSigStartValue" SG_ 353 BCC_U_Cell_069 3700;
BA_ "GenSigCycleTime" SG_ 352 BCC_U_Cell_068 10;
BA_ "GenSigSendType" SG_ 352 BCC_U_Cell_068 1;
BA_ "GenSigStartValue" SG_ 352 BCC_U_Cell_068 3700;
BA_ "GenSigCycleTime" SG_ 352 BCC_U_Cell_067 10;
BA_ "GenSigSendType" SG_ 352 BCC_U_Cell_067 1;
BA_ "GenSigStartValue" SG_ 352 BCC_U_Cell_067 3700;
BA_ "GenSigCycleTime" SG_ 352 BCC_U_Cell_066 10;
BA_ "GenSigSendType" SG_ 352 BCC_U_Cell_066 1;
BA_ "GenSigStartValue" SG_ 352 BCC_U_Cell_066 3700;
BA_ "GenSigCycleTime" SG_ 352 BCC_U_Cell_065 10;
BA_ "GenSigSendType" SG_ 352 BCC_U_Cell_065 1;
BA_ "GenSigStartValue" SG_ 352 BCC_U_Cell_065 3700;
BA_ "GenSigCycleTime" SG_ 351 BCC_U_Cell_064 10;
BA_ "GenSigSendType" SG_ 351 BCC_U_Cell_064 1;
BA_ "GenSigStartValue" SG_ 351 BCC_U_Cell_064 3700;
BA_ "GenSigCycleTime" SG_ 351 BCC_U_Cell_063 10;
BA_ "GenSigSendType" SG_ 351 BCC_U_Cell_063 1;
BA_ "GenSigStartValue" SG_ 351 BCC_U_Cell_063 3700;
BA_ "GenSigCycleTime" SG_ 351 BCC_U_Cell_062 10;
BA_ "GenSigSendType" SG_ 351 BCC_U_Cell_062 1;
BA_ "GenSigStartValue" SG_ 351 BCC_U_Cell_062 3700;
BA_ "GenSigCycleTime" SG_ 351 BCC_U_Cell_061 10;
BA_ "GenSigSendType" SG_ 351 BCC_U_Cell_061 1;
BA_ "GenSigStartValue" SG_ 351 BCC_U_Cell_061 3700;
BA_ "GenSigCycleTime" SG_ 350 BCC_U_Cell_060 10;
BA_ "GenSigSendType" SG_ 350 BCC_U_Cell_060 1;
BA_ "GenSigStartValue" SG_ 350 BCC_U_Cell_060 3700;
BA_ "GenSigCycleTime" SG_ 350 BCC_U_Cell_059 10;
BA_ "GenSigSendType" SG_ 350 BCC_U_Cell_059 1;
BA_ "GenSigStartValue" SG_ 350 BCC_U_Cell_059 3700;
BA_ "GenSigCycleTime" SG_ 350 BCC_U_Cell_058 10;
BA_ "GenSigSendType" SG_ 350 BCC_U_Cell_058 1;
BA_ "GenSigStartValue" SG_ 350 BCC_U_Cell_058 3700;
BA_ "GenSigCycleTime" SG_ 350 BCC_U_Cell_057 10;
BA_ "GenSigSendType" SG_ 350 BCC_U_Cell_057 1;
BA_ "GenSigStartValue" SG_ 350 BCC_U_Cell_057 3700;
BA_ "GenSigCycleTime" SG_ 349 BCC_U_Cell_056 10;
BA_ "GenSigSendType" SG_ 349 BCC_U_Cell_056 1;
BA_ "GenSigStartValue" SG_ 349 BCC_U_Cell_056 3700;
BA_ "GenSigCycleTime" SG_ 349 BCC_U_Cell_055 10;
BA_ "GenSigSendType" SG_ 349 BCC_U_Cell_055 1;
BA_ "GenSigStartValue" SG_ 349 BCC_U_Cell_055 3700;
BA_ "GenSigCycleTime" SG_ 349 BCC_U_Cell_054 10;
BA_ "GenSigSendType" SG_ 349 BCC_U_Cell_054 1;
BA_ "GenSigStartValue" SG_ 349 BCC_U_Cell_054 3700;
BA_ "GenSigCycleTime" SG_ 349 BCC_U_Cell_053 10;
BA_ "GenSigSendType" SG_ 349 BCC_U_Cell_053 1;
BA_ "GenSigStartValue" SG_ 349 BCC_U_Cell_053 3700;
BA_ "GenSigCycleTime" SG_ 348 BCC_U_Cell_052 10;
BA_ "GenSigSendType" SG_ 348 BCC_U_Cell_052 1;
BA_ "GenSigStartValue" SG_ 348 BCC_U_Cell_052 3700;
BA_ "GenSigCycleTime" SG_ 348 BCC_U_Cell_051 10;
BA_ "GenSigSendType" SG_ 348 BCC_U_Cell_051 1;
BA_ "GenSigStartValue" SG_ 348 BCC_U_Cell_051 3700;
BA_ "GenSigCycleTime" SG_ 348 BCC_U_Cell_050 10;
BA_ "GenSigSendType" SG_ 348 BCC_U_Cell_050 1;
BA_ "GenSigStartValue" SG_ 348 BCC_U_Cell_050 3700;
BA_ "GenSigCycleTime" SG_ 348 BCC_U_Cell_049 10;
BA_ "GenSigSendType" SG_ 348 BCC_U_Cell_049 1;
BA_ "GenSigStartValue" SG_ 348 BCC_U_Cell_049 3700;
BA_ "GenSigCycleTime" SG_ 347 BCC_U_Cell_048 10;
BA_ "GenSigSendType" SG_ 347 BCC_U_Cell_048 1;
BA_ "GenSigStartValue" SG_ 347 BCC_U_Cell_048 3700;
BA_ "GenSigCycleTime" SG_ 347 BCC_U_Cell_047 10;
BA_ "GenSigSendType" SG_ 347 BCC_U_Cell_047 1;
BA_ "GenSigStartValue" SG_ 347 BCC_U_Cell_047 3700;
BA_ "GenSigCycleTime" SG_ 347 BCC_U_Cell_046 10;
BA_ "GenSigSendType" SG_ 347 BCC_U_Cell_046 1;
BA_ "GenSigStartValue" SG_ 347 BCC_U_Cell_046 3700;
BA_ "GenSigCycleTime" SG_ 347 BCC_U_Cell_045 10;
BA_ "GenSigSendType" SG_ 347 BCC_U_Cell_045 1;
BA_ "GenSigStartValue" SG_ 347 BCC_U_Cell_045 3700;
BA_ "GenSigCycleTime" SG_ 346 BCC_U_Cell_044 10;
BA_ "GenSigSendType" SG_ 346 BCC_U_Cell_044 1;
BA_ "GenSigStartValue" SG_ 346 BCC_U_Cell_044 3700;
BA_ "GenSigCycleTime" SG_ 346 BCC_U_Cell_043 10;
BA_ "GenSigSendType" SG_ 346 BCC_U_Cell_043 1;
BA_ "GenSigStartValue" SG_ 346 BCC_U_Cell_043 3700;
BA_ "GenSigCycleTime" SG_ 346 BCC_U_Cell_042 10;
BA_ "GenSigSendType" SG_ 346 BCC_U_Cell_042 1;
BA_ "GenSigStartValue" SG_ 346 BCC_U_Cell_042 3700;
BA_ "GenSigCycleTime" SG_ 346 BCC_U_Cell_041 10;
BA_ "GenSigSendType" SG_ 346 BCC_U_Cell_041 1;
BA_ "GenSigStartValue" SG_ 346 BCC_U_Cell_041 3700;
BA_ "GenSigCycleTime" SG_ 345 BCC_U_Cell_040 10;
BA_ "GenSigSendType" SG_ 345 BCC_U_Cell_040 1;
BA_ "GenSigStartValue" SG_ 345 BCC_U_Cell_040 3700;
BA_ "GenSigCycleTime" SG_ 345 BCC_U_Cell_039 10;
BA_ "GenSigSendType" SG_ 345 BCC_U_Cell_039 1;
BA_ "GenSigStartValue" SG_ 345 BCC_U_Cell_039 3700;
BA_ "GenSigCycleTime" SG_ 345 BCC_U_Cell_038 10;
BA_ "GenSigSendType" SG_ 345 BCC_U_Cell_038 1;
BA_ "GenSigStartValue" SG_ 345 BCC_U_Cell_038 3700;
BA_ "GenSigCycleTime" SG_ 345 BCC_U_Cell_037 10;
BA_ "GenSigSendType" SG_ 345 BCC_U_Cell_037 1;
BA_ "GenSigStartValue" SG_ 345 BCC_U_Cell_037 3700;
BA_ "GenSigCycleTime" SG_ 344 BCC_U_Cell_036 10;
BA_ "GenSigSendType" SG_ 344 BCC_U_Cell_036 1;
BA_ "GenSigStartValue" SG_ 344 BCC_U_Cell_036 3700;
BA_ "GenSigCycleTime" SG_ 344 BCC_U_Cell_035 10;
BA_ "GenSigSendType" SG_ 344 BCC_U_Cell_035 1;
BA_ "GenSigStartValue" SG_ 344 BCC_U_Cell_035 3700;
BA_ "GenSigCycleTime" SG_ 344 BCC_U_Cell_034 10;
BA_ "GenSigSendType" SG_ 344 BCC_U_Cell_034 1;
BA_ "GenSigStartValue" SG_ 344 BCC_U_Cell_034 3700;
BA_ "GenSigCycleTime" SG_ 344 BCC_U_Cell_033 10;
BA_ "GenSigSendType" SG_ 344 BCC_U_Cell_033 1;
BA_ "GenSigStartValue" SG_ 344 BCC_U_Cell_033 3700;
BA_ "GenSigCycleTime" SG_ 343 BCC_U_Cell_032 10;
BA_ "GenSigSendType" SG_ 343 BCC_U_Cell_032 1;
BA_ "GenSigStartValue" SG_ 343 BCC_U_Cell_032 3700;
BA_ "GenSigCycleTime" SG_ 343 BCC_U_Cell_031 10;
BA_ "GenSigSendType" SG_ 343 BCC_U_Cell_031 1;
BA_ "GenSigStartValue" SG_ 343 BCC_U_Cell_031 3700;
BA_ "GenSigCycleTime" SG_ 343 BCC_U_Cell_030 10;
BA_ "GenSigSendType" SG_ 343 BCC_U_Cell_030 1;
BA_ "GenSigStartValue" SG_ 343 BCC_U_Cell_030 3700;
BA_ "GenSigCycleTime" SG_ 343 BCC_U_Cell_029 10;
BA_ "GenSigSendType" SG_ 343 BCC_U_Cell_029 1;
BA_ "GenSigStartValue" SG_ 343 BCC_U_Cell_029 3700;
BA_ "GenSigCycleTime" SG_ 342 BCC_U_Cell_028 10;
BA_ "GenSigSendType" SG_ 342 BCC_U_Cell_028 1;
BA_ "GenSigStartValue" SG_ 342 BCC_U_Cell_028 3700;
BA_ "GenSigCycleTime" SG_ 342 BCC_U_Cell_027 10;
BA_ "GenSigSendType" SG_ 342 BCC_U_Cell_027 1;
BA_ "GenSigStartValue" SG_ 342 BCC_U_Cell_027 3700;
BA_ "GenSigCycleTime" SG_ 342 BCC_U_Cell_026 10;
BA_ "GenSigSendType" SG_ 342 BCC_U_Cell_026 1;
BA_ "GenSigStartValue" SG_ 342 BCC_U_Cell_026 3700;
BA_ "GenSigCycleTime" SG_ 342 BCC_U_Cell_025 10;
BA_ "GenSigSendType" SG_ 342 BCC_U_Cell_025 1;
BA_ "GenSigStartValue" SG_ 342 BCC_U_Cell_025 3700;
BA_ "GenSigCycleTime" SG_ 341 BCC_U_Cell_024 10;
BA_ "GenSigSendType" SG_ 341 BCC_U_Cell_024 1;
BA_ "GenSigStartValue" SG_ 341 BCC_U_Cell_024 3700;
BA_ "GenSigCycleTime" SG_ 341 BCC_U_Cell_023 10;
BA_ "GenSigSendType" SG_ 341 BCC_U_Cell_023 1;
BA_ "GenSigStartValue" SG_ 341 BCC_U_Cell_023 3700;
BA_ "GenSigCycleTime" SG_ 341 BCC_U_Cell_022 10;
BA_ "GenSigSendType" SG_ 341 BCC_U_Cell_022 1;
BA_ "GenSigStartValue" SG_ 341 BCC_U_Cell_022 3700;
BA_ "GenSigCycleTime" SG_ 341 BCC_U_Cell_021 10;
BA_ "GenSigSendType" SG_ 341 BCC_U_Cell_021 1;
BA_ "GenSigStartValue" SG_ 341 BCC_U_Cell_021 3700;
BA_ "GenSigCycleTime" SG_ 340 BCC_U_Cell_020 10;
BA_ "GenSigSendType" SG_ 340 BCC_U_Cell_020 1;
BA_ "GenSigStartValue" SG_ 340 BCC_U_Cell_020 3700;
BA_ "GenSigCycleTime" SG_ 340 BCC_U_Cell_019 10;
BA_ "GenSigSendType" SG_ 340 BCC_U_Cell_019 1;
BA_ "GenSigStartValue" SG_ 340 BCC_U_Cell_019 3700;
BA_ "GenSigCycleTime" SG_ 340 BCC_U_Cell_018 10;
BA_ "GenSigSendType" SG_ 340 BCC_U_Cell_018 1;
BA_ "GenSigStartValue" SG_ 340 BCC_U_Cell_018 3700;
BA_ "GenSigCycleTime" SG_ 340 BCC_U_Cell_017 10;
BA_ "GenSigSendType" SG_ 340 BCC_U_Cell_017 1;
BA_ "GenSigStartValue" SG_ 340 BCC_U_Cell_017 3700;
BA_ "GenSigCycleTime" SG_ 339 BCC_U_Cell_016 10;
BA_ "GenSigSendType" SG_ 339 BCC_U_Cell_016 1;
BA_ "GenSigStartValue" SG_ 339 BCC_U_Cell_016 3700;
BA_ "GenSigCycleTime" SG_ 339 BCC_U_Cell_015 10;
BA_ "GenSigSendType" SG_ 339 BCC_U_Cell_015 1;
BA_ "GenSigStartValue" SG_ 339 BCC_U_Cell_015 3700;
BA_ "GenSigCycleTime" SG_ 339 BCC_U_Cell_014 10;
BA_ "GenSigSendType" SG_ 339 BCC_U_Cell_014 1;
BA_ "GenSigStartValue" SG_ 339 BCC_U_Cell_014 3700;
BA_ "GenSigCycleTime" SG_ 339 BCC_U_Cell_013 10;
BA_ "GenSigSendType" SG_ 339 BCC_U_Cell_013 1;
BA_ "GenSigStartValue" SG_ 339 BCC_U_Cell_013 3700;
BA_ "GenSigCycleTime" SG_ 338 BCC_U_Cell_012 10;
BA_ "GenSigSendType" SG_ 338 BCC_U_Cell_012 1;
BA_ "GenSigStartValue" SG_ 338 BCC_U_Cell_012 3700;
BA_ "GenSigCycleTime" SG_ 338 BCC_U_Cell_011 10;
BA_ "GenSigSendType" SG_ 338 BCC_U_Cell_011 1;
BA_ "GenSigStartValue" SG_ 338 BCC_U_Cell_011 3700;
BA_ "GenSigCycleTime" SG_ 338 BCC_U_Cell_010 10;
BA_ "GenSigSendType" SG_ 338 BCC_U_Cell_010 1;
BA_ "GenSigStartValue" SG_ 338 BCC_U_Cell_010 3700;
BA_ "GenSigCycleTime" SG_ 338 BCC_U_Cell_009 10;
BA_ "GenSigSendType" SG_ 338 BCC_U_Cell_009 1;
BA_ "GenSigStartValue" SG_ 338 BCC_U_Cell_009 3700;
BA_ "GenSigCycleTime" SG_ 337 BCC_U_Cell_008 10;
BA_ "GenSigSendType" SG_ 337 BCC_U_Cell_008 1;
BA_ "GenSigStartValue" SG_ 337 BCC_U_Cell_008 3700;
BA_ "GenSigCycleTime" SG_ 337 BCC_U_Cell_007 10;
BA_ "GenSigSendType" SG_ 337 BCC_U_Cell_007 1;
BA_ "GenSigStartValue" SG_ 337 BCC_U_Cell_007 3700;
BA_ "GenSigCycleTime" SG_ 337 BCC_U_Cell_006 10;
BA_ "GenSigSendType" SG_ 337 BCC_U_Cell_006 1;
BA_ "GenSigStartValue" SG_ 337 BCC_U_Cell_006 3700;
BA_ "GenSigCycleTime" SG_ 337 BCC_U_Cell_005 10;
BA_ "GenSigSendType" SG_ 337 BCC_U_Cell_005 1;
BA_ "GenSigStartValue" SG_ 337 BCC_U_Cell_005 3700;
BA_ "GenSigCycleTime" SG_ 336 BCC_U_Cell_004 10;
BA_ "GenSigSendType" SG_ 336 BCC_U_Cell_004 1;
BA_ "GenSigStartValue" SG_ 336 BCC_U_Cell_004 3700;
BA_ "GenSigCycleTime" SG_ 336 BCC_U_Cell_003 10;
BA_ "GenSigSendType" SG_ 336 BCC_U_Cell_003 1;
BA_ "GenSigStartValue" SG_ 336 BCC_U_Cell_003 3700;
BA_ "GenSigCycleTime" SG_ 336 BCC_U_Cell_002 10;
BA_ "GenSigSendType" SG_ 336 BCC_U_Cell_002 1;
BA_ "GenSigStartValue" SG_ 336 BCC_U_Cell_002 3700;
BA_ "GenSigCycleTime" SG_ 336 BCC_U_Cell_001 10;
BA_ "GenSigSendType" SG_ 336 BCC_U_Cell_001 1;
BA_ "GenSigStartValue" SG_ 336 BCC_U_Cell_001 3700;
BA_ "GenSigCycleTime" SG_ 298 BCC_Diag_OCV_Arr21_1mV_21 100;
BA_ "GenSigSendType" SG_ 298 BCC_Diag_OCV_Arr21_1mV_21 1;
BA_ "GenSigCycleTime" SG_ 297 BCC_Diag_OCV_Arr21_1mV_20 100;
BA_ "GenSigSendType" SG_ 297 BCC_Diag_OCV_Arr21_1mV_20 1;
BA_ "GenSigCycleTime" SG_ 297 BCC_Diag_OCV_Arr21_1mV_19 100;
BA_ "GenSigSendType" SG_ 297 BCC_Diag_OCV_Arr21_1mV_19 1;
BA_ "GenSigCycleTime" SG_ 296 BCC_Diag_OCV_Arr21_1mV_18 100;
BA_ "GenSigSendType" SG_ 296 BCC_Diag_OCV_Arr21_1mV_18 1;
BA_ "GenSigCycleTime" SG_ 296 BCC_Diag_OCV_Arr21_1mV_17 100;
BA_ "GenSigSendType" SG_ 296 BCC_Diag_OCV_Arr21_1mV_17 1;
BA_ "GenSigCycleTime" SG_ 295 BCC_Diag_OCV_Arr21_1mV_16 100;
BA_ "GenSigSendType" SG_ 295 BCC_Diag_OCV_Arr21_1mV_16 1;
BA_ "GenSigCycleTime" SG_ 295 BCC_Diag_OCV_Arr21_1mV_15 100;
BA_ "GenSigSendType" SG_ 295 BCC_Diag_OCV_Arr21_1mV_15 1;
BA_ "GenSigCycleTime" SG_ 294 BCC_Diag_OCV_Arr21_1mV_14 100;
BA_ "GenSigSendType" SG_ 294 BCC_Diag_OCV_Arr21_1mV_14 1;
BA_ "GenSigCycleTime" SG_ 294 BCC_Diag_OCV_Arr21_1mV_13 100;
BA_ "GenSigSendType" SG_ 294 BCC_Diag_OCV_Arr21_1mV_13 1;
BA_ "GenSigCycleTime" SG_ 293 BCC_Diag_OCV_Arr21_1mV_12 100;
BA_ "GenSigSendType" SG_ 293 BCC_Diag_OCV_Arr21_1mV_12 1;
BA_ "GenSigCycleTime" SG_ 293 BCC_Diag_OCV_Arr21_1mV_11 100;
BA_ "GenSigSendType" SG_ 293 BCC_Diag_OCV_Arr21_1mV_11 1;
BA_ "GenSigCycleTime" SG_ 292 BCC_Diag_OCV_Arr21_1mV_10 100;
BA_ "GenSigSendType" SG_ 292 BCC_Diag_OCV_Arr21_1mV_10 1;
BA_ "GenSigCycleTime" SG_ 292 BCC_Diag_OCV_Arr21_1mV_09 100;
BA_ "GenSigSendType" SG_ 292 BCC_Diag_OCV_Arr21_1mV_09 1;
BA_ "GenSigCycleTime" SG_ 291 BCC_Diag_OCV_Arr21_1mV_08 100;
BA_ "GenSigSendType" SG_ 291 BCC_Diag_OCV_Arr21_1mV_08 1;
BA_ "GenSigCycleTime" SG_ 291 BCC_Diag_OCV_Arr21_1mV_07 100;
BA_ "GenSigSendType" SG_ 291 BCC_Diag_OCV_Arr21_1mV_07 1;
BA_ "GenSigCycleTime" SG_ 290 BCC_Diag_OCV_Arr21_1mV_06 100;
BA_ "GenSigSendType" SG_ 290 BCC_Diag_OCV_Arr21_1mV_06 1;
BA_ "GenSigCycleTime" SG_ 290 BCC_Diag_OCV_Arr21_1mV_05 100;
BA_ "GenSigSendType" SG_ 290 BCC_Diag_OCV_Arr21_1mV_05 1;
BA_ "GenSigCycleTime" SG_ 289 BCC_Diag_OCV_Arr21_1mV_04 100;
BA_ "GenSigSendType" SG_ 289 BCC_Diag_OCV_Arr21_1mV_04 1;
BA_ "GenSigCycleTime" SG_ 289 BCC_Diag_OCV_Arr21_1mV_03 100;
BA_ "GenSigSendType" SG_ 289 BCC_Diag_OCV_Arr21_1mV_03 1;
BA_ "GenSigCycleTime" SG_ 288 BCC_Diag_OCV_Arr21_1mV_02 100;
BA_ "GenSigSendType" SG_ 288 BCC_Diag_OCV_Arr21_1mV_02 1;
BA_ "GenSigCycleTime" SG_ 288 BCC_Diag_OCV_Arr21_1mV_01 100;
BA_ "GenSigSendType" SG_ 288 BCC_Diag_OCV_Arr21_1mV_01 1;
BA_ "GenSigCycleTime" SG_ 331 BCC_U_Cell_SNA_Mode_100 100;
BA_ "GenSigSendType" SG_ 331 BCC_U_Cell_SNA_Mode_100 1;
BA_ "GenSigCycleTime" SG_ 331 BCC_U_Cell_SNA_Mode_099 100;
BA_ "GenSigSendType" SG_ 331 BCC_U_Cell_SNA_Mode_099 1;
BA_ "GenSigCycleTime" SG_ 331 BCC_U_Cell_SNA_Mode_098 100;
BA_ "GenSigSendType" SG_ 331 BCC_U_Cell_SNA_Mode_098 1;
BA_ "GenSigCycleTime" SG_ 331 BCC_U_Cell_SNA_Mode_097 100;
BA_ "GenSigSendType" SG_ 331 BCC_U_Cell_SNA_Mode_097 1;
BA_ "GenSigCycleTime" SG_ 331 BCC_U_Cell_SNA_Mode_096 100;
BA_ "GenSigSendType" SG_ 331 BCC_U_Cell_SNA_Mode_096 1;
BA_ "GenSigCycleTime" SG_ 331 BCC_U_Cell_SNA_Mode_095 100;
BA_ "GenSigSendType" SG_ 331 BCC_U_Cell_SNA_Mode_095 1;
BA_ "GenSigCycleTime" SG_ 331 BCC_U_Cell_SNA_Mode_094 100;
BA_ "GenSigSendType" SG_ 331 BCC_U_Cell_SNA_Mode_094 1;
BA_ "GenSigCycleTime" SG_ 331 BCC_U_Cell_SNA_Mode_093 100;
BA_ "GenSigSendType" SG_ 331 BCC_U_Cell_SNA_Mode_093 1;
BA_ "GenSigCycleTime" SG_ 331 BCC_U_Cell_SNA_Mode_092 100;
BA_ "GenSigSendType" SG_ 331 BCC_U_Cell_SNA_Mode_092 1;
BA_ "GenSigCycleTime" SG_ 331 BCC_U_Cell_SNA_Mode_091 100;
BA_ "GenSigSendType" SG_ 331 BCC_U_Cell_SNA_Mode_091 1;
BA_ "GenSigCycleTime" SG_ 331 BCC_U_Cell_SNA_Mode_090 100;
BA_ "GenSigSendType" SG_ 331 BCC_U_Cell_SNA_Mode_090 1;
BA_ "GenSigCycleTime" SG_ 331 BCC_U_Cell_SNA_Mode_089 100;
BA_ "GenSigSendType" SG_ 331 BCC_U_Cell_SNA_Mode_089 1;
BA_ "GenSigCycleTime" SG_ 331 BCC_U_Cell_SNA_Mode_088 100;
BA_ "GenSigSendType" SG_ 331 BCC_U_Cell_SNA_Mode_088 1;
BA_ "GenSigCycleTime" SG_ 331 BCC_U_Cell_SNA_Mode_087 100;
BA_ "GenSigSendType" SG_ 331 BCC_U_Cell_SNA_Mode_087 1;
BA_ "GenSigCycleTime" SG_ 331 BCC_U_Cell_SNA_Mode_086 100;
BA_ "GenSigSendType" SG_ 331 BCC_U_Cell_SNA_Mode_086 1;
BA_ "GenSigCycleTime" SG_ 331 BCC_U_Cell_SNA_Mode_085 100;
BA_ "GenSigSendType" SG_ 331 BCC_U_Cell_SNA_Mode_085 1;
BA_ "GenSigCycleTime" SG_ 331 BCC_U_Cell_SNA_Mode_084 100;
BA_ "GenSigSendType" SG_ 331 BCC_U_Cell_SNA_Mode_084 1;
BA_ "GenSigCycleTime" SG_ 331 BCC_U_Cell_SNA_Mode_083 100;
BA_ "GenSigSendType" SG_ 331 BCC_U_Cell_SNA_Mode_083 1;
BA_ "GenSigCycleTime" SG_ 331 BCC_U_Cell_SNA_Mode_082 100;
BA_ "GenSigSendType" SG_ 331 BCC_U_Cell_SNA_Mode_082 1;
BA_ "GenSigCycleTime" SG_ 331 BCC_U_Cell_SNA_Mode_081 100;
BA_ "GenSigSendType" SG_ 331 BCC_U_Cell_SNA_Mode_081 1;
BA_ "GenSigCycleTime" SG_ 331 BCC_U_Cell_SNA_Mode_080 100;
BA_ "GenSigSendType" SG_ 331 BCC_U_Cell_SNA_Mode_080 1;
BA_ "GenSigCycleTime" SG_ 331 BCC_U_Cell_SNA_Mode_079 100;
BA_ "GenSigSendType" SG_ 331 BCC_U_Cell_SNA_Mode_079 1;
BA_ "GenSigCycleTime" SG_ 331 BCC_U_Cell_SNA_Mode_078 100;
BA_ "GenSigSendType" SG_ 331 BCC_U_Cell_SNA_Mode_078 1;
BA_ "GenSigCycleTime" SG_ 331 BCC_U_Cell_SNA_Mode_077 100;
BA_ "GenSigSendType" SG_ 331 BCC_U_Cell_SNA_Mode_077 1;
BA_ "GenSigCycleTime" SG_ 331 BCC_U_Cell_SNA_Mode_076 100;
BA_ "GenSigSendType" SG_ 331 BCC_U_Cell_SNA_Mode_076 1;
BA_ "GenSigCycleTime" SG_ 331 BCC_U_Cell_SNA_Mode_075 100;
BA_ "GenSigSendType" SG_ 331 BCC_U_Cell_SNA_Mode_075 1;
BA_ "GenSigCycleTime" SG_ 331 BCC_U_Cell_SNA_Mode_074 100;
BA_ "GenSigSendType" SG_ 331 BCC_U_Cell_SNA_Mode_074 1;
BA_ "GenSigCycleTime" SG_ 331 BCC_U_Cell_SNA_Mode_073 100;
BA_ "GenSigSendType" SG_ 331 BCC_U_Cell_SNA_Mode_073 1;
BA_ "GenSigCycleTime" SG_ 331 BCC_U_Cell_SNA_Mode_072 100;
BA_ "GenSigSendType" SG_ 331 BCC_U_Cell_SNA_Mode_072 1;
BA_ "GenSigCycleTime" SG_ 331 BCC_U_Cell_SNA_Mode_071 100;
BA_ "GenSigSendType" SG_ 331 BCC_U_Cell_SNA_Mode_071 1;
BA_ "GenSigCycleTime" SG_ 331 BCC_U_Cell_SNA_Mode_070 100;
BA_ "GenSigSendType" SG_ 331 BCC_U_Cell_SNA_Mode_070 1;
BA_ "GenSigCycleTime" SG_ 331 BCC_U_Cell_SNA_Mode_069 100;
BA_ "GenSigSendType" SG_ 331 BCC_U_Cell_SNA_Mode_069 1;
BA_ "GenSigCycleTime" SG_ 331 BCC_U_Cell_SNA_Mode_068 100;
BA_ "GenSigSendType" SG_ 331 BCC_U_Cell_SNA_Mode_068 1;
BA_ "GenSigCycleTime" SG_ 331 BCC_U_Cell_SNA_Mode_067 100;
BA_ "GenSigSendType" SG_ 331 BCC_U_Cell_SNA_Mode_067 1;
BA_ "GenSigCycleTime" SG_ 331 BCC_U_Cell_SNA_Mode_066 100;
BA_ "GenSigSendType" SG_ 331 BCC_U_Cell_SNA_Mode_066 1;
BA_ "GenSigCycleTime" SG_ 331 BCC_U_Cell_SNA_Mode_065 100;
BA_ "GenSigSendType" SG_ 331 BCC_U_Cell_SNA_Mode_065 1;
BA_ "GenSigCycleTime" SG_ 304 BCC_T_Batt_SNA_Mode_30 100;
BA_ "GenSigSendType" SG_ 304 BCC_T_Batt_SNA_Mode_30 1;
BA_ "GenSigCycleTime" SG_ 304 BCC_T_Batt_SNA_Mode_29 100;
BA_ "GenSigSendType" SG_ 304 BCC_T_Batt_SNA_Mode_29 1;
BA_ "GenSigCycleTime" SG_ 304 BCC_T_Batt_SNA_Mode_28 100;
BA_ "GenSigSendType" SG_ 304 BCC_T_Batt_SNA_Mode_28 1;
BA_ "GenSigCycleTime" SG_ 304 BCC_T_Batt_SNA_Mode_27 100;
BA_ "GenSigSendType" SG_ 304 BCC_T_Batt_SNA_Mode_27 1;
BA_ "GenSigCycleTime" SG_ 304 BCC_T_Batt_SNA_Mode_26 100;
BA_ "GenSigSendType" SG_ 304 BCC_T_Batt_SNA_Mode_26 1;
BA_ "GenSigCycleTime" SG_ 304 BCC_T_Batt_SNA_Mode_25 100;
BA_ "GenSigSendType" SG_ 304 BCC_T_Batt_SNA_Mode_25 1;
BA_ "GenSigCycleTime" SG_ 304 BCC_T_Batt_SNA_Mode_24 100;
BA_ "GenSigSendType" SG_ 304 BCC_T_Batt_SNA_Mode_24 1;
BA_ "GenSigCycleTime" SG_ 304 BCC_T_Batt_SNA_Mode_23 100;
BA_ "GenSigSendType" SG_ 304 BCC_T_Batt_SNA_Mode_23 1;
BA_ "GenSigCycleTime" SG_ 304 BCC_T_Batt_SNA_Mode_22 100;
BA_ "GenSigSendType" SG_ 304 BCC_T_Batt_SNA_Mode_22 1;
BA_ "GenSigCycleTime" SG_ 304 BCC_T_Batt_SNA_Mode_21 100;
BA_ "GenSigSendType" SG_ 304 BCC_T_Batt_SNA_Mode_21 1;
BA_ "GenSigCycleTime" SG_ 304 BCC_T_Batt_SNA_Mode_20 100;
BA_ "GenSigSendType" SG_ 304 BCC_T_Batt_SNA_Mode_20 1;
BA_ "GenSigCycleTime" SG_ 304 BCC_T_Batt_SNA_Mode_19 100;
BA_ "GenSigSendType" SG_ 304 BCC_T_Batt_SNA_Mode_19 1;
BA_ "GenSigCycleTime" SG_ 304 BCC_T_Batt_SNA_Mode_18 100;
BA_ "GenSigSendType" SG_ 304 BCC_T_Batt_SNA_Mode_18 1;
BA_ "GenSigCycleTime" SG_ 304 BCC_T_Batt_SNA_Mode_17 100;
BA_ "GenSigSendType" SG_ 304 BCC_T_Batt_SNA_Mode_17 1;
BA_ "GenSigCycleTime" SG_ 304 BCC_T_Batt_SNA_Mode_16 100;
BA_ "GenSigSendType" SG_ 304 BCC_T_Batt_SNA_Mode_16 1;
BA_ "GenSigCycleTime" SG_ 304 BCC_T_Batt_SNA_Mode_15 100;
BA_ "GenSigSendType" SG_ 304 BCC_T_Batt_SNA_Mode_15 1;
BA_ "GenSigCycleTime" SG_ 304 BCC_T_Batt_SNA_Mode_14 100;
BA_ "GenSigSendType" SG_ 304 BCC_T_Batt_SNA_Mode_14 1;
BA_ "GenSigCycleTime" SG_ 304 BCC_T_Batt_SNA_Mode_13 100;
BA_ "GenSigSendType" SG_ 304 BCC_T_Batt_SNA_Mode_13 1;
BA_ "GenSigCycleTime" SG_ 304 BCC_T_Batt_SNA_Mode_12 100;
BA_ "GenSigSendType" SG_ 304 BCC_T_Batt_SNA_Mode_12 1;
BA_ "GenSigCycleTime" SG_ 304 BCC_T_Batt_SNA_Mode_11 100;
BA_ "GenSigSendType" SG_ 304 BCC_T_Batt_SNA_Mode_11 1;
BA_ "GenSigCycleTime" SG_ 304 BCC_T_Batt_SNA_Mode_10 100;
BA_ "GenSigSendType" SG_ 304 BCC_T_Batt_SNA_Mode_10 1;
BA_ "GenSigCycleTime" SG_ 304 BCC_T_Batt_SNA_Mode_09 100;
BA_ "GenSigSendType" SG_ 304 BCC_T_Batt_SNA_Mode_09 1;
BA_ "GenSigCycleTime" SG_ 304 BCC_T_Batt_SNA_Mode_08 100;
BA_ "GenSigSendType" SG_ 304 BCC_T_Batt_SNA_Mode_08 1;
BA_ "GenSigCycleTime" SG_ 304 BCC_T_Batt_SNA_Mode_07 100;
BA_ "GenSigSendType" SG_ 304 BCC_T_Batt_SNA_Mode_07 1;
BA_ "GenSigCycleTime" SG_ 304 BCC_T_Batt_SNA_Mode_06 100;
BA_ "GenSigSendType" SG_ 304 BCC_T_Batt_SNA_Mode_06 1;
BA_ "GenSigCycleTime" SG_ 304 BCC_T_Batt_SNA_Mode_05 100;
BA_ "GenSigSendType" SG_ 304 BCC_T_Batt_SNA_Mode_05 1;
BA_ "GenSigCycleTime" SG_ 304 BCC_T_Batt_SNA_Mode_04 100;
BA_ "GenSigSendType" SG_ 304 BCC_T_Batt_SNA_Mode_04 1;
BA_ "GenSigCycleTime" SG_ 304 BCC_T_Batt_SNA_Mode_03 100;
BA_ "GenSigSendType" SG_ 304 BCC_T_Batt_SNA_Mode_03 1;
BA_ "GenSigCycleTime" SG_ 304 BCC_T_Batt_SNA_Mode_02 100;
BA_ "GenSigSendType" SG_ 304 BCC_T_Batt_SNA_Mode_02 1;
BA_ "GenSigCycleTime" SG_ 304 BCC_T_Batt_SNA_Mode_01 100;
BA_ "GenSigSendType" SG_ 304 BCC_T_Batt_SNA_Mode_01 1;
BA_ "GenSigCycleTime" SG_ 304 BCC_T_Batt 100;
BA_ "GenSigSendType" SG_ 304 BCC_T_Batt 1;
BA_ "GenSigCycleTime" SG_ 560 BCASO_U_Batt_Sum_of_U_Cell 100;
BA_ "GenSigSendType" SG_ 560 BCASO_U_Batt_Sum_of_U_Cell 1;
BA_ "GenSigCycleTime" SG_ 560 BCASO_I_Batt_Filtered 100;
BA_ "GenSigSendType" SG_ 560 BCASO_I_Batt_Filtered 1;
BA_ "GenSigCycleTime" SG_ 571 BCASO_Time_Sw_Open 100;
BA_ "GenSigSendType" SG_ 571 BCASO_Time_Sw_Open 1;
BA_ "GenSigCycleTime" SG_ 563 BCASO_SwitchOpenChargeEnd_Rq 100;
BA_ "GenSigSendType" SG_ 563 BCASO_SwitchOpenChargeEnd_Rq 1;
BA_ "GenSigCycleTime" SG_ 563 BCASO_Run_Req 100;
BA_ "GenSigSendType" SG_ 563 BCASO_Run_Req 1;
BA_ "GenSigCycleTime" SG_ 563 BCASO_Recalibrate_Req 100;
BA_ "GenSigSendType" SG_ 563 BCASO_Recalibrate_Req 1;
BA_ "GenSigCycleTime" SG_ 563 BCASO_OCV_Mode 100;
BA_ "GenSigSendType" SG_ 563 BCASO_OCV_Mode 1;
BA_ "GenSigCycleTime" SG_ 563 BCASO_Diag_OCV_Mode 100;
BA_ "GenSigSendType" SG_ 563 BCASO_Diag_OCV_Mode 1;
BA_ "GenSigCycleTime" SG_ 563 BCASO_Diag_Capa_Mode 100;
BA_ "GenSigSendType" SG_ 563 BCASO_Diag_Capa_Mode 1;
BA_ "GenSigCycleTime" SG_ 563 BCASO_Bal_Finished_Mode 100;
BA_ "GenSigSendType" SG_ 563 BCASO_Bal_Finished_Mode 1;
BA_ "GenSigCycleTime" SG_ 563 BCASO_NoCurr_Req 100;
BA_ "GenSigSendType" SG_ 563 BCASO_NoCurr_Req 1;
BA_ "GenSigCycleTime" SG_ 563 BCASO_Cell_Error 100;
BA_ "GenSigSendType" SG_ 563 BCASO_Cell_Error 1;
BA_ "GenSigCycleTime" SG_ 572 BCASO_U_Cell_Min 100;
BA_ "GenSigSendType" SG_ 572 BCASO_U_Cell_Min 1;
BA_ "GenSigCycleTime" SG_ 572 BCASO_U_Cell_Max 100;
BA_ "GenSigSendType" SG_ 572 BCASO_U_Cell_Max 1;
BA_ "GenSigCycleTime" SG_ 570 BCASO_T_Batt_Min 100;
BA_ "GenSigSendType" SG_ 570 BCASO_T_Batt_Min 1;
BA_ "GenSigCycleTime" SG_ 570 BCASO_T_Batt_Max 100;
BA_ "GenSigSendType" SG_ 570 BCASO_T_Batt_Max 1;
BA_ "GenSigCycleTime" SG_ 562 BCASO_Waterpump_Cmd 100;
BA_ "GenSigSendType" SG_ 562 BCASO_Waterpump_Cmd 1;
BA_ "GenSigCycleTime" SG_ 562 BCASO_CoolantInletTemp 100;
BA_ "GenSigStartValue" SG_ 562 BCASO_CoolantInletTemp 80;
BA_ "GenSigSendType" SG_ 562 BCASO_CoolantInletTemp 1;
BA_ "GenSigCycleTime" SG_ 562 BCASO_CoolAmount_Rq 100;
BA_ "GenSigSendType" SG_ 562 BCASO_CoolAmount_Rq 1;
BA_ "GenSigCycleTime" SG_ 562 BCASO_SwitchingValve_Cmd 100;
BA_ "GenSigSendType" SG_ 562 BCASO_SwitchingValve_Cmd 1;
BA_ "GenSigCycleTime" SG_ 562 BCASO_Fan_Cmd 100;
BA_ "GenSigSendType" SG_ 562 BCASO_Fan_Cmd 1;
BA_ "GenSigCycleTime" SG_ 562 BCASO_CoolValve_Req 100;
BA_ "GenSigSendType" SG_ 562 BCASO_CoolValve_Req 1;
BA_ "GenSigCycleTime" SG_ 562 BCASO_ChillerValve_Cmd 100;
BA_ "GenSigSendType" SG_ 562 BCASO_ChillerValve_Cmd 1;
BA_ "GenSigCycleTime" SG_ 562 BCASO_Batt_Cool_Req 100;
BA_ "GenSigSendType" SG_ 562 BCASO_Batt_Cool_Req 1;
BA_ "GenSigCycleTime" SG_ 561 BCASO_CapaHV_As_ref_1 100;
BA_ "GenSigSendType" SG_ 561 BCASO_CapaHV_As_ref_1 1;
BA_ "GenSigCycleTime" SG_ 561 BCASO_CapaHV_As_act_1 100;
BA_ "GenSigSendType" SG_ 561 BCASO_CapaHV_As_act_1 1;
BA_ "GenSigCycleTime" SG_ 569 BCASO_SOC_Min 100;
BA_ "GenSigStartValue" SG_ 569 BCASO_SOC_Min 960;
BA_ "GenSigSendType" SG_ 569 BCASO_SOC_Min 1;
BA_ "GenSigCycleTime" SG_ 569 BCASO_SOC_Max 100;
BA_ "GenSigStartValue" SG_ 569 BCASO_SOC_Max 960;
BA_ "GenSigSendType" SG_ 569 BCASO_SOC_Max 1;
BA_ "GenSigCycleTime" SG_ 568 BCASO_SOC_Disp 100;
BA_ "GenSigSendType" SG_ 568 BCASO_SOC_Disp 1;
BA_ "GenSigCycleTime" SG_ 568 BCASO_SOC 100;
BA_ "GenSigSendType" SG_ 568 BCASO_SOC 1;
BA_ "GenSigCycleTime" SG_ 330 BCC_U_Cell_SNA_Mode_064 100;
BA_ "GenSigSendType" SG_ 330 BCC_U_Cell_SNA_Mode_064 1;
BA_ "GenSigCycleTime" SG_ 330 BCC_U_Cell_SNA_Mode_063 100;
BA_ "GenSigSendType" SG_ 330 BCC_U_Cell_SNA_Mode_063 1;
BA_ "GenSigCycleTime" SG_ 330 BCC_U_Cell_SNA_Mode_062 100;
BA_ "GenSigSendType" SG_ 330 BCC_U_Cell_SNA_Mode_062 1;
BA_ "GenSigCycleTime" SG_ 330 BCC_U_Cell_SNA_Mode_061 100;
BA_ "GenSigSendType" SG_ 330 BCC_U_Cell_SNA_Mode_061 1;
BA_ "GenSigCycleTime" SG_ 330 BCC_U_Cell_SNA_Mode_060 100;
BA_ "GenSigSendType" SG_ 330 BCC_U_Cell_SNA_Mode_060 1;
BA_ "GenSigCycleTime" SG_ 330 BCC_U_Cell_SNA_Mode_059 100;
BA_ "GenSigSendType" SG_ 330 BCC_U_Cell_SNA_Mode_059 1;
BA_ "GenSigCycleTime" SG_ 330 BCC_U_Cell_SNA_Mode_058 100;
BA_ "GenSigSendType" SG_ 330 BCC_U_Cell_SNA_Mode_058 1;
BA_ "GenSigCycleTime" SG_ 330 BCC_U_Cell_SNA_Mode_057 100;
BA_ "GenSigSendType" SG_ 330 BCC_U_Cell_SNA_Mode_057 1;
BA_ "GenSigCycleTime" SG_ 330 BCC_U_Cell_SNA_Mode_056 100;
BA_ "GenSigSendType" SG_ 330 BCC_U_Cell_SNA_Mode_056 1;
BA_ "GenSigCycleTime" SG_ 330 BCC_U_Cell_SNA_Mode_055 100;
BA_ "GenSigSendType" SG_ 330 BCC_U_Cell_SNA_Mode_055 1;
BA_ "GenSigCycleTime" SG_ 330 BCC_U_Cell_SNA_Mode_054 100;
BA_ "GenSigSendType" SG_ 330 BCC_U_Cell_SNA_Mode_054 1;
BA_ "GenSigCycleTime" SG_ 330 BCC_U_Cell_SNA_Mode_053 100;
BA_ "GenSigSendType" SG_ 330 BCC_U_Cell_SNA_Mode_053 1;
BA_ "GenSigCycleTime" SG_ 330 BCC_U_Cell_SNA_Mode_052 100;
BA_ "GenSigSendType" SG_ 330 BCC_U_Cell_SNA_Mode_052 1;
BA_ "GenSigCycleTime" SG_ 330 BCC_U_Cell_SNA_Mode_051 100;
BA_ "GenSigSendType" SG_ 330 BCC_U_Cell_SNA_Mode_051 1;
BA_ "GenSigCycleTime" SG_ 330 BCC_U_Cell_SNA_Mode_050 100;
BA_ "GenSigSendType" SG_ 330 BCC_U_Cell_SNA_Mode_050 1;
BA_ "GenSigCycleTime" SG_ 330 BCC_U_Cell_SNA_Mode_049 100;
BA_ "GenSigSendType" SG_ 330 BCC_U_Cell_SNA_Mode_049 1;
BA_ "GenSigCycleTime" SG_ 330 BCC_U_Cell_SNA_Mode_048 100;
BA_ "GenSigSendType" SG_ 330 BCC_U_Cell_SNA_Mode_048 1;
BA_ "GenSigCycleTime" SG_ 330 BCC_U_Cell_SNA_Mode_047 100;
BA_ "GenSigSendType" SG_ 330 BCC_U_Cell_SNA_Mode_047 1;
BA_ "GenSigCycleTime" SG_ 330 BCC_U_Cell_SNA_Mode_046 100;
BA_ "GenSigSendType" SG_ 330 BCC_U_Cell_SNA_Mode_046 1;
BA_ "GenSigCycleTime" SG_ 330 BCC_U_Cell_SNA_Mode_045 100;
BA_ "GenSigSendType" SG_ 330 BCC_U_Cell_SNA_Mode_045 1;
BA_ "GenSigCycleTime" SG_ 330 BCC_U_Cell_SNA_Mode_044 100;
BA_ "GenSigSendType" SG_ 330 BCC_U_Cell_SNA_Mode_044 1;
BA_ "GenSigCycleTime" SG_ 330 BCC_U_Cell_SNA_Mode_043 100;
BA_ "GenSigSendType" SG_ 330 BCC_U_Cell_SNA_Mode_043 1;
BA_ "GenSigCycleTime" SG_ 330 BCC_U_Cell_SNA_Mode_042 100;
BA_ "GenSigSendType" SG_ 330 BCC_U_Cell_SNA_Mode_042 1;
BA_ "GenSigCycleTime" SG_ 330 BCC_U_Cell_SNA_Mode_041 100;
BA_ "GenSigSendType" SG_ 330 BCC_U_Cell_SNA_Mode_041 1;
BA_ "GenSigCycleTime" SG_ 330 BCC_U_Cell_SNA_Mode_040 100;
BA_ "GenSigSendType" SG_ 330 BCC_U_Cell_SNA_Mode_040 1;
BA_ "GenSigCycleTime" SG_ 330 BCC_U_Cell_SNA_Mode_039 100;
BA_ "GenSigSendType" SG_ 330 BCC_U_Cell_SNA_Mode_039 1;
BA_ "GenSigCycleTime" SG_ 330 BCC_U_Cell_SNA_Mode_038 100;
BA_ "GenSigSendType" SG_ 330 BCC_U_Cell_SNA_Mode_038 1;
BA_ "GenSigCycleTime" SG_ 330 BCC_U_Cell_SNA_Mode_037 100;
BA_ "GenSigSendType" SG_ 330 BCC_U_Cell_SNA_Mode_037 1;
BA_ "GenSigCycleTime" SG_ 330 BCC_U_Cell_SNA_Mode_036 100;
BA_ "GenSigSendType" SG_ 330 BCC_U_Cell_SNA_Mode_036 1;
BA_ "GenSigCycleTime" SG_ 330 BCC_U_Cell_SNA_Mode_035 100;
BA_ "GenSigSendType" SG_ 330 BCC_U_Cell_SNA_Mode_035 1;
BA_ "GenSigCycleTime" SG_ 330 BCC_U_Cell_SNA_Mode_034 100;
BA_ "GenSigSendType" SG_ 330 BCC_U_Cell_SNA_Mode_034 1;
BA_ "GenSigCycleTime" SG_ 330 BCC_U_Cell_SNA_Mode_033 100;
BA_ "GenSigSendType" SG_ 330 BCC_U_Cell_SNA_Mode_033 1;
BA_ "GenSigCycleTime" SG_ 330 BCC_U_Cell_SNA_Mode_032 100;
BA_ "GenSigSendType" SG_ 330 BCC_U_Cell_SNA_Mode_032 1;
BA_ "GenSigCycleTime" SG_ 330 BCC_U_Cell_SNA_Mode_031 100;
BA_ "GenSigSendType" SG_ 330 BCC_U_Cell_SNA_Mode_031 1;
BA_ "GenSigCycleTime" SG_ 330 BCC_U_Cell_SNA_Mode_030 100;
BA_ "GenSigSendType" SG_ 330 BCC_U_Cell_SNA_Mode_030 1;
BA_ "GenSigCycleTime" SG_ 330 BCC_U_Cell_SNA_Mode_029 100;
BA_ "GenSigSendType" SG_ 330 BCC_U_Cell_SNA_Mode_029 1;
BA_ "GenSigCycleTime" SG_ 330 BCC_U_Cell_SNA_Mode_028 100;
BA_ "GenSigSendType" SG_ 330 BCC_U_Cell_SNA_Mode_028 1;
BA_ "GenSigCycleTime" SG_ 330 BCC_U_Cell_SNA_Mode_027 100;
BA_ "GenSigSendType" SG_ 330 BCC_U_Cell_SNA_Mode_027 1;
BA_ "GenSigCycleTime" SG_ 330 BCC_U_Cell_SNA_Mode_026 100;
BA_ "GenSigSendType" SG_ 330 BCC_U_Cell_SNA_Mode_026 1;
BA_ "GenSigCycleTime" SG_ 330 BCC_U_Cell_SNA_Mode_025 100;
BA_ "GenSigSendType" SG_ 330 BCC_U_Cell_SNA_Mode_025 1;
BA_ "GenSigCycleTime" SG_ 330 BCC_U_Cell_SNA_Mode_024 100;
BA_ "GenSigSendType" SG_ 330 BCC_U_Cell_SNA_Mode_024 1;
BA_ "GenSigCycleTime" SG_ 330 BCC_U_Cell_SNA_Mode_023 100;
BA_ "GenSigSendType" SG_ 330 BCC_U_Cell_SNA_Mode_023 1;
BA_ "GenSigCycleTime" SG_ 330 BCC_U_Cell_SNA_Mode_022 100;
BA_ "GenSigSendType" SG_ 330 BCC_U_Cell_SNA_Mode_022 1;
BA_ "GenSigCycleTime" SG_ 330 BCC_U_Cell_SNA_Mode_021 100;
BA_ "GenSigSendType" SG_ 330 BCC_U_Cell_SNA_Mode_021 1;
BA_ "GenSigCycleTime" SG_ 330 BCC_U_Cell_SNA_Mode_020 100;
BA_ "GenSigSendType" SG_ 330 BCC_U_Cell_SNA_Mode_020 1;
BA_ "GenSigCycleTime" SG_ 330 BCC_U_Cell_SNA_Mode_019 100;
BA_ "GenSigSendType" SG_ 330 BCC_U_Cell_SNA_Mode_019 1;
BA_ "GenSigCycleTime" SG_ 330 BCC_U_Cell_SNA_Mode_018 100;
BA_ "GenSigSendType" SG_ 330 BCC_U_Cell_SNA_Mode_018 1;
BA_ "GenSigCycleTime" SG_ 330 BCC_U_Cell_SNA_Mode_017 100;
BA_ "GenSigSendType" SG_ 330 BCC_U_Cell_SNA_Mode_017 1;
BA_ "GenSigCycleTime" SG_ 330 BCC_U_Cell_SNA_Mode_016 100;
BA_ "GenSigSendType" SG_ 330 BCC_U_Cell_SNA_Mode_016 1;
BA_ "GenSigCycleTime" SG_ 330 BCC_U_Cell_SNA_Mode_015 100;
BA_ "GenSigSendType" SG_ 330 BCC_U_Cell_SNA_Mode_015 1;
BA_ "GenSigCycleTime" SG_ 330 BCC_U_Cell_SNA_Mode_014 100;
BA_ "GenSigSendType" SG_ 330 BCC_U_Cell_SNA_Mode_014 1;
BA_ "GenSigCycleTime" SG_ 330 BCC_U_Cell_SNA_Mode_013 100;
BA_ "GenSigSendType" SG_ 330 BCC_U_Cell_SNA_Mode_013 1;
BA_ "GenSigCycleTime" SG_ 330 BCC_U_Cell_SNA_Mode_012 100;
BA_ "GenSigSendType" SG_ 330 BCC_U_Cell_SNA_Mode_012 1;
BA_ "GenSigCycleTime" SG_ 330 BCC_U_Cell_SNA_Mode_011 100;
BA_ "GenSigSendType" SG_ 330 BCC_U_Cell_SNA_Mode_011 1;
BA_ "GenSigCycleTime" SG_ 330 BCC_U_Cell_SNA_Mode_010 100;
BA_ "GenSigSendType" SG_ 330 BCC_U_Cell_SNA_Mode_010 1;
BA_ "GenSigCycleTime" SG_ 330 BCC_U_Cell_SNA_Mode_009 100;
BA_ "GenSigSendType" SG_ 330 BCC_U_Cell_SNA_Mode_009 1;
BA_ "GenSigCycleTime" SG_ 330 BCC_U_Cell_SNA_Mode_008 100;
BA_ "GenSigSendType" SG_ 330 BCC_U_Cell_SNA_Mode_008 1;
BA_ "GenSigCycleTime" SG_ 330 BCC_U_Cell_SNA_Mode_007 100;
BA_ "GenSigSendType" SG_ 330 BCC_U_Cell_SNA_Mode_007 1;
BA_ "GenSigCycleTime" SG_ 330 BCC_U_Cell_SNA_Mode_006 100;
BA_ "GenSigSendType" SG_ 330 BCC_U_Cell_SNA_Mode_006 1;
BA_ "GenSigCycleTime" SG_ 330 BCC_U_Cell_SNA_Mode_005 100;
BA_ "GenSigSendType" SG_ 330 BCC_U_Cell_SNA_Mode_005 1;
BA_ "GenSigCycleTime" SG_ 330 BCC_U_Cell_SNA_Mode_004 100;
BA_ "GenSigSendType" SG_ 330 BCC_U_Cell_SNA_Mode_004 1;
BA_ "GenSigCycleTime" SG_ 330 BCC_U_Cell_SNA_Mode_003 100;
BA_ "GenSigSendType" SG_ 330 BCC_U_Cell_SNA_Mode_003 1;
BA_ "GenSigCycleTime" SG_ 330 BCC_U_Cell_SNA_Mode_002 100;
BA_ "GenSigSendType" SG_ 330 BCC_U_Cell_SNA_Mode_002 1;
BA_ "GenSigCycleTime" SG_ 330 BCC_U_Cell_SNA_Mode_001 100;
BA_ "GenSigSendType" SG_ 330 BCC_U_Cell_SNA_Mode_001 1;
BA_ "GenSigCycleTime" SG_ 564 BCASO_I_Max_DisChrg 100;
BA_ "GenSigSendType" SG_ 564 BCASO_I_Max_DisChrg 1;
BA_ "GenSigCycleTime" SG_ 564 BCASO_I_Max_Chrg 100;
BA_ "GenSigSendType" SG_ 564 BCASO_I_Max_Chrg 1;
BA_ "GenSigCycleTime" SG_ 565 BCASO_U_Min 100;
BA_ "GenSigSendType" SG_ 565 BCASO_U_Min 1;
BA_ "GenSigCycleTime" SG_ 565 BCASO_U_Max 100;
BA_ "GenSigSendType" SG_ 565 BCASO_U_Max 1;
BA_ "GenSigCycleTime" SG_ 586 BCASO_OCV_Arr21_1mV_21 100;
BA_ "GenSigSendType" SG_ 586 BCASO_OCV_Arr21_1mV_21 1;
BA_ "GenSigCycleTime" SG_ 585 BCASO_OCV_Arr21_1mV_20 100;
BA_ "GenSigSendType" SG_ 585 BCASO_OCV_Arr21_1mV_20 1;
BA_ "GenSigCycleTime" SG_ 585 BCASO_OCV_Arr21_1mV_19 100;
BA_ "GenSigSendType" SG_ 585 BCASO_OCV_Arr21_1mV_19 1;
BA_ "GenSigCycleTime" SG_ 584 BCASO_OCV_Arr21_1mV_18 100;
BA_ "GenSigSendType" SG_ 584 BCASO_OCV_Arr21_1mV_18 1;
BA_ "GenSigCycleTime" SG_ 584 BCASO_OCV_Arr21_1mV_17 100;
BA_ "GenSigSendType" SG_ 584 BCASO_OCV_Arr21_1mV_17 1;
BA_ "GenSigCycleTime" SG_ 583 BCASO_OCV_Arr21_1mV_16 100;
BA_ "GenSigSendType" SG_ 583 BCASO_OCV_Arr21_1mV_16 1;
BA_ "GenSigCycleTime" SG_ 583 BCASO_OCV_Arr21_1mV_15 100;
BA_ "GenSigSendType" SG_ 583 BCASO_OCV_Arr21_1mV_15 1;
BA_ "GenSigCycleTime" SG_ 582 BCASO_OCV_Arr21_1mV_14 100;
BA_ "GenSigSendType" SG_ 582 BCASO_OCV_Arr21_1mV_14 1;
BA_ "GenSigCycleTime" SG_ 582 BCASO_OCV_Arr21_1mV_13 100;
BA_ "GenSigSendType" SG_ 582 BCASO_OCV_Arr21_1mV_13 1;
BA_ "GenSigCycleTime" SG_ 581 BCASO_OCV_Arr21_1mV_12 100;
BA_ "GenSigSendType" SG_ 581 BCASO_OCV_Arr21_1mV_12 1;
BA_ "GenSigCycleTime" SG_ 581 BCASO_OCV_Arr21_1mV_11 100;
BA_ "GenSigSendType" SG_ 581 BCASO_OCV_Arr21_1mV_11 1;
BA_ "GenSigCycleTime" SG_ 580 BCASO_OCV_Arr21_1mV_10 100;
BA_ "GenSigSendType" SG_ 580 BCASO_OCV_Arr21_1mV_10 1;
BA_ "GenSigCycleTime" SG_ 580 BCASO_OCV_Arr21_1mV_09 100;
BA_ "GenSigSendType" SG_ 580 BCASO_OCV_Arr21_1mV_09 1;
BA_ "GenSigCycleTime" SG_ 579 BCASO_OCV_Arr21_1mV_08 100;
BA_ "GenSigSendType" SG_ 579 BCASO_OCV_Arr21_1mV_08 1;
BA_ "GenSigCycleTime" SG_ 579 BCASO_OCV_Arr21_1mV_07 100;
BA_ "GenSigSendType" SG_ 579 BCASO_OCV_Arr21_1mV_07 1;
BA_ "GenSigCycleTime" SG_ 578 BCASO_OCV_Arr21_1mV_06 100;
BA_ "GenSigSendType" SG_ 578 BCASO_OCV_Arr21_1mV_06 1;
BA_ "GenSigCycleTime" SG_ 578 BCASO_OCV_Arr21_1mV_05 100;
BA_ "GenSigSendType" SG_ 578 BCASO_OCV_Arr21_1mV_05 1;
BA_ "GenSigCycleTime" SG_ 577 BCASO_OCV_Arr21_1mV_04 100;
BA_ "GenSigSendType" SG_ 577 BCASO_OCV_Arr21_1mV_04 1;
BA_ "GenSigCycleTime" SG_ 577 BCASO_OCV_Arr21_1mV_03 100;
BA_ "GenSigSendType" SG_ 577 BCASO_OCV_Arr21_1mV_03 1;
BA_ "GenSigCycleTime" SG_ 576 BCASO_OCV_Arr21_1mV_02 100;
BA_ "GenSigSendType" SG_ 576 BCASO_OCV_Arr21_1mV_02 1;
BA_ "GenSigCycleTime" SG_ 576 BCASO_OCV_Arr21_1mV_01 100;
BA_ "GenSigSendType" SG_ 576 BCASO_OCV_Arr21_1mV_01 1;
BA_ "GenSigCycleTime" SG_ 566 BCASO_U_Dchrg_long 100;
BA_ "GenSigSendType" SG_ 566 BCASO_U_Dchrg_long 1;
BA_ "GenSigCycleTime" SG_ 566 BCASO_I_Dchrg_long 100;
BA_ "GenSigStartValue" SG_ 566 BCASO_I_Dchrg_long 8192;
BA_ "GenSigSendType" SG_ 566 BCASO_I_Dchrg_long 1;
BA_ "GenSigCycleTime" SG_ 566 BCASO_U_Chrg_long 100;
BA_ "GenSigSendType" SG_ 566 BCASO_U_Chrg_long 1;
BA_ "GenSigCycleTime" SG_ 566 BCASO_I_Chrg_long 100;
BA_ "GenSigStartValue" SG_ 566 BCASO_I_Chrg_long 8192;
BA_ "GenSigSendType" SG_ 566 BCASO_I_Chrg_long 1;
BA_ "GenSigCycleTime" SG_ 567 BCASO_U_Dchrg_short 100;
BA_ "GenSigSendType" SG_ 567 BCASO_U_Dchrg_short 1;
BA_ "GenSigCycleTime" SG_ 567 BCASO_I_Dchrg_short 100;
BA_ "GenSigStartValue" SG_ 567 BCASO_I_Dchrg_short 8192;
BA_ "GenSigSendType" SG_ 567 BCASO_I_Dchrg_short 1;
BA_ "GenSigCycleTime" SG_ 567 BCASO_U_Chrg_short 100;
BA_ "GenSigSendType" SG_ 567 BCASO_U_Chrg_short 1;
BA_ "GenSigCycleTime" SG_ 567 BCASO_I_Chrg_short 100;
BA_ "GenSigStartValue" SG_ 567 BCASO_I_Chrg_short 8192;
BA_ "GenSigSendType" SG_ 567 BCASO_I_Chrg_short 1;
BA_ "GenSigCycleTime" SG_ 657 BCASO_Balacing_Stat_11 100;
BA_ "GenSigSendType" SG_ 657 BCASO_Balacing_Stat_11 1;
BA_ "GenSigCycleTime" SG_ 657 BCASO_Balacing_Stat_10 100;
BA_ "GenSigSendType" SG_ 657 BCASO_Balacing_Stat_10 1;
BA_ "GenSigCycleTime" SG_ 657 BCASO_Balacing_Stat_09 100;
BA_ "GenSigSendType" SG_ 657 BCASO_Balacing_Stat_09 1;
BA_ "GenSigCycleTime" SG_ 656 BCASO_Balacing_Stat_08 100;
BA_ "GenSigSendType" SG_ 656 BCASO_Balacing_Stat_08 1;
BA_ "GenSigCycleTime" SG_ 656 BCASO_Balacing_Stat_07 100;
BA_ "GenSigSendType" SG_ 656 BCASO_Balacing_Stat_07 1;
BA_ "GenSigCycleTime" SG_ 656 BCASO_Balacing_Stat_06 100;
BA_ "GenSigSendType" SG_ 656 BCASO_Balacing_Stat_06 1;
BA_ "GenSigCycleTime" SG_ 656 BCASO_Balacing_Stat_05 100;
BA_ "GenSigSendType" SG_ 656 BCASO_Balacing_Stat_05 1;
BA_ "GenSigCycleTime" SG_ 656 BCASO_Balacing_Stat_04 100;
BA_ "GenSigSendType" SG_ 656 BCASO_Balacing_Stat_04 1;
BA_ "GenSigCycleTime" SG_ 656 BCASO_Balacing_Stat_03 100;
BA_ "GenSigSendType" SG_ 656 BCASO_Balacing_Stat_03 1;
BA_ "GenSigCycleTime" SG_ 656 BCASO_Balacing_Stat_02 100;
BA_ "GenSigSendType" SG_ 656 BCASO_Balacing_Stat_02 1;
BA_ "GenSigCycleTime" SG_ 656 BCASO_Balacing_Stat_01 100;
BA_ "GenSigSendType" SG_ 656 BCASO_Balacing_Stat_01 1;
BA_ "GenSigCycleTime" SG_ 593 BCASO_Cell_Bal_Req_100 100;
BA_ "GenSigSendType" SG_ 593 BCASO_Cell_Bal_Req_100 1;
BA_ "GenSigCycleTime" SG_ 593 BCASO_Cell_Bal_Req_099 100;
BA_ "GenSigSendType" SG_ 593 BCASO_Cell_Bal_Req_099 1;
BA_ "GenSigCycleTime" SG_ 593 BCASO_Cell_Bal_Req_098 100;
BA_ "GenSigSendType" SG_ 593 BCASO_Cell_Bal_Req_098 1;
BA_ "GenSigCycleTime" SG_ 593 BCASO_Cell_Bal_Req_097 100;
BA_ "GenSigSendType" SG_ 593 BCASO_Cell_Bal_Req_097 1;
BA_ "GenSigCycleTime" SG_ 593 BCASO_Cell_Bal_Req_096 100;
BA_ "GenSigSendType" SG_ 593 BCASO_Cell_Bal_Req_096 1;
BA_ "GenSigCycleTime" SG_ 593 BCASO_Cell_Bal_Req_095 100;
BA_ "GenSigSendType" SG_ 593 BCASO_Cell_Bal_Req_095 1;
BA_ "GenSigCycleTime" SG_ 593 BCASO_Cell_Bal_Req_094 100;
BA_ "GenSigSendType" SG_ 593 BCASO_Cell_Bal_Req_094 1;
BA_ "GenSigCycleTime" SG_ 593 BCASO_Cell_Bal_Req_093 100;
BA_ "GenSigSendType" SG_ 593 BCASO_Cell_Bal_Req_093 1;
BA_ "GenSigCycleTime" SG_ 593 BCASO_Cell_Bal_Req_092 100;
BA_ "GenSigSendType" SG_ 593 BCASO_Cell_Bal_Req_092 1;
BA_ "GenSigCycleTime" SG_ 593 BCASO_Cell_Bal_Req_091 100;
BA_ "GenSigSendType" SG_ 593 BCASO_Cell_Bal_Req_091 1;
BA_ "GenSigCycleTime" SG_ 593 BCASO_Cell_Bal_Req_090 100;
BA_ "GenSigSendType" SG_ 593 BCASO_Cell_Bal_Req_090 1;
BA_ "GenSigCycleTime" SG_ 593 BCASO_Cell_Bal_Req_089 100;
BA_ "GenSigSendType" SG_ 593 BCASO_Cell_Bal_Req_089 1;
BA_ "GenSigCycleTime" SG_ 593 BCASO_Cell_Bal_Req_088 100;
BA_ "GenSigSendType" SG_ 593 BCASO_Cell_Bal_Req_088 1;
BA_ "GenSigCycleTime" SG_ 593 BCASO_Cell_Bal_Req_087 100;
BA_ "GenSigSendType" SG_ 593 BCASO_Cell_Bal_Req_087 1;
BA_ "GenSigCycleTime" SG_ 593 BCASO_Cell_Bal_Req_086 100;
BA_ "GenSigSendType" SG_ 593 BCASO_Cell_Bal_Req_086 1;
BA_ "GenSigCycleTime" SG_ 593 BCASO_Cell_Bal_Req_085 100;
BA_ "GenSigSendType" SG_ 593 BCASO_Cell_Bal_Req_085 1;
BA_ "GenSigCycleTime" SG_ 593 BCASO_Cell_Bal_Req_084 100;
BA_ "GenSigSendType" SG_ 593 BCASO_Cell_Bal_Req_084 1;
BA_ "GenSigCycleTime" SG_ 593 BCASO_Cell_Bal_Req_083 100;
BA_ "GenSigSendType" SG_ 593 BCASO_Cell_Bal_Req_083 1;
BA_ "GenSigCycleTime" SG_ 593 BCASO_Cell_Bal_Req_082 100;
BA_ "GenSigSendType" SG_ 593 BCASO_Cell_Bal_Req_082 1;
BA_ "GenSigCycleTime" SG_ 593 BCASO_Cell_Bal_Req_081 100;
BA_ "GenSigSendType" SG_ 593 BCASO_Cell_Bal_Req_081 1;
BA_ "GenSigCycleTime" SG_ 593 BCASO_Cell_Bal_Req_080 100;
BA_ "GenSigSendType" SG_ 593 BCASO_Cell_Bal_Req_080 1;
BA_ "GenSigCycleTime" SG_ 593 BCASO_Cell_Bal_Req_079 100;
BA_ "GenSigSendType" SG_ 593 BCASO_Cell_Bal_Req_079 1;
BA_ "GenSigCycleTime" SG_ 593 BCASO_Cell_Bal_Req_078 100;
BA_ "GenSigSendType" SG_ 593 BCASO_Cell_Bal_Req_078 1;
BA_ "GenSigCycleTime" SG_ 593 BCASO_Cell_Bal_Req_077 100;
BA_ "GenSigSendType" SG_ 593 BCASO_Cell_Bal_Req_077 1;
BA_ "GenSigCycleTime" SG_ 593 BCASO_Cell_Bal_Req_076 100;
BA_ "GenSigSendType" SG_ 593 BCASO_Cell_Bal_Req_076 1;
BA_ "GenSigCycleTime" SG_ 593 BCASO_Cell_Bal_Req_075 100;
BA_ "GenSigSendType" SG_ 593 BCASO_Cell_Bal_Req_075 1;
BA_ "GenSigCycleTime" SG_ 593 BCASO_Cell_Bal_Req_074 100;
BA_ "GenSigSendType" SG_ 593 BCASO_Cell_Bal_Req_074 1;
BA_ "GenSigCycleTime" SG_ 593 BCASO_Cell_Bal_Req_073 100;
BA_ "GenSigSendType" SG_ 593 BCASO_Cell_Bal_Req_073 1;
BA_ "GenSigCycleTime" SG_ 593 BCASO_Cell_Bal_Req_072 100;
BA_ "GenSigSendType" SG_ 593 BCASO_Cell_Bal_Req_072 1;
BA_ "GenSigCycleTime" SG_ 593 BCASO_Cell_Bal_Req_071 100;
BA_ "GenSigSendType" SG_ 593 BCASO_Cell_Bal_Req_071 1;
BA_ "GenSigCycleTime" SG_ 593 BCASO_Cell_Bal_Req_070 100;
BA_ "GenSigSendType" SG_ 593 BCASO_Cell_Bal_Req_070 1;
BA_ "GenSigCycleTime" SG_ 593 BCASO_Cell_Bal_Req_069 100;
BA_ "GenSigSendType" SG_ 593 BCASO_Cell_Bal_Req_069 1;
BA_ "GenSigCycleTime" SG_ 593 BCASO_Cell_Bal_Req_068 100;
BA_ "GenSigSendType" SG_ 593 BCASO_Cell_Bal_Req_068 1;
BA_ "GenSigCycleTime" SG_ 593 BCASO_Cell_Bal_Req_067 100;
BA_ "GenSigSendType" SG_ 593 BCASO_Cell_Bal_Req_067 1;
BA_ "GenSigCycleTime" SG_ 593 BCASO_Cell_Bal_Req_066 100;
BA_ "GenSigSendType" SG_ 593 BCASO_Cell_Bal_Req_066 1;
BA_ "GenSigCycleTime" SG_ 593 BCASO_Cell_Bal_Req_065 100;
BA_ "GenSigSendType" SG_ 593 BCASO_Cell_Bal_Req_065 1;
BA_ "GenSigCycleTime" SG_ 592 BCASO_Cell_Bal_Req_064 100;
BA_ "GenSigSendType" SG_ 592 BCASO_Cell_Bal_Req_064 1;
BA_ "GenSigCycleTime" SG_ 592 BCASO_Cell_Bal_Req_063 100;
BA_ "GenSigSendType" SG_ 592 BCASO_Cell_Bal_Req_063 1;
BA_ "GenSigCycleTime" SG_ 592 BCASO_Cell_Bal_Req_062 100;
BA_ "GenSigSendType" SG_ 592 BCASO_Cell_Bal_Req_062 1;
BA_ "GenSigCycleTime" SG_ 592 BCASO_Cell_Bal_Req_061 100;
BA_ "GenSigSendType" SG_ 592 BCASO_Cell_Bal_Req_061 1;
BA_ "GenSigCycleTime" SG_ 592 BCASO_Cell_Bal_Req_060 100;
BA_ "GenSigSendType" SG_ 592 BCASO_Cell_Bal_Req_060 1;
BA_ "GenSigCycleTime" SG_ 592 BCASO_Cell_Bal_Req_059 100;
BA_ "GenSigSendType" SG_ 592 BCASO_Cell_Bal_Req_059 1;
BA_ "GenSigCycleTime" SG_ 592 BCASO_Cell_Bal_Req_058 100;
BA_ "GenSigSendType" SG_ 592 BCASO_Cell_Bal_Req_058 1;
BA_ "GenSigCycleTime" SG_ 592 BCASO_Cell_Bal_Req_057 100;
BA_ "GenSigSendType" SG_ 592 BCASO_Cell_Bal_Req_057 1;
BA_ "GenSigCycleTime" SG_ 592 BCASO_Cell_Bal_Req_056 100;
BA_ "GenSigSendType" SG_ 592 BCASO_Cell_Bal_Req_056 1;
BA_ "GenSigCycleTime" SG_ 592 BCASO_Cell_Bal_Req_055 100;
BA_ "GenSigSendType" SG_ 592 BCASO_Cell_Bal_Req_055 1;
BA_ "GenSigCycleTime" SG_ 592 BCASO_Cell_Bal_Req_054 100;
BA_ "GenSigSendType" SG_ 592 BCASO_Cell_Bal_Req_054 1;
BA_ "GenSigCycleTime" SG_ 592 BCASO_Cell_Bal_Req_053 100;
BA_ "GenSigSendType" SG_ 592 BCASO_Cell_Bal_Req_053 1;
BA_ "GenSigCycleTime" SG_ 592 BCASO_Cell_Bal_Req_052 100;
BA_ "GenSigSendType" SG_ 592 BCASO_Cell_Bal_Req_052 1;
BA_ "GenSigCycleTime" SG_ 592 BCASO_Cell_Bal_Req_051 100;
BA_ "GenSigSendType" SG_ 592 BCASO_Cell_Bal_Req_051 1;
BA_ "GenSigCycleTime" SG_ 592 BCASO_Cell_Bal_Req_050 100;
BA_ "GenSigSendType" SG_ 592 BCASO_Cell_Bal_Req_050 1;
BA_ "GenSigCycleTime" SG_ 592 BCASO_Cell_Bal_Req_049 100;
BA_ "GenSigSendType" SG_ 592 BCASO_Cell_Bal_Req_049 1;
BA_ "GenSigCycleTime" SG_ 592 BCASO_Cell_Bal_Req_048 100;
BA_ "GenSigSendType" SG_ 592 BCASO_Cell_Bal_Req_048 1;
BA_ "GenSigCycleTime" SG_ 592 BCASO_Cell_Bal_Req_047 100;
BA_ "GenSigSendType" SG_ 592 BCASO_Cell_Bal_Req_047 1;
BA_ "GenSigCycleTime" SG_ 592 BCASO_Cell_Bal_Req_046 100;
BA_ "GenSigSendType" SG_ 592 BCASO_Cell_Bal_Req_046 1;
BA_ "GenSigCycleTime" SG_ 592 BCASO_Cell_Bal_Req_045 100;
BA_ "GenSigSendType" SG_ 592 BCASO_Cell_Bal_Req_045 1;
BA_ "GenSigCycleTime" SG_ 592 BCASO_Cell_Bal_Req_044 100;
BA_ "GenSigSendType" SG_ 592 BCASO_Cell_Bal_Req_044 1;
BA_ "GenSigCycleTime" SG_ 592 BCASO_Cell_Bal_Req_043 100;
BA_ "GenSigSendType" SG_ 592 BCASO_Cell_Bal_Req_043 1;
BA_ "GenSigCycleTime" SG_ 592 BCASO_Cell_Bal_Req_042 100;
BA_ "GenSigSendType" SG_ 592 BCASO_Cell_Bal_Req_042 1;
BA_ "GenSigCycleTime" SG_ 592 BCASO_Cell_Bal_Req_041 100;
BA_ "GenSigSendType" SG_ 592 BCASO_Cell_Bal_Req_041 1;
BA_ "GenSigCycleTime" SG_ 592 BCASO_Cell_Bal_Req_040 100;
BA_ "GenSigSendType" SG_ 592 BCASO_Cell_Bal_Req_040 1;
BA_ "GenSigCycleTime" SG_ 592 BCASO_Cell_Bal_Req_039 100;
BA_ "GenSigSendType" SG_ 592 BCASO_Cell_Bal_Req_039 1;
BA_ "GenSigCycleTime" SG_ 592 BCASO_Cell_Bal_Req_038 100;
BA_ "GenSigSendType" SG_ 592 BCASO_Cell_Bal_Req_038 1;
BA_ "GenSigCycleTime" SG_ 592 BCASO_Cell_Bal_Req_037 100;
BA_ "GenSigSendType" SG_ 592 BCASO_Cell_Bal_Req_037 1;
BA_ "GenSigCycleTime" SG_ 592 BCASO_Cell_Bal_Req_036 100;
BA_ "GenSigSendType" SG_ 592 BCASO_Cell_Bal_Req_036 1;
BA_ "GenSigCycleTime" SG_ 592 BCASO_Cell_Bal_Req_035 100;
BA_ "GenSigSendType" SG_ 592 BCASO_Cell_Bal_Req_035 1;
BA_ "GenSigCycleTime" SG_ 592 BCASO_Cell_Bal_Req_034 100;
BA_ "GenSigSendType" SG_ 592 BCASO_Cell_Bal_Req_034 1;
BA_ "GenSigCycleTime" SG_ 592 BCASO_Cell_Bal_Req_033 100;
BA_ "GenSigSendType" SG_ 592 BCASO_Cell_Bal_Req_033 1;
BA_ "GenSigCycleTime" SG_ 592 BCASO_Cell_Bal_Req_032 100;
BA_ "GenSigSendType" SG_ 592 BCASO_Cell_Bal_Req_032 1;
BA_ "GenSigCycleTime" SG_ 592 BCASO_Cell_Bal_Req_031 100;
BA_ "GenSigSendType" SG_ 592 BCASO_Cell_Bal_Req_031 1;
BA_ "GenSigCycleTime" SG_ 592 BCASO_Cell_Bal_Req_030 100;
BA_ "GenSigSendType" SG_ 592 BCASO_Cell_Bal_Req_030 1;
BA_ "GenSigCycleTime" SG_ 592 BCASO_Cell_Bal_Req_029 100;
BA_ "GenSigSendType" SG_ 592 BCASO_Cell_Bal_Req_029 1;
BA_ "GenSigCycleTime" SG_ 592 BCASO_Cell_Bal_Req_028 100;
BA_ "GenSigSendType" SG_ 592 BCASO_Cell_Bal_Req_028 1;
BA_ "GenSigCycleTime" SG_ 592 BCASO_Cell_Bal_Req_027 100;
BA_ "GenSigSendType" SG_ 592 BCASO_Cell_Bal_Req_027 1;
BA_ "GenSigCycleTime" SG_ 592 BCASO_Cell_Bal_Req_026 100;
BA_ "GenSigSendType" SG_ 592 BCASO_Cell_Bal_Req_026 1;
BA_ "GenSigCycleTime" SG_ 592 BCASO_Cell_Bal_Req_025 100;
BA_ "GenSigSendType" SG_ 592 BCASO_Cell_Bal_Req_025 1;
BA_ "GenSigCycleTime" SG_ 592 BCASO_Cell_Bal_Req_024 100;
BA_ "GenSigSendType" SG_ 592 BCASO_Cell_Bal_Req_024 1;
BA_ "GenSigCycleTime" SG_ 592 BCASO_Cell_Bal_Req_023 100;
BA_ "GenSigSendType" SG_ 592 BCASO_Cell_Bal_Req_023 1;
BA_ "GenSigCycleTime" SG_ 592 BCASO_Cell_Bal_Req_022 100;
BA_ "GenSigSendType" SG_ 592 BCASO_Cell_Bal_Req_022 1;
BA_ "GenSigCycleTime" SG_ 592 BCASO_Cell_Bal_Req_021 100;
BA_ "GenSigSendType" SG_ 592 BCASO_Cell_Bal_Req_021 1;
BA_ "GenSigCycleTime" SG_ 592 BCASO_Cell_Bal_Req_020 100;
BA_ "GenSigSendType" SG_ 592 BCASO_Cell_Bal_Req_020 1;
BA_ "GenSigCycleTime" SG_ 592 BCASO_Cell_Bal_Req_019 100;
BA_ "GenSigSendType" SG_ 592 BCASO_Cell_Bal_Req_019 1;
BA_ "GenSigCycleTime" SG_ 592 BCASO_Cell_Bal_Req_018 100;
BA_ "GenSigSendType" SG_ 592 BCASO_Cell_Bal_Req_018 1;
BA_ "GenSigCycleTime" SG_ 592 BCASO_Cell_Bal_Req_017 100;
BA_ "GenSigSendType" SG_ 592 BCASO_Cell_Bal_Req_017 1;
BA_ "GenSigCycleTime" SG_ 592 BCASO_Cell_Bal_Req_016 100;
BA_ "GenSigSendType" SG_ 592 BCASO_Cell_Bal_Req_016 1;
BA_ "GenSigCycleTime" SG_ 592 BCASO_Cell_Bal_Req_015 100;
BA_ "GenSigSendType" SG_ 592 BCASO_Cell_Bal_Req_015 1;
BA_ "GenSigCycleTime" SG_ 592 BCASO_Cell_Bal_Req_014 100;
BA_ "GenSigSendType" SG_ 592 BCASO_Cell_Bal_Req_014 1;
BA_ "GenSigCycleTime" SG_ 592 BCASO_Cell_Bal_Req_013 100;
BA_ "GenSigSendType" SG_ 592 BCASO_Cell_Bal_Req_013 1;
BA_ "GenSigCycleTime" SG_ 592 BCASO_Cell_Bal_Req_012 100;
BA_ "GenSigSendType" SG_ 592 BCASO_Cell_Bal_Req_012 1;
BA_ "GenSigCycleTime" SG_ 592 BCASO_Cell_Bal_Req_011 100;
BA_ "GenSigSendType" SG_ 592 BCASO_Cell_Bal_Req_011 1;
BA_ "GenSigCycleTime" SG_ 592 BCASO_Cell_Bal_Req_010 100;
BA_ "GenSigSendType" SG_ 592 BCASO_Cell_Bal_Req_010 1;
BA_ "GenSigCycleTime" SG_ 592 BCASO_Cell_Bal_Req_009 100;
BA_ "GenSigSendType" SG_ 592 BCASO_Cell_Bal_Req_009 1;
BA_ "GenSigCycleTime" SG_ 592 BCASO_Cell_Bal_Req_008 100;
BA_ "GenSigSendType" SG_ 592 BCASO_Cell_Bal_Req_008 1;
BA_ "GenSigCycleTime" SG_ 592 BCASO_Cell_Bal_Req_007 100;
BA_ "GenSigSendType" SG_ 592 BCASO_Cell_Bal_Req_007 1;
BA_ "GenSigCycleTime" SG_ 592 BCASO_Cell_Bal_Req_006 100;
BA_ "GenSigSendType" SG_ 592 BCASO_Cell_Bal_Req_006 1;
BA_ "GenSigCycleTime" SG_ 592 BCASO_Cell_Bal_Req_005 100;
BA_ "GenSigSendType" SG_ 592 BCASO_Cell_Bal_Req_005 1;
BA_ "GenSigCycleTime" SG_ 592 BCASO_Cell_Bal_Req_004 100;
BA_ "GenSigSendType" SG_ 592 BCASO_Cell_Bal_Req_004 1;
BA_ "GenSigCycleTime" SG_ 592 BCASO_Cell_Bal_Req_003 100;
BA_ "GenSigSendType" SG_ 592 BCASO_Cell_Bal_Req_003 1;
BA_ "GenSigCycleTime" SG_ 592 BCASO_Cell_Bal_Req_002 100;
BA_ "GenSigSendType" SG_ 592 BCASO_Cell_Bal_Req_002 1;
BA_ "GenSigCycleTime" SG_ 592 BCASO_Cell_Bal_Req_001 100;
BA_ "GenSigSendType" SG_ 592 BCASO_Cell_Bal_Req_001 1;
VAL_ 16 BULIM_Batt_Umin_Deviation_Error 2 "STORED" 1 "ACTIVE" 0 "NOT_ACTIVE" ;
VAL_ 16 BULIM_Batt_Umax_Deviation_Error 2 "STORED" 1 "ACTIVE" 0 "NOT_ACTIVE" ;
VAL_ 16 BSOC_SOC_UltraLow_Error 2 "STORED" 1 "ACTIVE" 0 "NOT_ACTIVE" ;
VAL_ 16 BSOC_SOC_UltraHigh_Error 2 "STORED" 1 "ACTIVE" 0 "NOT_ACTIVE" ;
VAL_ 16 BSOC_SOC_Low_Error 2 "STORED" 1 "ACTIVE" 0 "NOT_ACTIVE" ;
VAL_ 16 BSOC_SOC_High_Error 2 "STORED" 1 "ACTIVE" 0 "NOT_ACTIVE" ;
VAL_ 16 BSOC_OCV_Cell_Diff_High_Error 2 "STORED" 1 "ACTIVE" 0 "NOT_ACTIVE" ;
VAL_ 16 BILIM_I_DisChrg_Error 2 "STORED" 1 "ACTIVE" 0 "NOT_ACTIVE" ;
VAL_ 16 BILIM_I_Chrg_Error 2 "STORED" 1 "ACTIVE" 0 "NOT_ACTIVE" ;
VAL_ 16 BCOOL_Temp_UltraHigh_Error 2 "STORED" 1 "ACTIVE" 0 "NOT_ACTIVE" ;
VAL_ 16 BCOOL_Temp_High_Error 2 "STORED" 1 "ACTIVE" 0 "NOT_ACTIVE" ;
VAL_ 16 BBALU_Cell_Error 2 "STORED" 1 "ACTIVE" 0 "NOT_ACTIVE" ;
VAL_ 661 SW_Wakeup_by_RTC 1 "TRUE" 0 "FALSE" ;
VAL_ 661 SW_OP_Mode 2 "Shutdown" 1 "Operational Mode" ;
SIG_GROUP_ 539 GR_SAC_ERRORS 1 : SAC_E_CELL_Over_Voltage SAC_E_CELL_Under_Voltage SAC_E_CSC_Warning SAC_E_SSV_Timeout SAC_E_Iso_resistance SAC_E_ACC_Emergency SAC_E_FLOW_CTR SAC_E_CSC_Emergency SAC_E_PMB_Emergency SAC_E_Interlock_missing SAC_E_PMB_Timeout SAC_E_SSV_Interop SAC_E_Iso_measurement SAC_E_PCB_Temperature SAC_E_PMB_Limits SAC_E_NVRAM SAC_E_Lifedata SAC_E_HV_meas SAC_E_Trac_Voltage SAC_E_WD SAC_E_CPU_Test SAC_E_Reset_Monitor SAC_E_ROM_Monitor SAC_E_RAM_Monitor SAC_E_STACK_Monitor SAC_E_PMB_Warning SAC_E_SSV_CONFIG_HARD SAC_E_CSC_Emergency_short_sup SAC_E_BCC_communication SAC_E_Supply_Voltage SAC_E_Ref_Voltage SAC_E_SSV_Emergency SAC_E_SSV_Warning SAC_E_PMB_Emergency_short_sup SAC_E_FLASH_Monitor SAC_E_SSV_Supply_Voltage SAC_E_SSV_WD SAC_E_PMB_Internal SAC_E_MSW_AGE SAC_E_PMB_Over_Temperature_Shun SAC_E_PMB_Over_Current_charge SAC_E_PMB_Over_Current_discharg SAC_E_BAT_Over_Voltage SAC_E_CSC_Internal SAC_E_CSC_Timeout SAC_E_CELL_Over_Temperature SAC_E_MSW_AGE_WARN;
SIG_GROUP_ 309 GR_BCC_IN_T_BATT_05_06 1 : BCC_T_Batt_06 BCC_T_Batt_05;
SIG_GROUP_ 308 GR_BCC_IN_T_BATT_03_04 1 : BCC_T_Batt_04 BCC_T_Batt_03;
SIG_GROUP_ 307 GR_BCC_IN_T_BATT_01_02 1 : BCC_T_Batt_02 BCC_T_Batt_01;
SIG_GROUP_ 16 GR_BCC_ERRORS 1 : BIW_v_Dbg_TxVariable01 BIW_v_Dbg_TxVariable02 BIW_v_Dbg_TxVariable03 BIW_v_Dbg_TxVariable04 BBALU_Cell_Error BCOOL_Temp_High_Error BCOOL_Temp_UltraHigh_Error BILIM_I_Chrg_Error BILIM_I_DisChrg_Error BSOC_OCV_Cell_Diff_High_Error BSOC_SOC_High_Error BSOC_SOC_Low_Error BSOC_SOC_UltraHigh_Error BSOC_SOC_UltraLow_Error BULIM_Batt_Umax_Deviation_Error BULIM_Batt_Umin_Deviation_Error;
SIG_GROUP_ 547 GR_SAC_STATES 1 : SAC_S_RTC_LOW_VOLT SAC_S_SOFTWARE_RESET_PERFORMED SAC_S_ISO_GND_WARNING SAC_S_DISCHARGE_COMPLETED SAC_S_DISCHARGE SAC_S_PMB_CAN_ACTIVE SAC_S_CSC_CAN_ACTIVE SAC_S_CAN_WAKEUP SAC_S_CLOSE_NOT_POSSIBLE_WEAK SAC_S_SC_MSW_3_CLOSE SAC_S_ISO_TEST_ACTIVE SAC_S_SC_PMB_EN SAC_S_SC_CSC_EN SAC_S_HV_EN SAC_S_MEAS_CAN_WARN SAC_S_CSC_RESET SAC_S_CSC_SYNC SAC_S_PMB_RESET SAC_S_PMB_SYNC SAC_S_SC_KL30c_EN SAC_S_RTC_WAKEUP_DETECTED SAC_S_RTC_WAKEUP_DELAY_SET SAC_S_RTC_READY SAC_S_ISO_VALUE_VALID SAC_S_ISO_EN SAC_S_PRECH_COMPLETED SAC_S_PREC_ACTIVE SAC_S_COOLING SAC_S_STUCKTEST_READY SAC_S_SKT_CONDITIONS SAC_S_MSW_SUPPLY SAC_S_ISO_RES_WARNING SAC_S_SC_MSW_PLUS_CLOSE SAC_S_SC_MSW_MINUS_CLOSE SAC_S_MONITORING SAC_S_SYS_ENABLE SAC_S_START_UP_TEST SAC_S_EMERGENCY_OPEN SAC_S_GENERAL_ERROR;
SIG_GROUP_ 540 GR_SAC_IDENT 1 : SAC_Version_DS_CRC SAC_Version_Major SAC_Version_Minor SAC_Version_Release;
SIG_GROUP_ 1795 GR_BMC_BSW_IDENT 1 : BMC_BSW_Version_Major BMC_BSW_Version_Minor BMC_BSW_Version_Release BMC_BSW_DS_CRC;
SIG_GROUP_ 1793 GR_BMC_DATA_01 1 : BMC_KL30C_Voltage BMC_KL30_Voltage Iso_Meas_Error Iso_Res Iso_Res_Error Iso_Res_Warning Iso_Value_Valid Iso_Test_Active Iso_Meas_res;
SIG_GROUP_ 609 GR_BCC_OUT_IDENT_01 1 : AV_BCC_Version AV_BCC_HW_Id AV_BCC_Project_Id;
SIG_GROUP_ 661 GR_BCC_SW_MODE_INF 1 : SW_OP_Mode SW_Wakeup_by_RTC;
SIG_GROUP_ 276 GR_BCC_IN_MODES_CONFIGS 1 : BCC_Continuous_Mode BCC_Cyclic_Mode BCC_EEPROM_Mode BCC_EM_Volt_Derate_Mode BCC_KL15 BCC_KL50 BCC_NoCurr_Req BCC_NV_Data_SNA_Mode BCC_Recalibrate_Mode BCC_Reset_U_Limit_Req BCC_Number_of_Cells BCC_Number_of_Temperatures;
SIG_GROUP_ 299 GR_BCC_IN_DIAG_VARIOUS 1 : BCC_Balancing_Mode BCC_Diag_Capa_Mode BCC_Diag_OCV_Mode BCC_Balancing_U_Target BCC_Diag_Capa_As_1;
SIG_GROUP_ 277 GR_BCC_IN_OBL 1 : BCC_OBL_BMS_Wakeup_SNA_Mode BCC_OBL_BMS_Wakeup_State BCC_OBL_HVDC_Current_SNA_Mode BCC_OBL_HVDC_Voltage_SNA_Mode BCC_OBL_HVDC_Current BCC_OBL_HVDC_Voltage;
SIG_GROUP_ 278 GR_BCC_IN_RTC 1 : BCC_RTC_SNA_Mode BCC_RTC;
SIG_GROUP_ 282 GR_BCC_IN_I_BATT_02 1 : BCC_I_Batt_Filter_SNA_Mode BCC_I_Batt_SNA_Mode BCC_Ibatt_Substitute_Mode BCC_Ibatt_Substitute_Value;
SIG_GROUP_ 281 GR_BCC_IN_I_BATT_01 1 : BCC_I_Batt BCC_I_Batt_Filtered;
SIG_GROUP_ 280 GR_BCC_IN_U_BATT 1 : BCC_U_Batt_SNA_Mode BCC_Ubatt_Substitute_Mode BCC_U_Batt BCC_Ubatt_Substitute_Value;
SIG_GROUP_ 305 GR_BCC_IN_T_COOL_AMB 1 : BCC_T_Cool_SNA_Mode BCC_T_Amb BCC_T_Cool;
SIG_GROUP_ 385 GR_BCC_IN_COOL_02 1 : BCC_FanRelay_Cmd BCC_FanReq_Mode BCC_FanRelay_Mode BCC_SwitchingValve_Cmd BCC_SwitchingValve_Mode BCC_FanStage_State BCC_SwitchingValveStage_State;
SIG_GROUP_ 384 GR_BCC_IN_COOL_01 1 : BCC_AC_Cool_Mode BCC_BMS_CoolVlv_Mode BCC_ChillerValve_Cmd BCC_ChillerValve_En_Mode BCC_ChillerValve_Mode BCC_CoolantPump_Mode BCC_CoolCirc_Actv_Mode BCC_ChillerValveStage_State BCC_CoolantPump_Cmd BCC_CoolantPump_State BCC_CoolingCircuit_State BCC_CoolingComp_State;
SIG_GROUP_ 298 GR_BCC_IN_DIAG_OCV_21 1 : BCC_Diag_OCV_Arr21_1mV_21;
SIG_GROUP_ 297 GR_BCC_IN_DIAG_OCV_19_20 1 : BCC_Diag_OCV_Arr21_1mV_19 BCC_Diag_OCV_Arr21_1mV_20;
SIG_GROUP_ 296 GR_BCC_IN_DIAG_OCV_17_18 1 : BCC_Diag_OCV_Arr21_1mV_17 BCC_Diag_OCV_Arr21_1mV_18;
SIG_GROUP_ 295 GR_BCC_IN_DIAG_OCV_15_16 1 : BCC_Diag_OCV_Arr21_1mV_15 BCC_Diag_OCV_Arr21_1mV_16;
SIG_GROUP_ 294 GR_BCC_IN_DIAG_OCV_13_14 1 : BCC_Diag_OCV_Arr21_1mV_13 BCC_Diag_OCV_Arr21_1mV_14;
SIG_GROUP_ 293 GR_BCC_IN_DIAG_OCV_11_12 1 : BCC_Diag_OCV_Arr21_1mV_11 BCC_Diag_OCV_Arr21_1mV_12;
SIG_GROUP_ 292 GR_BCC_IN_DIAG_OCV_09_10 1 : BCC_Diag_OCV_Arr21_1mV_09 BCC_Diag_OCV_Arr21_1mV_10;
SIG_GROUP_ 291 GR_BCC_IN_DIAG_OCV_07_08 1 : BCC_Diag_OCV_Arr21_1mV_07 BCC_Diag_OCV_Arr21_1mV_08;
SIG_GROUP_ 290 GR_BCC_IN_DIAG_OCV_05_06 1 : BCC_Diag_OCV_Arr21_1mV_05 BCC_Diag_OCV_Arr21_1mV_06;
SIG_GROUP_ 289 GR_BCC_IN_DIAG_OCV_03_04 1 : BCC_Diag_OCV_Arr21_1mV_03 BCC_Diag_OCV_Arr21_1mV_04;
SIG_GROUP_ 288 GR_BCC_IN_DIAG_OCV_01_02 1 : BCC_Diag_OCV_Arr21_1mV_01 BCC_Diag_OCV_Arr21_1mV_02;
SIG_GROUP_ 331 GR_BCC_IN_U_CELL_SNA_065_128 1 : BCC_U_Cell_SNA_Mode_100 BCC_U_Cell_SNA_Mode_099 BCC_U_Cell_SNA_Mode_098 BCC_U_Cell_SNA_Mode_097 BCC_U_Cell_SNA_Mode_096 BCC_U_Cell_SNA_Mode_095 BCC_U_Cell_SNA_Mode_094 BCC_U_Cell_SNA_Mode_071 BCC_U_Cell_SNA_Mode_072 BCC_U_Cell_SNA_Mode_073 BCC_U_Cell_SNA_Mode_074 BCC_U_Cell_SNA_Mode_075 BCC_U_Cell_SNA_Mode_076 BCC_U_Cell_SNA_Mode_077 BCC_U_Cell_SNA_Mode_078 BCC_U_Cell_SNA_Mode_079 BCC_U_Cell_SNA_Mode_080 BCC_U_Cell_SNA_Mode_081 BCC_U_Cell_SNA_Mode_082 BCC_U_Cell_SNA_Mode_083 BCC_U_Cell_SNA_Mode_084 BCC_U_Cell_SNA_Mode_085 BCC_U_Cell_SNA_Mode_086 BCC_U_Cell_SNA_Mode_087 BCC_U_Cell_SNA_Mode_088 BCC_U_Cell_SNA_Mode_089 BCC_U_Cell_SNA_Mode_090 BCC_U_Cell_SNA_Mode_091 BCC_U_Cell_SNA_Mode_092 BCC_U_Cell_SNA_Mode_093 BCC_U_Cell_SNA_Mode_065 BCC_U_Cell_SNA_Mode_066 BCC_U_Cell_SNA_Mode_067 BCC_U_Cell_SNA_Mode_068 BCC_U_Cell_SNA_Mode_069 BCC_U_Cell_SNA_Mode_070;
SIG_GROUP_ 304 GR_BCC_IN_T_BATT 1 : BCC_T_Batt BCC_T_Batt_SNA_Mode_01 BCC_T_Batt_SNA_Mode_02 BCC_T_Batt_SNA_Mode_03 BCC_T_Batt_SNA_Mode_04 BCC_T_Batt_SNA_Mode_05 BCC_T_Batt_SNA_Mode_06 BCC_T_Batt_SNA_Mode_07 BCC_T_Batt_SNA_Mode_08 BCC_T_Batt_SNA_Mode_09 BCC_T_Batt_SNA_Mode_10 BCC_T_Batt_SNA_Mode_11 BCC_T_Batt_SNA_Mode_12 BCC_T_Batt_SNA_Mode_13 BCC_T_Batt_SNA_Mode_14 BCC_T_Batt_SNA_Mode_15 BCC_T_Batt_SNA_Mode_16 BCC_T_Batt_SNA_Mode_17 BCC_T_Batt_SNA_Mode_18 BCC_T_Batt_SNA_Mode_19 BCC_T_Batt_SNA_Mode_20 BCC_T_Batt_SNA_Mode_21 BCC_T_Batt_SNA_Mode_22 BCC_T_Batt_SNA_Mode_23 BCC_T_Batt_SNA_Mode_24 BCC_T_Batt_SNA_Mode_25 BCC_T_Batt_SNA_Mode_26 BCC_T_Batt_SNA_Mode_27 BCC_T_Batt_SNA_Mode_28 BCC_T_Batt_SNA_Mode_29 BCC_T_Batt_SNA_Mode_30;
SIG_GROUP_ 560 GR_BCC_OUT_ACTUAL_U_I 1 : BCASO_I_Batt_Filtered BCASO_U_Batt_Sum_of_U_Cell;
SIG_GROUP_ 563 GR_BCC_OUT_FLAGS_REQS_MODES 1 : BCASO_Cell_Error BCASO_NoCurr_Req BCASO_Bal_Finished_Mode BCASO_Diag_Capa_Mode BCASO_Diag_OCV_Mode BCASO_OCV_Mode BCASO_Recalibrate_Req BCASO_Run_Req BCASO_SwitchOpenChargeEnd_Rq;
SIG_GROUP_ 572 GR_BCC_OUT_U_CELL_MAX_MIN 1 : BCASO_U_Cell_Max BCASO_U_Cell_Min;
SIG_GROUP_ 570 GR_BCC_OUT_TEMP 1 : BCASO_T_Batt_Max BCASO_T_Batt_Min;
SIG_GROUP_ 562 GR_BCC_OUT_COOL 1 : BCASO_Batt_Cool_Req BCASO_ChillerValve_Cmd BCASO_CoolValve_Req BCASO_Fan_Cmd BCASO_SwitchingValve_Cmd BCASO_CoolAmount_Rq BCASO_CoolantInletTemp BCASO_Waterpump_Cmd;
SIG_GROUP_ 561 GR_BCC_OUT_CAPA 1 : BCASO_CapaHV_As_act_1 BCASO_CapaHV_As_ref_1;
SIG_GROUP_ 569 GR_BCC_OUT_SOC_MAX_MIN 1 : BCASO_SOC_Max BCASO_SOC_Min;
SIG_GROUP_ 568 GR_BCC_OUT_SOC 1 : BCASO_SOC BCASO_SOC_Disp;
SIG_GROUP_ 330 GR_BCC_IN_U_CELL_SNA_001_064 1 : BCC_U_Cell_SNA_Mode_001 BCC_U_Cell_SNA_Mode_002 BCC_U_Cell_SNA_Mode_003 BCC_U_Cell_SNA_Mode_004 BCC_U_Cell_SNA_Mode_005 BCC_U_Cell_SNA_Mode_006 BCC_U_Cell_SNA_Mode_007 BCC_U_Cell_SNA_Mode_008 BCC_U_Cell_SNA_Mode_009 BCC_U_Cell_SNA_Mode_011 BCC_U_Cell_SNA_Mode_010 BCC_U_Cell_SNA_Mode_012 BCC_U_Cell_SNA_Mode_013 BCC_U_Cell_SNA_Mode_014 BCC_U_Cell_SNA_Mode_015 BCC_U_Cell_SNA_Mode_016 BCC_U_Cell_SNA_Mode_017 BCC_U_Cell_SNA_Mode_018 BCC_U_Cell_SNA_Mode_019 BCC_U_Cell_SNA_Mode_020 BCC_U_Cell_SNA_Mode_021 BCC_U_Cell_SNA_Mode_022 BCC_U_Cell_SNA_Mode_023 BCC_U_Cell_SNA_Mode_024 BCC_U_Cell_SNA_Mode_025 BCC_U_Cell_SNA_Mode_026 BCC_U_Cell_SNA_Mode_027 BCC_U_Cell_SNA_Mode_028 BCC_U_Cell_SNA_Mode_029 BCC_U_Cell_SNA_Mode_030 BCC_U_Cell_SNA_Mode_031 BCC_U_Cell_SNA_Mode_032 BCC_U_Cell_SNA_Mode_033 BCC_U_Cell_SNA_Mode_034 BCC_U_Cell_SNA_Mode_035 BCC_U_Cell_SNA_Mode_036 BCC_U_Cell_SNA_Mode_037 BCC_U_Cell_SNA_Mode_038 BCC_U_Cell_SNA_Mode_039 BCC_U_Cell_SNA_Mode_040 BCC_U_Cell_SNA_Mode_041 BCC_U_Cell_SNA_Mode_042 BCC_U_Cell_SNA_Mode_043 BCC_U_Cell_SNA_Mode_044 BCC_U_Cell_SNA_Mode_045 BCC_U_Cell_SNA_Mode_046 BCC_U_Cell_SNA_Mode_047 BCC_U_Cell_SNA_Mode_048 BCC_U_Cell_SNA_Mode_049 BCC_U_Cell_SNA_Mode_050 BCC_U_Cell_SNA_Mode_051 BCC_U_Cell_SNA_Mode_052 BCC_U_Cell_SNA_Mode_053 BCC_U_Cell_SNA_Mode_054 BCC_U_Cell_SNA_Mode_055 BCC_U_Cell_SNA_Mode_056 BCC_U_Cell_SNA_Mode_057 BCC_U_Cell_SNA_Mode_058 BCC_U_Cell_SNA_Mode_059 BCC_U_Cell_SNA_Mode_060 BCC_U_Cell_SNA_Mode_061 BCC_U_Cell_SNA_Mode_062 BCC_U_Cell_SNA_Mode_063 BCC_U_Cell_SNA_Mode_064;
SIG_GROUP_ 564 GR_BCC_OUT_LIMITS_I 1 : BCASO_I_Max_Chrg BCASO_I_Max_DisChrg;
SIG_GROUP_ 565 GR_BCC_OUT_LIMITS_U 1 : BCASO_U_Max BCASO_U_Min;
SIG_GROUP_ 585 GR_BCC_OUT_OCV_19_20 1 : BCASO_OCV_Arr21_1mV_19 BCASO_OCV_Arr21_1mV_20;
SIG_GROUP_ 584 GR_BCC_OUT_OCV_17_18 1 : BCASO_OCV_Arr21_1mV_17 BCASO_OCV_Arr21_1mV_18;
SIG_GROUP_ 583 GR_BCC_OUT_OCV_15_16 1 : BCASO_OCV_Arr21_1mV_15 BCASO_OCV_Arr21_1mV_16;
SIG_GROUP_ 582 GR_BCC_OUT_OCV_13_14 1 : BCASO_OCV_Arr21_1mV_13 BCASO_OCV_Arr21_1mV_14;
SIG_GROUP_ 581 GR_BCC_OUT_OCV_11_12 1 : BCASO_OCV_Arr21_1mV_11 BCASO_OCV_Arr21_1mV_12;
SIG_GROUP_ 580 GR_BCC_OUT_OCV_09_10 1 : BCASO_OCV_Arr21_1mV_09 BCASO_OCV_Arr21_1mV_10;
SIG_GROUP_ 579 GR_BCC_OUT_OCV_07_08 1 : BCASO_OCV_Arr21_1mV_07 BCASO_OCV_Arr21_1mV_08;
SIG_GROUP_ 578 GR_BCC_OUT_OCV_05_06 1 : BCASO_OCV_Arr21_1mV_05 BCASO_OCV_Arr21_1mV_06;
SIG_GROUP_ 577 GR_BCC_OUT_OCV_03_04 1 : BCASO_OCV_Arr21_1mV_03 BCASO_OCV_Arr21_1mV_04;
SIG_GROUP_ 576 GR_BCC_OUT_OCV_01_02 1 : BCASO_OCV_Arr21_1mV_01 BCASO_OCV_Arr21_1mV_02;
SIG_GROUP_ 566 GR_BCC_OUT_PP_LONG 1 : BCASO_I_Chrg_long BCASO_U_Chrg_long BCASO_I_Dchrg_long BCASO_U_Dchrg_long;
SIG_GROUP_ 567 GR_BCC_OUT_PP_SHORT 1 : BCASO_I_Chrg_short BCASO_U_Chrg_short BCASO_I_Dchrg_short BCASO_U_Dchrg_short;
SIG_GROUP_ 657 GR_BCC_OUT_DIAG_BALANCING_STAT_2 1 : BCASO_Balacing_Stat_09 BCASO_Balacing_Stat_10 BCASO_Balacing_Stat_11;
SIG_GROUP_ 656 GR_BCC_OUT_DIAG_BALANCING_STAT_1 1 : BCASO_Balacing_Stat_01 BCASO_Balacing_Stat_02 BCASO_Balacing_Stat_03 BCASO_Balacing_Stat_04 BCASO_Balacing_Stat_05 BCASO_Balacing_Stat_06 BCASO_Balacing_Stat_07 BCASO_Balacing_Stat_08;
SIG_GROUP_ 593 GR_BCC_OUT_BALANCING_065_128 1 : BCASO_Cell_Bal_Req_100 BCASO_Cell_Bal_Req_099 BCASO_Cell_Bal_Req_098 BCASO_Cell_Bal_Req_097 BCASO_Cell_Bal_Req_096 BCASO_Cell_Bal_Req_095 BCASO_Cell_Bal_Req_094 BCASO_Cell_Bal_Req_071 BCASO_Cell_Bal_Req_072 BCASO_Cell_Bal_Req_073 BCASO_Cell_Bal_Req_074 BCASO_Cell_Bal_Req_075 BCASO_Cell_Bal_Req_076 BCASO_Cell_Bal_Req_077 BCASO_Cell_Bal_Req_078 BCASO_Cell_Bal_Req_079 BCASO_Cell_Bal_Req_080 BCASO_Cell_Bal_Req_081 BCASO_Cell_Bal_Req_082 BCASO_Cell_Bal_Req_083 BCASO_Cell_Bal_Req_084 BCASO_Cell_Bal_Req_085 BCASO_Cell_Bal_Req_086 BCASO_Cell_Bal_Req_087 BCASO_Cell_Bal_Req_088 BCASO_Cell_Bal_Req_089 BCASO_Cell_Bal_Req_090 BCASO_Cell_Bal_Req_091 BCASO_Cell_Bal_Req_092 BCASO_Cell_Bal_Req_093 BCASO_Cell_Bal_Req_065 BCASO_Cell_Bal_Req_066 BCASO_Cell_Bal_Req_067 BCASO_Cell_Bal_Req_068 BCASO_Cell_Bal_Req_069 BCASO_Cell_Bal_Req_070;
SIG_GROUP_ 592 GR_BCC_OUT_BALANCING_001_064 1 : BCASO_Cell_Bal_Req_001 BCASO_Cell_Bal_Req_002 BCASO_Cell_Bal_Req_003 BCASO_Cell_Bal_Req_004 BCASO_Cell_Bal_Req_005 BCASO_Cell_Bal_Req_006 BCASO_Cell_Bal_Req_007 BCASO_Cell_Bal_Req_008 BCASO_Cell_Bal_Req_009 BCASO_Cell_Bal_Req_010 BCASO_Cell_Bal_Req_011 BCASO_Cell_Bal_Req_012 BCASO_Cell_Bal_Req_013 BCASO_Cell_Bal_Req_014 BCASO_Cell_Bal_Req_015 BCASO_Cell_Bal_Req_016 BCASO_Cell_Bal_Req_017 BCASO_Cell_Bal_Req_018 BCASO_Cell_Bal_Req_019 BCASO_Cell_Bal_Req_020 BCASO_Cell_Bal_Req_021 BCASO_Cell_Bal_Req_022 BCASO_Cell_Bal_Req_023 BCASO_Cell_Bal_Req_024 BCASO_Cell_Bal_Req_025 BCASO_Cell_Bal_Req_026 BCASO_Cell_Bal_Req_027 BCASO_Cell_Bal_Req_028 BCASO_Cell_Bal_Req_029 BCASO_Cell_Bal_Req_030 BCASO_Cell_Bal_Req_031 BCASO_Cell_Bal_Req_032 BCASO_Cell_Bal_Req_033 BCASO_Cell_Bal_Req_034 BCASO_Cell_Bal_Req_035 BCASO_Cell_Bal_Req_036 BCASO_Cell_Bal_Req_037 BCASO_Cell_Bal_Req_038 BCASO_Cell_Bal_Req_039 BCASO_Cell_Bal_Req_040 BCASO_Cell_Bal_Req_041 BCASO_Cell_Bal_Req_042 BCASO_Cell_Bal_Req_043 BCASO_Cell_Bal_Req_044 BCASO_Cell_Bal_Req_045 BCASO_Cell_Bal_Req_046 BCASO_Cell_Bal_Req_047 BCASO_Cell_Bal_Req_048 BCASO_Cell_Bal_Req_049 BCASO_Cell_Bal_Req_050 BCASO_Cell_Bal_Req_051 BCASO_Cell_Bal_Req_052 BCASO_Cell_Bal_Req_053 BCASO_Cell_Bal_Req_054 BCASO_Cell_Bal_Req_055 BCASO_Cell_Bal_Req_056 BCASO_Cell_Bal_Req_057 BCASO_Cell_Bal_Req_058 BCASO_Cell_Bal_Req_059 BCASO_Cell_Bal_Req_060 BCASO_Cell_Bal_Req_061 BCASO_Cell_Bal_Req_062 BCASO_Cell_Bal_Req_063 BCASO_Cell_Bal_Req_064;
